VERSION "HNNBNNNYNNNNNNNNNNNNNNNNNNNNNNNNNNNNNNNNNN/4/%%%/4/'%**4NNN///"

NS_ :

BS_:

BU_: BAP_Tester ELV Gateway_Max HUD Kombi

BO_ 1426 Kessy_04: 8 Gateway_Max
 SG_ KY_ID_Geber1_im_Fzg : 12|1@1+ (1.0,0.0) [0.0|1] ""  Vector__XXX
 SG_ KY_ID_Geber2_im_Fzg : 13|1@1+ (1.0,0.0) [0.0|1] ""  Vector__XXX
 SG_ KY_ID_Geber3_im_Fzg : 14|1@1+ (1.0,0.0) [0.0|1] ""  Vector__XXX
 SG_ KY_ID_Geber4_im_Fzg : 15|1@1+ (1.0,0.0) [0.0|1] ""  Vector__XXX
 SG_ KY_Startknopf_Bel : 16|1@1+ (1.0,0.0) [0.0|1] ""  Vector__XXX
 SG_ KY_ID_Geber_Suche : 17|1@1+ (1.0,0.0) [0.0|1] ""  Vector__XXX
 SG_ KY_Meldungen : 18|4@1+ (1.0,0.0) [0.0|15] ""  Vector__XXX
 SG_ KY_Gong_600 : 22|1@1+ (1.0,0.0) [0.0|1] ""  Vector__XXX
 SG_ KY_Passiv_Autolock_Menue : 23|1@1+ (1.0,0.0) [0.0|1] ""  Vector__XXX
 SG_ KY_Passiv_Autolock_Akt : 24|1@1+ (1.0,0.0) [0.0|1] ""  Vector__XXX
 SG_ KY_Passiv_Autolock : 25|1@1+ (1.0,0.0) [0.0|1] ""  Vector__XXX
 SG_ KY_Passiv_Autounlock : 26|1@1+ (1.0,0.0) [0.0|1] ""  Vector__XXX
 SG_ KY_Gestik_HD : 27|1@1+ (1.0,0.0) [0.0|1] ""  Vector__XXX
 SG_ KY_StartStopp_Info : 28|2@1+ (1.0,0.0) [0.0|3] ""  Vector__XXX
 SG_ KY_Fzg_Verlassen_erkannt : 30|1@1+ (1.0,0.0) [0.0|1] ""  ELV
 SG_ KY_Fzg_Zugang_erkannt : 31|1@1+ (1.0,0.0) [0.0|1] ""  ELV
 SG_ KY_EasyClose_Abbruch : 32|1@1+ (1.0,0.0) [0.0|1] ""  Vector__XXX
 SG_ KY_EasyClose_Status : 33|3@1+ (1.0,0.0) [0.0|7] ""  Vector__XXX
 SG_ KY_HD_Auffahrt : 36|1@1+ (1.0,0.0) [0.0|1] ""  Vector__XXX
 SG_ KY_HD_Zufahrt : 37|1@1+ (1.0,0.0) [0.0|1] ""  Vector__XXX
 SG_ KY_Aktive_LFScans : 38|4@1+ (1.0,0.0) [0.0|15] ""  Vector__XXX
 SG_ KY_LF_Aktiv : 42|1@1+ (1.0,0.0) [0.0|1] ""  Vector__XXX
 SG_ KY_AnzKoord_Info : 43|2@1+ (1.0,0.0) [0.0|3] ""  Vector__XXX
 SG_ KY_Schluesselposition_9 : 45|2@1+ (1.0,0.0) [0.0|3] ""  Vector__XXX
 SG_ KY_Schluesselposition_1 : 48|2@1+ (1.0,0.0) [0.0|3] ""  Vector__XXX
 SG_ KY_Schluesselposition_2 : 50|2@1+ (1.0,0.0) [0.0|3] ""  Vector__XXX
 SG_ KY_Schluesselposition_3 : 52|2@1+ (1.0,0.0) [0.0|3] ""  Vector__XXX
 SG_ KY_Schluesselposition_4 : 54|2@1+ (1.0,0.0) [0.0|3] ""  Vector__XXX
 SG_ KY_Schluesselposition_5 : 56|2@1+ (1.0,0.0) [0.0|3] ""  Vector__XXX
 SG_ KY_Schluesselposition_6 : 58|2@1+ (1.0,0.0) [0.0|3] ""  Vector__XXX
 SG_ KY_Schluesselposition_7 : 60|2@1+ (1.0,0.0) [0.0|3] ""  Vector__XXX
 SG_ KY_Schluesselposition_8 : 62|2@1+ (1.0,0.0) [0.0|3] ""  Vector__XXX

BO_ 960 Klemmen_Status_01: 4 Gateway_Max
 SG_ Klemmen_Status_01_CRC : 0|8@1+ (1,0) [0|255] ""  ELV,Kombi
 SG_ Klemmen_Status_01_BZ : 8|4@1+ (1,0) [0|15] ""  ELV,Kombi
 SG_ RSt_Fahrerhinweise : 12|4@1+ (1.0,0.0) [0.0|15] ""  Kombi
 SG_ ZAS_Kl_S : 16|1@1+ (1.0,0.0) [0.0|1] ""  ELV,Kombi
 SG_ ZAS_Kl_15 : 17|1@1+ (1.0,0.0) [0.0|1] ""  ELV,HUD,Kombi
 SG_ ZAS_Kl_X : 18|1@1+ (1.0,0.0) [0.0|1] ""  Vector__XXX
 SG_ ZAS_Kl_50_Startanforderung : 19|1@1+ (1.0,0.0) [0.0|1] ""  Vector__XXX
 SG_ BCM_Remotestart_Betrieb : 20|1@1+ (1.0,0.0) [0.0|1] ""  Vector__XXX
 SG_ ZAS_Kl_Infotainment : 21|1@1+ (1.0,0.0) [0.0|1] ""  Vector__XXX
 SG_ BCM_Remotestart_KL15_Anf : 22|1@1+ (1.0,0.0) [0.0|1] ""  ELV,Kombi
 SG_ BCM_Remotestart_MO_Start : 23|1@1+ (1.0,0.0) [0.0|1] ""  Vector__XXX
 SG_ KST_Warn_P1_ZST_def : 24|1@1+ (1.0,0.0) [0.0|1] ""  Vector__XXX
 SG_ KST_Warn_P2_ZST_def : 25|1@1+ (1.0,0.0) [0.0|1] ""  Kombi
 SG_ KST_Fahrerhinweis_1 : 26|1@1+ (1.0,0.0) [0.0|1] ""  Vector__XXX
 SG_ KST_Fahrerhinweis_2 : 27|1@1+ (1.0,0.0) [0.0|1] ""  Kombi
 SG_ BCM_Ausparken_Betrieb : 28|1@1+ (1.0,0.0) [0.0|1] ""  Vector__XXX
 SG_ KST_Fahrerhinweis_4 : 29|1@1+ (1.0,0.0) [0.0|1] ""  Vector__XXX
 SG_ KST_Fahrerhinweis_5 : 30|1@1+ (1.0,0.0) [0.0|1] ""  Vector__XXX
 SG_ KST_Fahrerhinweis_6 : 31|1@1+ (1.0,0.0) [0.0|1] ""  Kombi

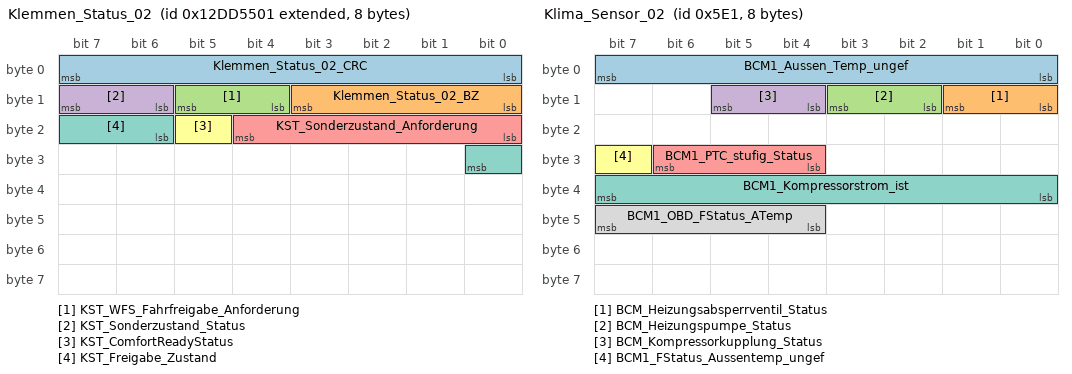
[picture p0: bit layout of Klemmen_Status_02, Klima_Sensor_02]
BO_ 2463978753 Klemmen_Status_02: 8 Gateway_Max
 SG_ Klemmen_Status_02_CRC : 0|8@1+ (1,0) [0|255] ""  Vector__XXX
 SG_ Klemmen_Status_02_BZ : 8|4@1+ (1,0) [0|15] ""  Vector__XXX
 SG_ KST_WFS_Fahrfreigabe_Anforderung : 12|2@1+ (1.0,0.0) [0.0|3] ""  Vector__XXX
 SG_ KST_Sonderzustand_Status : 14|2@1+ (1.0,0.0) [0.0|3] ""  ELV
 SG_ KST_Sonderzustand_Anforderung : 16|5@1+ (1.0,0.0) [0.0|31] ""  ELV
 SG_ KST_ComfortReadyStatus : 21|1@1+ (1.0,0.0) [0.0|1] ""  Vector__XXX
 SG_ KST_Freigabe_Zustand : 22|3@1+ (1.0,0.0) [0.0|7] ""  Vector__XXX

BO_ 1420 Klemmen_Steuerung_01: 8 Gateway_Max
 SG_ Klemmen_Steuerung_01_CRC : 0|8@1+ (1,0) [0|255] ""  ELV
 SG_ Klemmen_Steuerung_01_BZ : 8|4@1+ (1,0) [0|15] ""  ELV
 SG_ KST_Anf_Klemme_15 : 12|1@1+ (1.0,0.0) [0.0|1] ""  Vector__XXX
 SG_ KST_Anf_Klemme_50 : 13|1@1+ (1.0,0.0) [0.0|1] ""  Vector__XXX
 SG_ KST_Anf_Klemme_S : 14|1@1+ (1.0,0.0) [0.0|1] ""  Vector__XXX
 SG_ KST_Txt_Werkstatt : 15|1@1+ (1.0,0.0) [0.0|1] ""  Kombi
 SG_ KST_Txt_P_Gang : 16|1@1+ (1.0,0.0) [0.0|1] ""  Kombi
 SG_ KST_Txt_Panikabschaltung : 17|1@1+ (1.0,0.0) [0.0|1] ""  Kombi
 SG_ KST_Anf_Klemmenfreigabe_ELV : 18|1@1+ (1.0,0.0) [0.0|1] ""  ELV
 SG_ KST_Txt_Komfortabschaltung : 19|1@1+ (1.0,0.0) [0.0|1] ""  Kombi
 SG_ KST_ZAT_betaetigt : 20|1@1+ (1.0,0.0) [0.0|1] ""  Vector__XXX
 SG_ KST_Unterdr_Zuendungsmeldung : 21|1@1+ (1.0,0.0) [0.0|1] ""  Vector__XXX
 SG_ KST_aut_Abschaltung_Zuendung : 22|1@1+ (1.0,0.0) [0.0|1] ""  Vector__XXX
 SG_ KST_Anf_Klemmenfreigabe_WFS : 23|1@1+ (1.0,0.0) [0.0|1] ""  Vector__XXX
 SG_ KST_Anf_ZV_Verriegelung : 24|1@1+ (1.0,0.0) [0.0|1] ""  Vector__XXX
 SG_ Relais_VoKo_angesteuert : 25|1@1+ (1.0,0.0) [0.0|1] ""  Vector__XXX
 SG_ RSt_Anforderung_HMS : 26|3@1+ (1.0,0.0) [0.0|7] ""  Vector__XXX
 SG_ KST_Zuendungswarnung : 29|2@1+ (1.0,0.0) [0.0|3] ""  Kombi
 SG_ KST_Anzeige_Klemmenzustand : 36|3@1+ (1.0,0.0) [0.0|7] ""  Kombi

BO_ 1646 Klima_03: 8 Gateway_Max
 SG_ KL_STL_aktiv : 0|1@1+ (1.0,0.0) [0.0|1] ""  Vector__XXX
 SG_ KL_STH_aktiv : 1|1@1+ (1.0,0.0) [0.0|1] ""  Vector__XXX
 SG_ KL_Solarluefter_aktiv : 2|1@1+ (1.0,0.0) [0.0|1] ""  Vector__XXX
 SG_ KL_Umluft_Taste : 3|1@1+ (1.0,0.0) [0.0|1] ""  Vector__XXX
 SG_ KL_Geblaese_Fond_Status : 4|4@1+ (1.0,0.0) [0.0|15] ""  Vector__XXX
 SG_ KL_STH_Ansteuerung : 8|2@1+ (1.0,0.0) [0.0|3] ""  Vector__XXX
 SG_ KL_STH_Betriebsdauer : 10|6@1+ (1,0) [0|60] "Unit_Minut"  Vector__XXX
 SG_ KL_Magnetventil : 16|1@1+ (1.0,0.0) [0.0|1] ""  Vector__XXX
 SG_ KL_WaPu : 17|1@1+ (1.0,0.0) [0.0|1] ""  Vector__XXX
 SG_ KL_Geblaese_Status : 18|4@1+ (1.0,0.0) [0.0|15] ""  Kombi
 SG_ KL_Restwaerme_aktiv : 22|1@1+ (1.0,0.0) [0.0|1] ""  Vector__XXX
 SG_ KL_Kompressorkupplung : 23|1@1+ (1.0,0.0) [0.0|1] ""  Vector__XXX
 SG_ KL_BCmE_Livetip_Freigabe : 24|1@1+ (1.0,0.0) [0.0|1] ""  Vector__XXX
 SG_ KL_SH_Soll_hl : 25|3@1+ (1.0,0.0) [0.0|7] ""  Vector__XXX
 SG_ KL_SH_Soll_hr : 28|3@1+ (1.0,0.0) [0.0|7] ""  Vector__XXX
 SG_ KL_ErwVK_Anf : 31|1@1+ (1.0,0.0) [0.0|1] ""  Vector__XXX
 SG_ KL_Innen_Temp : 32|8@1+ (0.5,-50) [-50.0|76.0] "Unit_DegreCelsi"  Vector__XXX
 SG_ KL_I_Geblaese_Fond : 40|8@1+ (0.25,0) [0.00|63.50] "Unit_Amper"  Vector__XXX
 SG_ KL_Anf_AussenspiegelHzg : 48|1@1+ (1.0,0.0) [0.0|1] ""  Vector__XXX
 SG_ KL_Heizkreisventilstellung : 49|2@1+ (1.0,0.0) [0.0|3] ""  Vector__XXX
 SG_ KL_FSH_Automatikbetrieb : 51|1@1+ (1.0,0.0) [0.0|1] ""  Vector__XXX
 SG_ KL_SIH_LEH_Verteilung_VL : 52|3@1+ (1.0,0.0) [0.0|7] ""  Vector__XXX
 SG_ KL_SIH_LEL_Verteilung_VL : 55|3@1+ (1.0,0.0) [0.0|7] ""  Vector__XXX
 SG_ KL_SIH_LEH_Verteilung_VR : 58|3@1+ (1.0,0.0) [0.0|7] ""  Vector__XXX
 SG_ KL_SIH_LEL_Verteilung_VR : 61|3@1+ (1.0,0.0) [0.0|7] ""  Vector__XXX

BO_ 949 Klima_11: 8 Gateway_Max
 SG_ KL_Drehz_Anh : 0|1@1+ (1.0,0.0) [0.0|1] ""  Vector__XXX
 SG_ KL_Vorwarn_Komp_ein : 1|1@1+ (1.0,0.0) [0.0|1] ""  Vector__XXX
 SG_ KL_AC_Schalter : 2|1@1+ (1.0,0.0) [0.0|1] ""  Vector__XXX
 SG_ KL_Komp_Moment_alt : 3|1@1+ (1.0,0.0) [0.0|1] ""  Vector__XXX
 SG_ KL_Vorwarn_Zuheizer_ein : 6|1@1+ (1.0,0.0) [0.0|1] ""  Vector__XXX
 SG_ KL_Zustand : 7|1@1+ (1.0,0.0) [0.0|1] ""  Vector__XXX
 SG_ KL_Kompressorkupplung_linear : 8|8@1+ (20,0) [0|4000] "Unit_MilliAmper"  Vector__XXX
 SG_ KL_Charisma_FahrPr : 16|4@1+ (1.0,0.0) [0.0|15] ""  Vector__XXX
 SG_ KL_Charisma_Status : 20|2@1+ (1.0,0.0) [0.0|3] ""  Vector__XXX
 SG_ KL_nachtr_Stopp_Anf : 22|1@1+ (1.0,0.0) [0.0|1] ""  Vector__XXX
 SG_ KL_T_Charge : 23|1@1+ (1.0,0.0) [0.0|1] ""  Vector__XXX
 SG_ KL_Last_Kompr : 24|8@1+ (0.25,0) [0.00|63.50] "Unit_NewtoMeter"  Vector__XXX
 SG_ KL_Spannungs_Anf : 32|2@1+ (1.0,0.0) [0.0|3] ""  Vector__XXX
 SG_ KL_Thermomanagement : 34|2@1+ (1.0,0.0) [0.0|3] ""  Vector__XXX
 SG_ KL_StartStopp_Info : 36|2@1+ (1.0,0.0) [0.0|3] ""  Vector__XXX
 SG_ KL_Freilauf_Info : 38|2@1+ (1.0,0.0) [0.0|3] ""  Vector__XXX
 SG_ KL_Anf_KL : 40|8@1+ (0.4,0) [0.0|101.6] "Unit_PerCent"  Vector__XXX
 SG_ KL_el_Zuheizer_Stufe : 48|3@1+ (1.0,0.0) [0.0|7] ""  Vector__XXX
 SG_ KL_Ausstattung_Klima : 51|3@1+ (1.0,0.0) [0.0|7] ""  Vector__XXX
 SG_ KL_Variante_Standheizung : 54|2@1+ (1.0,0.0) [0.0|3] ""  Vector__XXX
 SG_ KL_AirCleaner_aktiv : 56|1@1+ (1.0,0.0) [0.0|1] ""  Vector__XXX
 SG_ KL_Anf_KV : 57|7@1+ (1,0) [0|100] "Unit_PerCent"  Vector__XXX

BO_ 1640 Klima_12: 8 Gateway_Max
 SG_ KL_LRH_Taster : 0|1@1+ (1.0,0.0) [0.0|1] ""  Vector__XXX
 SG_ KL_LRH_Stufe : 1|2@1+ (1.0,0.0) [0.0|3] ""  Kombi
 SG_ HSH_Taster : 3|2@1+ (1.0,0.0) [0.0|3] ""  Vector__XXX
 SG_ FSH_Taster : 5|1@1+ (1.0,0.0) [0.0|1] ""  Vector__XXX
 SG_ KL_Zuheizer_Freigabe : 6|1@1+ (1.0,0.0) [0.0|1] ""  Vector__XXX
 SG_ KL_Beschlagsgefahr : 7|1@1+ (1.0,0.0) [0.0|1] ""  Vector__XXX
 SG_ KL_SIH_Soll_li : 8|3@1+ (1,0) [0|6] ""  Vector__XXX
 SG_ KL_SIH_Soll_re : 11|3@1+ (1,0) [0|6] ""  Vector__XXX
 SG_ KRH_Soll_li : 14|2@1+ (1.0,0.0) [0.0|3] ""  Vector__XXX
 SG_ KL_SIL_Soll_li : 16|3@1+ (1,0) [0|6] ""  Vector__XXX
 SG_ KL_SIL_Soll_re : 19|3@1+ (1,0) [0|6] ""  Vector__XXX
 SG_ KRH_Soll_re : 22|2@1+ (1.0,0.0) [0.0|3] ""  Vector__XXX
 SG_ KL_Geblspng_Soll : 24|8@1+ (0.05,1.45) [1.50|14.00] "Unit_Volt"  Vector__XXX
 SG_ KL_Geblspng_Fond_Soll : 32|8@1+ (0.05,1.45) [1.50|14.00] "Unit_Volt"  Vector__XXX
 SG_ KL_I_Geblaese : 40|8@1+ (0.25,0) [0.00|63.50] "Unit_Amper"  Vector__XXX
 SG_ KL_Kompressorstrom_soll : 48|10@1+ (1,0) [0|1021] ""  Vector__XXX
 SG_ KL_Umluftklappe_Status : 58|4@1+ (1.0,0.0) [0.0|15] ""  Vector__XXX
 SG_ KL_PTC_Verbauinfo : 62|2@1+ (1.0,0.0) [0.0|3] ""  Vector__XXX

BO_ 2527679635 Klima_16: 8 Gateway_Max
 SG_ KL_Voko_Status : 0|4@1+ (1.0,0.0) [0.0|15] ""  Vector__XXX
 SG_ KL_LRH_PWM : 4|7@1+ (1,0) [0|100] "Unit_PerCent"  Vector__XXX
 SG_ KL_LRH_Soll : 11|1@1+ (1.0,0.0) [0.0|1] ""  Vector__XXX
 SG_ KL_AL_VR_Anf : 12|2@1+ (1.0,0.0) [0.0|3] ""  Vector__XXX
 SG_ KL_AL_VL_Anf : 14|2@1+ (1.0,0.0) [0.0|3] ""  Vector__XXX
 SG_ KL_AL_HR_Anf : 16|2@1+ (1.0,0.0) [0.0|3] ""  Vector__XXX
 SG_ KL_AL_HL_Anf : 18|2@1+ (1.0,0.0) [0.0|3] ""  Vector__XXX
 SG_ KL_HSH_Soll : 20|1@1+ (1.0,0.0) [0.0|1] ""  Vector__XXX
 SG_ KL_FSH_Soll : 21|1@1+ (1.0,0.0) [0.0|1] ""  Vector__XXX
 SG_ KL_ZR_Anforderung : 22|2@1+ (1.0,0.0) [0.0|3] ""  Vector__XXX
 SG_ KL_VoKo_LED : 24|1@1+ (1.0,0.0) [0.0|1] ""  Vector__XXX
 SG_ KL_Defrost_LED : 25|1@1+ (1.0,0.0) [0.0|1] ""  Vector__XXX
 SG_ KL_HSH_LED : 26|1@1+ (1.0,0.0) [0.0|1] ""  Vector__XXX
 SG_ HSH_Relais_Anf : 27|1@1+ (1.0,0.0) [0.0|1] ""  Vector__XXX
 SG_ FSH_Status : 28|2@1+ (1.0,0.0) [0.0|3] ""  Vector__XXX
 SG_ SIH_Stufe_LED_li : 30|3@1+ (1.0,0.0) [0.0|7] ""  Vector__XXX
 SG_ SIH_Stufe_LED_re : 33|3@1+ (1.0,0.0) [0.0|7] ""  Vector__XXX
 SG_ KL_FSH_LED : 36|1@1+ (1.0,0.0) [0.0|1] ""  Vector__XXX
 SG_ KL_HUP_aktiv : 37|1@1+ (1.0,0.0) [0.0|1] ""  Vector__XXX
 SG_ KL_LSH_DBetr_Ein : 38|1@1+ (1.0,0.0) [0.0|1] ""  Vector__XXX
 SG_ KL_LSH_DBetr_Bestaet : 39|1@1+ (1.0,0.0) [0.0|1] ""  Vector__XXX
 SG_ KL_Klappe_Status : 40|3@1+ (1.0,0.0) [0.0|7] ""  Vector__XXX
 SG_ KL_LSH_Ansteuerung : 43|2@1+ (1.0,0.0) [0.0|3] ""  Vector__XXX
 SG_ KL_Heizstufe_LSH : 45|4@1+ (1.0,0.0) [0.0|15] ""  Vector__XXX
 SG_ KL_LSH_Betriebsdauer : 49|7@1+ (1,0) [0|120] "Unit_Minut"  Vector__XXX
 SG_ KL_Temp_ZH_Soll : 56|8@1+ (0.5,0) [0.5|127.0] "Unit_DegreCelsi"  Vector__XXX

BO_ 1505 Klima_Sensor_02: 8 Gateway_Max
 SG_ BCM1_Aussen_Temp_ungef : 0|8@1+ (0.5,-50) [-50.0|76.0] "Unit_DegreCelsi"  Kombi
 SG_ BCM_Heizungsabsperrventil_Status : 8|2@1+ (1.0,0.0) [0.0|3] ""  Vector__XXX
 SG_ BCM_Heizungspumpe_Status : 10|2@1+ (1.0,0.0) [0.0|3] ""  Vector__XXX
 SG_ BCM_Kompressorkupplung_Status : 12|2@1+ (1.0,0.0) [0.0|3] ""  Vector__XXX
 SG_ BCM1_PTC_stufig_Status : 28|3@1+ (1.0,0.0) [0.0|7] ""  Vector__XXX
 SG_ BCM1_FStatus_Aussentemp_ungef : 31|1@1+ (1.0,0.0) [0.0|1] ""  Kombi
 SG_ BCM1_Kompressorstrom_ist : 32|8@1+ (4,0) [0|1000] "Unit_MilliAmper"  Vector__XXX
 SG_ BCM1_OBD_FStatus_ATemp : 44|4@1+ (1.0,0.0) [0.0|15] ""  Vector__XXX

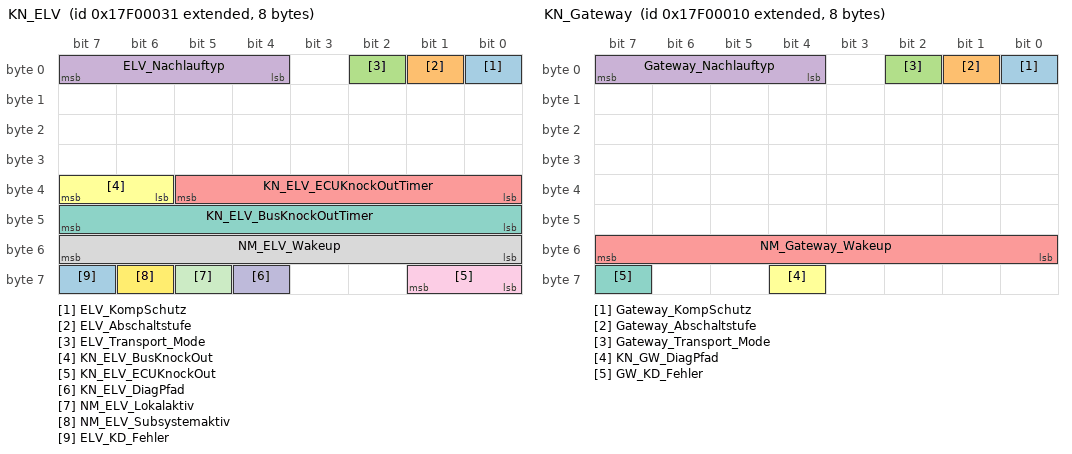
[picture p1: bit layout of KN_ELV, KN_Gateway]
BO_ 2549088305 KN_ELV: 8 ELV
 SG_ ELV_KompSchutz : 0|1@1+ (1.0,0.0) [0.0|1] ""  Vector__XXX
 SG_ ELV_Abschaltstufe : 1|1@1+ (1.0,0.0) [0.0|1] ""  Vector__XXX
 SG_ ELV_Transport_Mode : 2|1@1+ (1.0,0.0) [0.0|1] ""  Vector__XXX
 SG_ ELV_Nachlauftyp : 4|4@1+ (1.0,0.0) [0.0|15] ""  Gateway_Max
 SG_ KN_ELV_ECUKnockOutTimer : 32|6@1+ (1,0) [0|62] ""  Vector__XXX
 SG_ KN_ELV_BusKnockOut : 38|2@1+ (1.0,0.0) [0.0|3] ""  Vector__XXX
 SG_ KN_ELV_BusKnockOutTimer : 40|8@1+ (1,0) [0|254] ""  Vector__XXX
 SG_ NM_ELV_Wakeup : 48|8@1+ (1.0,0.0) [0.0|255] ""  Vector__XXX
 SG_ KN_ELV_ECUKnockOut : 56|2@1+ (1.0,0.0) [0.0|3] ""  Vector__XXX
 SG_ KN_ELV_DiagPfad : 60|1@1+ (1.0,0.0) [0.0|1] ""  Gateway_Max
 SG_ NM_ELV_Lokalaktiv : 61|1@1+ (1.0,0.0) [0.0|1] ""  Vector__XXX
 SG_ NM_ELV_Subsystemaktiv : 62|1@1+ (1.0,0.0) [0.0|1] ""  Vector__XXX
 SG_ ELV_KD_Fehler : 63|1@1+ (1.0,0.0) [0.0|1] ""  Gateway_Max

BO_ 2549088272 KN_Gateway: 8 Gateway_Max
 SG_ Gateway_KompSchutz : 0|1@1+ (1.0,0.0) [0.0|1] ""  Vector__XXX
 SG_ Gateway_Abschaltstufe : 1|1@1+ (1.0,0.0) [0.0|1] ""  Vector__XXX
 SG_ Gateway_Transport_Mode : 2|1@1+ (1.0,0.0) [0.0|1] ""  Vector__XXX
 SG_ Gateway_Nachlauftyp : 4|4@1+ (1.0,0.0) [0.0|15] ""  Vector__XXX
 SG_ NM_Gateway_Wakeup : 48|8@1+ (1.0,0.0) [0.0|255] ""  Vector__XXX
 SG_ KN_GW_DiagPfad : 60|1@1+ (1.0,0.0) [0.0|1] ""  Vector__XXX
 SG_ GW_KD_Fehler : 63|1@1+ (1.0,0.0) [0.0|1] ""  Vector__XXX

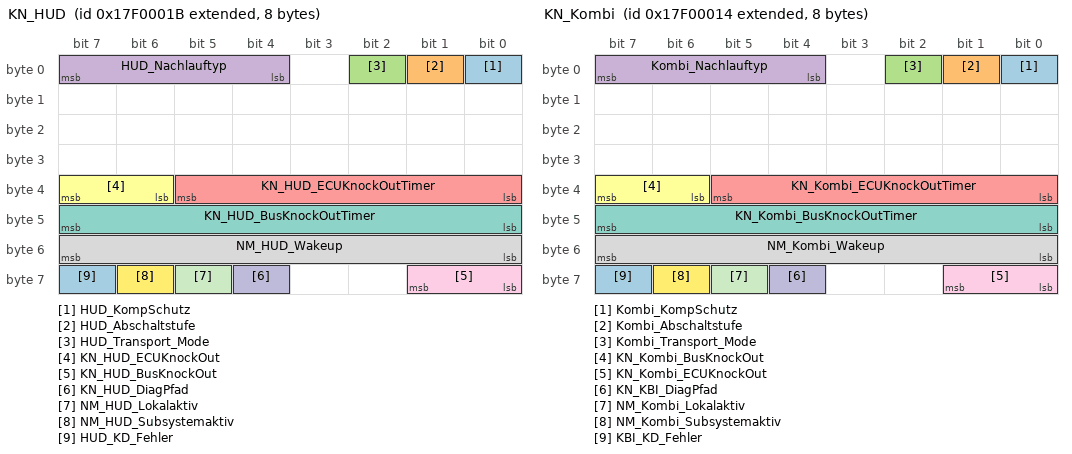
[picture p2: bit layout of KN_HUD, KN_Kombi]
BO_ 2549088283 KN_HUD: 8 HUD
 SG_ HUD_KompSchutz : 0|1@1+ (1.0,0.0) [0.0|1] ""  Vector__XXX
 SG_ HUD_Abschaltstufe : 1|1@1+ (1.0,0.0) [0.0|1] ""  Vector__XXX
 SG_ HUD_Transport_Mode : 2|1@1+ (1.0,0.0) [0.0|1] ""  Vector__XXX
 SG_ HUD_Nachlauftyp : 4|4@1+ (1.0,0.0) [0.0|15] ""  Gateway_Max
 SG_ KN_HUD_ECUKnockOutTimer : 32|6@1+ (1,0) [0|62] "Unit_Minut"  Vector__XXX
 SG_ KN_HUD_ECUKnockOut : 38|2@1+ (1.0,0.0) [0.0|3] ""  Vector__XXX
 SG_ KN_HUD_BusKnockOutTimer : 40|8@1+ (1,0) [0|254] "Unit_Minut"  Vector__XXX
 SG_ NM_HUD_Wakeup : 48|8@1+ (1.0,0.0) [0.0|255] ""  Vector__XXX
 SG_ KN_HUD_BusKnockOut : 56|2@1+ (1.0,0.0) [0.0|3] ""  Vector__XXX
 SG_ KN_HUD_DiagPfad : 60|1@1+ (1.0,0.0) [0.0|1] ""  Gateway_Max
 SG_ NM_HUD_Lokalaktiv : 61|1@1+ (1.0,0.0) [0.0|1] ""  Vector__XXX
 SG_ NM_HUD_Subsystemaktiv : 62|1@1+ (1.0,0.0) [0.0|1] ""  Vector__XXX
 SG_ HUD_KD_Fehler : 63|1@1+ (1.0,0.0) [0.0|1] ""  Gateway_Max

BO_ 2549088276 KN_Kombi: 8 Kombi
 SG_ Kombi_KompSchutz : 0|1@1+ (1.0,0.0) [0.0|1] ""  Vector__XXX
 SG_ Kombi_Abschaltstufe : 1|1@1+ (1.0,0.0) [0.0|1] ""  Vector__XXX
 SG_ Kombi_Transport_Mode : 2|1@1+ (1.0,0.0) [0.0|1] ""  Vector__XXX
 SG_ Kombi_Nachlauftyp : 4|4@1+ (1.0,0.0) [0.0|15] ""  Gateway_Max
 SG_ KN_Kombi_ECUKnockOutTimer : 32|6@1+ (1,0) [0|62] "Unit_Minut"  Vector__XXX
 SG_ KN_Kombi_BusKnockOut : 38|2@1+ (1.0,0.0) [0.0|3] ""  Vector__XXX
 SG_ KN_Kombi_BusKnockOutTimer : 40|8@1+ (1,0) [0|254] ""  Vector__XXX
 SG_ NM_Kombi_Wakeup : 48|8@1+ (1.0,0.0) [0.0|255] ""  Vector__XXX
 SG_ KN_Kombi_ECUKnockOut : 56|2@1+ (1.0,0.0) [0.0|3] ""  Vector__XXX
 SG_ KN_KBI_DiagPfad : 60|1@1+ (1.0,0.0) [0.0|1] ""  Gateway_Max
 SG_ NM_Kombi_Lokalaktiv : 61|1@1+ (1.0,0.0) [0.0|1] ""  Vector__XXX
 SG_ NM_Kombi_Subsystemaktiv : 62|1@1+ (1.0,0.0) [0.0|1] ""  Vector__XXX
 SG_ KBI_KD_Fehler : 63|1@1+ (1.0,0.0) [0.0|1] ""  Gateway_Max

BO_ 779 Kombi_01: 8 Kombi
 SG_ KBI_ABS_Lampe : 0|1@1+ (1.0,0.0) [0.0|1] ""  Gateway_Max
 SG_ KBI_ESP_Lampe : 1|1@1+ (1.0,0.0) [0.0|1] ""  Gateway_Max
 SG_ KBI_BKL_Lampe : 2|1@1+ (1.0,0.0) [0.0|1] ""  Gateway_Max
 SG_ KBI_Airbag_Lampe : 3|1@1+ (1.0,0.0) [0.0|1] ""  Gateway_Max
 SG_ KBI_SILA_gueltig : 4|1@1+ (1.0,0.0) [0.0|1] ""  Gateway_Max
 SG_ KBI_Lenkung_Lampe : 5|1@1+ (1,0) [0|1] ""  Gateway_Max
 SG_ KBI_Vorglueh_System_Lampe : 6|1@1+ (1.0,0.0) [0.0|1] ""  Gateway_Max
 SG_ KBI_NV_in_Anzeige : 7|1@1+ (1.0,0.0) [0.0|1] ""  Gateway_Max
 SG_ Kombi_01_BZ : 8|4@1+ (1,0) [0|15] ""  Gateway_Max
 SG_ KBI_Anzeigestatus_ACC : 12|1@1+ (1.0,0.0) [0.0|1] ""  Gateway_Max
 SG_ KBI_Anzeigestatus_GRA : 13|2@1+ (1.0,0.0) [0.0|3] ""  Gateway_Max
 SG_ KBI_Oeldruck_Schalter : 15|1@1+ (1.0,0.0) [0.0|1] ""  Gateway_Max
 SG_ KBI_Tankwarnung : 16|1@1+ (1.0,0.0) [0.0|1] ""  Gateway_Max
 SG_ KBI_MFA_v_Einheit_01 : 17|1@1+ (1.0,0.0) [0.0|1] ""  Gateway_Max,HUD
 SG_ KBI_im_Stellgliedtest : 18|1@1+ (1.0,0.0) [0.0|1] ""  Gateway_Max
 SG_ KBI_Anzeigefehler_LDW : 19|2@1+ (1.0,0.0) [0.0|3] ""  Gateway_Max
 SG_ KBI_Tankwarnung_ungueltig : 21|1@1+ (1.0,0.0) [0.0|1] ""  Gateway_Max
 SG_ KBI_Oeldruckwarnung : 22|1@1+ (1.0,0.0) [0.0|1] ""  Gateway_Max
 SG_ KBI_Handbremse : 23|1@1+ (1.0,0.0) [0.0|1] ""  Gateway_Max
 SG_ KBI_V_Digital : 24|9@1+ (1,0) [0|511] ""  Gateway_Max,HUD
 SG_ KBI_PLA_in_Anzeige : 33|1@1+ (1.0,0.0) [0.0|1] ""  Gateway_Max
 SG_ KBI_Anzeigefehler_NV : 34|1@1+ (1.0,0.0) [0.0|1] ""  Gateway_Max
 SG_ KBI_Anzeigestatus_LIM : 35|2@1+ (1.0,0.0) [0.0|3] ""  Gateway_Max
 SG_ KBI_ARA_in_Anzeige : 37|1@1+ (1.0,0.0) [0.0|1] ""  Gateway_Max
 SG_ KBI_Taster_Lift : 38|1@1+ (1.0,0.0) [0.0|1] ""  Gateway_Max
 SG_ KBI_Taster_Fahrwerk : 39|1@1+ (1.0,0.0) [0.0|1] ""  Gateway_Max
 SG_ KBI_Audioabsenkung_MIB : 40|2@1+ (1.0,0.0) [0.0|3] ""  Gateway_Max
 SG_ KBI_Bestaetigung_ESP_Off : 42|2@1+ (1.0,0.0) [0.0|3] ""  Gateway_Max
 SG_ KBI_Anzeigestatus_RHP : 44|2@1+ (1.0,0.0) [0.0|3] ""  Gateway_Max
 SG_ KBI_angez_Geschw : 48|10@1+ (0.32,0) [0.00|325.12] "Unit_KiloMeterPerHour"  Gateway_Max
 SG_ KBI_Konsistenz_ACC : 59|1@1+ (1.0,0.0) [0.0|1] ""  Gateway_Max
 SG_ KBI_Fehler_Anzeige_ACC : 60|1@1+ (1.0,0.0) [0.0|1] ""  Gateway_Max
 SG_ KBI_Anzeigefehler_SWA : 61|2@1+ (1.0,0.0) [0.0|3] ""  Gateway_Max
 SG_ KBI_Systemstatus : 63|1@1+ (1.0,0.0) [0.0|1] ""  Gateway_Max

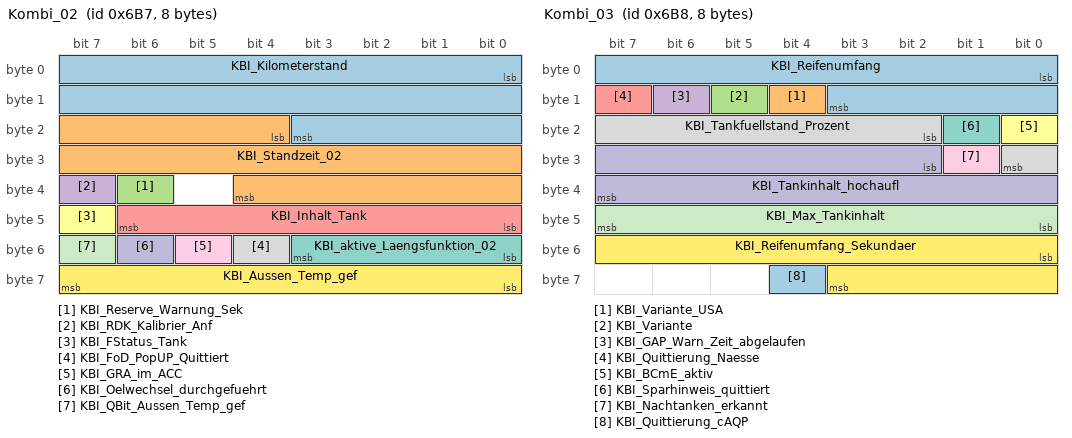
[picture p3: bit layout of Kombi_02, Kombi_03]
BO_ 1719 Kombi_02: 8 Kombi
 SG_ KBI_Kilometerstand : 0|20@1+ (1,0) [0|1048573] "Unit_KiloMeter"  Gateway_Max
 SG_ KBI_Standzeit_02 : 20|17@1+ (1,0) [0|131068] "Unit_Secon"  Gateway_Max
 SG_ KBI_Reserve_Warnung_Sek : 38|1@1+ (1.0,0.0) [0.0|1] ""  Gateway_Max
 SG_ KBI_RDK_Kalibrier_Anf : 39|1@1+ (1.0,0.0) [0.0|1] ""  Gateway_Max
 SG_ KBI_Inhalt_Tank : 40|7@1+ (1,0) [0|125] "Unit_Liter"  Gateway_Max
 SG_ KBI_FStatus_Tank : 47|1@1+ (1.0,0.0) [0.0|1] ""  Gateway_Max
 SG_ KBI_aktive_Laengsfunktion_02 : 48|4@1+ (1.0,0.0) [0.0|15] ""  Gateway_Max
 SG_ KBI_FoD_PopUP_Quittiert : 52|1@1+ (1.0,0.0) [0.0|1] ""  Gateway_Max
 SG_ KBI_GRA_im_ACC : 53|1@1+ (1.0,0.0) [0.0|1] ""  Gateway_Max
 SG_ KBI_Oelwechsel_durchgefuehrt : 54|1@1+ (1.0,0.0) [0.0|1] ""  Gateway_Max
 SG_ KBI_QBit_Aussen_Temp_gef : 55|1@1+ (1.0,0.0) [0.0|1] ""  Gateway_Max
 SG_ KBI_Aussen_Temp_gef : 56|8@1+ (0.5,-50) [-50.0|75.0] "Unit_DegreCelsi"  Gateway_Max

BO_ 1720 Kombi_03: 8 Kombi
 SG_ KBI_Reifenumfang : 0|12@1+ (1,0) [0|4095] "Unit_MilliMeter"  Gateway_Max
 SG_ KBI_Variante_USA : 12|1@1+ (1.0,0.0) [0.0|1] ""  Gateway_Max
 SG_ KBI_Variante : 13|1@1+ (1.0,0.0) [0.0|1] ""  Gateway_Max
 SG_ KBI_GAP_Warn_Zeit_abgelaufen : 14|1@1+ (1.0,0.0) [0.0|1] ""  Gateway_Max
 SG_ KBI_Quittierung_Naesse : 15|1@1+ (1.0,0.0) [0.0|1] ""  Gateway_Max
 SG_ KBI_BCmE_aktiv : 16|1@1+ (1.0,0.0) [0.0|1] ""  Gateway_Max
 SG_ KBI_Sparhinweis_quittiert : 17|1@1+ (1.0,0.0) [0.0|1] ""  Gateway_Max
 SG_ KBI_Tankfuellstand_Prozent : 18|7@1+ (1,0) [0|100] "Unit_PerCent"  Gateway_Max
 SG_ KBI_Nachtanken_erkannt : 25|1@1+ (1.0,0.0) [0.0|1] ""  Gateway_Max
 SG_ KBI_Tankinhalt_hochaufl : 26|14@1+ (0.01,0) [0.00|163.81] "Unit_Liter"  Gateway_Max
 SG_ KBI_Max_Tankinhalt : 40|8@1+ (0.5,0) [0.0|126.5] ""  Gateway_Max
 SG_ KBI_Reifenumfang_Sekundaer : 48|12@1+ (1,0) [0|4095] "Unit_MilliMeter"  Gateway_Max
 SG_ KBI_Quittierung_cAQP : 60|1@1+ (1.0,0.0) [0.0|1] ""  Gateway_Max

BO_ 1722 Kombi_03_SOK_Signatur: 8 Kombi
 SG_ SOK_Kombi_03_Signatur : 0|64@1+ (1,0) [0|18446744073709551615] "Unit_None"  Gateway_Max

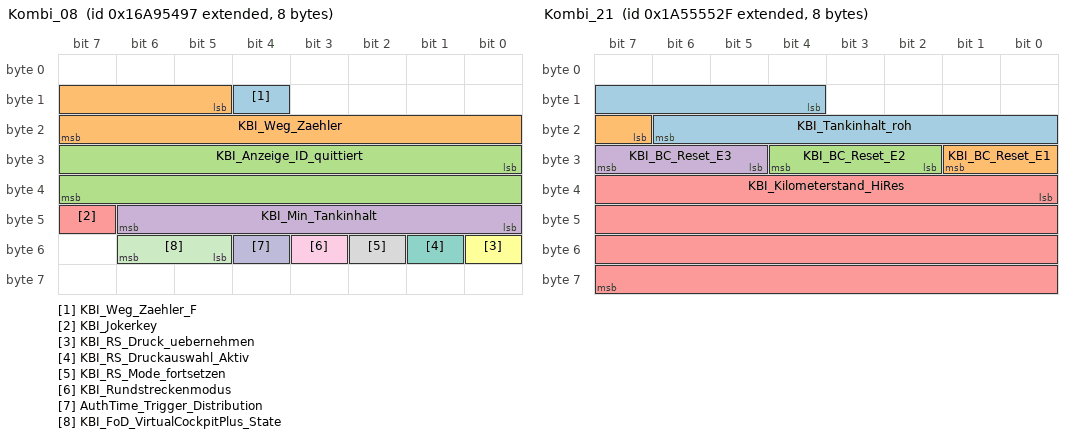
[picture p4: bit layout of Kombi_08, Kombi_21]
BO_ 2527679639 Kombi_08: 8 Kombi
 SG_ KBI_Weg_Zaehler_F : 12|1@1+ (1.0,0.0) [0.0|1] ""  Gateway_Max
 SG_ KBI_Weg_Zaehler : 13|11@1+ (1,0) [0|2047] "Unit_Meter"  Gateway_Max
 SG_ KBI_Anzeige_ID_quittiert : 24|16@1+ (1,0) [1|65336] "Unit_None"  Gateway_Max
 SG_ KBI_Min_Tankinhalt : 40|7@1+ (0.1,0) [0.0|12.5] "Unit_Liter"  Gateway_Max
 SG_ KBI_Jokerkey : 47|1@1+ (1.0,0.0) [0.0|1] ""  Gateway_Max
 SG_ KBI_RS_Druck_uebernehmen : 48|1@1+ (1.0,0.0) [0.0|1] ""  Gateway_Max
 SG_ KBI_RS_Druckauswahl_Aktiv : 49|1@1+ (1.0,0.0) [0.0|1] ""  Gateway_Max
 SG_ KBI_RS_Mode_fortsetzen : 50|1@1+ (1.0,0.0) [0.0|1] ""  Gateway_Max
 SG_ KBI_Rundstreckenmodus : 51|1@1+ (1.0,0.0) [0.0|1] ""  Gateway_Max
 SG_ AuthTime_Trigger_Distribution : 52|1@1+ (1.0,0.0) [0.0|1] ""  Gateway_Max
 SG_ KBI_FoD_VirtualCockpitPlus_State : 53|2@1+ (1.0,0.0) [0.0|3] ""  Gateway_Max

BO_ 2589283631 Kombi_21: 8 Kombi
 SG_ KBI_Tankinhalt_roh : 12|11@1+ (0.1,0) [0.0|204.5] "Unit_Liter"  Gateway_Max
 SG_ KBI_BC_Reset_E1 : 23|3@1+ (1.0,0.0) [0.0|7] ""  Gateway_Max
 SG_ KBI_BC_Reset_E2 : 26|3@1+ (1.0,0.0) [0.0|7] ""  Gateway_Max
 SG_ KBI_BC_Reset_E3 : 29|3@1+ (1.0,0.0) [0.0|7] ""  Gateway_Max
 SG_ KBI_Kilometerstand_HiRes : 32|32@1+ (0.1,0) [0.0|429496729.5] "Unit_KiloMeter"  Gateway_Max

BO_ 2527679656 Kombi_23: 8 Kombi
 SG_ KBI_StartupAnimation : 61|3@1+ (1.0,0.0) [0.0|7] ""  Gateway_Max

BO_ 2589283935 Kombi_ATM_01: 8 Kombi
 SG_ KBI_View1 : 12|1@1+ (1.0,0.0) [0.0|1] ""  Gateway_Max
 SG_ KBI_View2 : 13|1@1+ (1.0,0.0) [0.0|1] ""  Gateway_Max
 SG_ KBI_View3 : 14|1@1+ (1.0,0.0) [0.0|1] ""  Gateway_Max
 SG_ KBI_View4 : 15|1@1+ (1.0,0.0) [0.0|1] ""  Gateway_Max
 SG_ KBI_View5 : 16|1@1+ (1.0,0.0) [0.0|1] ""  Gateway_Max
 SG_ KBI_View6 : 17|1@1+ (1.0,0.0) [0.0|1] ""  Gateway_Max
 SG_ KBI_View7 : 18|1@1+ (1.0,0.0) [0.0|1] ""  Gateway_Max
 SG_ KBI_View8 : 19|1@1+ (1.0,0.0) [0.0|1] ""  Gateway_Max
 SG_ KBI_View9 : 20|1@1+ (1.0,0.0) [0.0|1] ""  Gateway_Max
 SG_ KBI_View10 : 21|1@1+ (1.0,0.0) [0.0|1] ""  Gateway_Max
 SG_ KBI_View11 : 22|1@1+ (1.0,0.0) [0.0|1] ""  Gateway_Max
 SG_ KBI_View12 : 23|1@1+ (1.0,0.0) [0.0|1] ""  Gateway_Max
 SG_ KBI_View13 : 24|1@1+ (1.0,0.0) [0.0|1] ""  Gateway_Max
 SG_ KBI_View14 : 25|1@1+ (1.0,0.0) [0.0|1] ""  Gateway_Max
 SG_ KBI_View15 : 26|1@1+ (1.0,0.0) [0.0|1] ""  Gateway_Max
 SG_ KBI_View16 : 27|1@1+ (1.0,0.0) [0.0|1] ""  Gateway_Max
 SG_ KBI_View17 : 28|1@1+ (1.0,0.0) [0.0|1] ""  Gateway_Max
 SG_ KBI_View18 : 29|1@1+ (1.0,0.0) [0.0|1] ""  Gateway_Max
 SG_ KBI_View19 : 30|1@1+ (1.0,0.0) [0.0|1] ""  Gateway_Max
 SG_ KBI_View20 : 31|1@1+ (1.0,0.0) [0.0|1] ""  Gateway_Max
 SG_ KBI_View21 : 32|1@1+ (1.0,0.0) [0.0|1] ""  Gateway_Max
 SG_ KBI_View22 : 33|1@1+ (1.0,0.0) [0.0|1] ""  Gateway_Max
 SG_ KBI_View23 : 34|1@1+ (1.0,0.0) [0.0|1] ""  Gateway_Max
 SG_ KBI_View24 : 35|1@1+ (1.0,0.0) [0.0|1] ""  Gateway_Max
 SG_ KBI_Curr_View : 36|5@1+ (1.0,0.0) [0.0|31] ""  Gateway_Max
 SG_ KBI_Sec_View_Status : 41|2@1+ (1.0,0.0) [0.0|3] ""  Gateway_Max

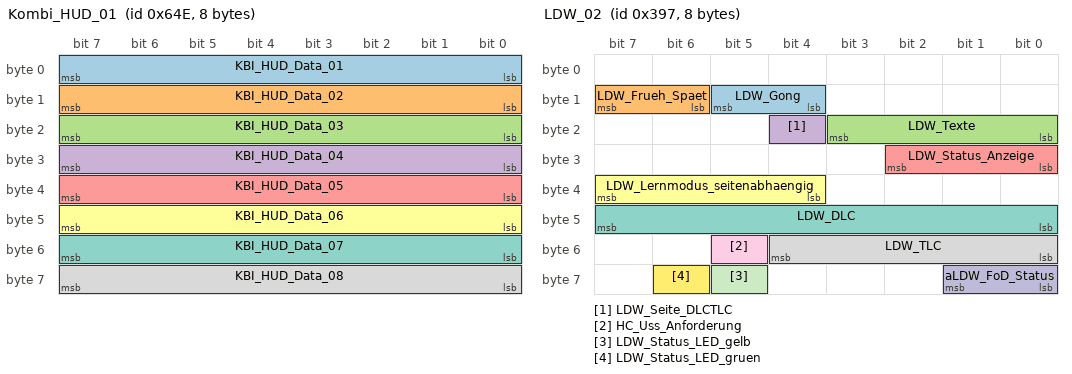
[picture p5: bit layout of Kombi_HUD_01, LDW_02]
BO_ 1614 Kombi_HUD_01: 8 Kombi
 SG_ KBI_HUD_Data_01 : 0|8@1+ (1.0,0.0) [0.0|255] ""  Gateway_Max,HUD
 SG_ KBI_HUD_Data_02 : 8|8@1+ (1.0,0.0) [0.0|255] ""  Gateway_Max,HUD
 SG_ KBI_HUD_Data_03 : 16|8@1+ (1.0,0.0) [0.0|255] ""  Gateway_Max,HUD
 SG_ KBI_HUD_Data_04 : 24|8@1+ (1.0,0.0) [0.0|255] ""  Gateway_Max,HUD
 SG_ KBI_HUD_Data_05 : 32|8@1+ (1.0,0.0) [0.0|255] ""  Gateway_Max,HUD
 SG_ KBI_HUD_Data_06 : 40|8@1+ (1.0,0.0) [0.0|255] ""  Gateway_Max,HUD
 SG_ KBI_HUD_Data_07 : 48|8@1+ (1.0,0.0) [0.0|255] ""  Gateway_Max,HUD
 SG_ KBI_HUD_Data_08 : 56|8@1+ (1.0,0.0) [0.0|255] ""  Gateway_Max,HUD

BO_ 2621440276 KS_Kombi_Req_FD: 16 Gateway_Max
 SG_ KS_Kombi_Req_FD_Data : 0|128@1+ (1.0,0.0) [0.0|340282366920938463463374607431768211455] ""  Kombi

BO_ 2621571348 KS_Kombi_Resp_FD: 16 Kombi
 SG_ KS_Kombi_Resp_FD_Data : 0|128@1+ (1.0,0.0) [0.0|340282366920938463463374607431768211455] ""  Gateway_Max

BO_ 919 LDW_02: 8 Gateway_Max
 SG_ LDW_Gong : 12|2@1+ (1.0,0.0) [0.0|3] ""  Kombi
 SG_ LDW_Frueh_Spaet : 14|2@1+ (1.0,0.0) [0.0|3] ""  Vector__XXX
 SG_ LDW_Texte : 16|4@1+ (1.0,0.0) [0.0|15] ""  HUD,Kombi
 SG_ LDW_Seite_DLCTLC : 20|1@1+ (1.0,0.0) [0.0|1] ""  Vector__XXX
 SG_ LDW_Status_Anzeige : 24|3@1+ (1.0,0.0) [0.0|7] ""  HUD,Kombi
 SG_ LDW_Lernmodus_seitenabhaengig : 36|4@1+ (1.0,0.0) [0.0|15] ""  HUD,Kombi
 SG_ LDW_DLC : 40|8@1+ (0.01,-1.25) [-1.25|1.25] "Unit_Meter"  Vector__XXX
 SG_ LDW_TLC : 48|5@1+ (0.1,0) [0.0|3.0] "Unit_Secon"  Vector__XXX
 SG_ HC_Uss_Anforderung : 53|1@1+ (1.0,0.0) [0.0|1] ""  Vector__XXX
 SG_ aLDW_FoD_Status : 56|2@1+ (1.0,0.0) [0.0|3] ""  HUD,Kombi
 SG_ LDW_Status_LED_gelb : 61|1@1+ (1.0,0.0) [0.0|1] ""  Kombi
 SG_ LDW_Status_LED_gruen : 62|1@1+ (1.0,0.0) [0.0|1] ""  Kombi

BO_ 810 LH_EPS_01: 8 Gateway_Max
 SG_ EPS_01_CRC : 0|8@1+ (1,0) [0|255] ""  Kombi
 SG_ EPS_01_BZ : 8|4@1+ (1,0) [0|15] ""  Kombi
 SG_ EPS_SpannungsAnf : 12|2@1+ (1.0,0.0) [0.0|3] ""  Vector__XXX
 SG_ EPS_Endanschlag : 14|2@1+ (1.0,0.0) [0.0|3] ""  Vector__XXX
 SG_ EPS_Akustiksignal : 16|1@1+ (1.0,0.0) [0.0|1] ""  Vector__XXX
 SG_ EPS_Fehlerlampe : 17|1@1+ (1.0,0.0) [0.0|1] ""  Vector__XXX
 SG_ EPS_Warnungen : 19|3@1+ (1.0,0.0) [0.0|7] ""  Kombi
 SG_ EPS_PLA_Abbruch : 22|4@1+ (1,0) [0|15] ""  Vector__XXX
 SG_ EPS_PLA_Fehler : 26|4@1+ (1,0) [0|15] ""  Vector__XXX
 SG_ EPS_PLA_Status : 30|4@1+ (1.0,0.0) [0.0|15] ""  Vector__XXX
 SG_ EPS_Charisma_FahrPr : 34|4@1+ (1.0,0.0) [0.0|15] ""  Vector__XXX
 SG_ EPS_Charisma_Status : 38|2@1+ (1.0,0.0) [0.0|3] ""  Vector__XXX
 SG_ EPS_VZ_Zst_Offset_Geradeaus : 40|1@1+ (1.0,0.0) [0.0|1] ""  Vector__XXX
 SG_ EPS_Lenkerposition : 41|2@1+ (1.0,0.0) [0.0|3] ""  Vector__XXX
 SG_ EPS_Anf_KL : 43|1@1+ (1.0,0.0) [0.0|1] ""  Vector__XXX
 SG_ EPS_ARA_Status : 44|4@1+ (1.0,0.0) [0.0|15] ""  Vector__XXX
 SG_ EPS_Zst_Offset_Geradeaus : 48|9@1+ (0.00306,0) [0.00000|1.55754] "Unit_MilliMeter"  Vector__XXX

BO_ 981 Licht_Anf_01: 8 Gateway_Max
 SG_ Licht_Anf_01_CRC : 0|8@1+ (1,0) [0|255] ""  Vector__XXX
 SG_ Licht_Anf_01_BZ : 8|4@1+ (1,0) [0|15] ""  Vector__XXX
 SG_ BCM1_Kurvenlicht_links_Anf : 12|1@1+ (1.0,0.0) [0.0|1] ""  Vector__XXX
 SG_ BCM1_Kurvenlicht_rechts_Anf : 13|1@1+ (1.0,0.0) [0.0|1] ""  Vector__XXX
 SG_ BCM1_Standlicht_Anf : 14|1@1+ (1.0,0.0) [0.0|1] ""  Kombi
 SG_ BCM1_Abblendlicht_Anf : 15|1@1+ (1.0,0.0) [0.0|1] ""  Kombi
 SG_ BCM1_Fernlicht_Anf : 16|1@1+ (1.0,0.0) [0.0|1] ""  Vector__XXX
 SG_ BCM1_Nebellicht_Anf : 17|1@1+ (1.0,0.0) [0.0|1] ""  Vector__XXX
 SG_ BCM1_Parklicht_li_Anf : 18|1@1+ (1.0,0.0) [0.0|1] ""  Vector__XXX
 SG_ BCM1_Parklicht_re_Anf : 19|1@1+ (1.0,0.0) [0.0|1] ""  Vector__XXX
 SG_ BCM1_Nebelschluss_Ahg_Anf : 20|1@1+ (1.0,0.0) [0.0|1] ""  Vector__XXX
 SG_ BCM1_Nebelschluss_Fzg_Anf : 21|1@1+ (1.0,0.0) [0.0|1] ""  Kombi
 SG_ BCM1_Schlusslicht_Anf : 22|1@1+ (1.0,0.0) [0.0|1] ""  Kombi
 SG_ BCM_Rueckfahrlicht_Anf : 23|1@1+ (1.0,0.0) [0.0|1] ""  Kombi
 SG_ BCM1_Signaturlicht_Anf : 24|1@1+ (1.0,0.0) [0.0|1] ""  Vector__XXX
 SG_ BCM1_Umfeldleuchten_Anf : 25|1@1+ (1.0,0.0) [0.0|1] ""  Vector__XXX
 SG_ BCM1_Tagfahrlicht_Anf : 26|1@1+ (1.0,0.0) [0.0|1] ""  Kombi
 SG_ BCM1_Regenlicht_Anf : 27|1@1+ (1.0,0.0) [0.0|1] ""  Vector__XXX
 SG_ BCM1_Autobahnlicht_Anf : 28|1@1+ (1.0,0.0) [0.0|1] ""  Vector__XXX
 SG_ BCM1_Touristen_Licht_Anf : 29|1@1+ (1.0,0.0) [0.0|1] ""  Vector__XXX
 SG_ BCM1_CH_aktiv : 30|1@1+ (1.0,0.0) [0.0|1] ""  Vector__XXX
 SG_ BCM1_LH_aktiv : 31|1@1+ (1.0,0.0) [0.0|1] ""  Vector__XXX
 SG_ BCM1_Gleitende_Leuchtw_Anf : 32|1@1+ (1.0,0.0) [0.0|1] ""  Vector__XXX
 SG_ BCM1_GLW_Fernlicht_Anf : 33|1@1+ (1.0,0.0) [0.0|1] ""  Vector__XXX
 SG_ BCM1_Adaptive_Lichtvert_Anf : 34|1@1+ (1.0,0.0) [0.0|1] ""  Vector__XXX
 SG_ BCM1_Animationssperrung : 39|1@1+ (1.0,0.0) [0.0|1] ""  Vector__XXX
 SG_ BCM1_CH_LH_aktiv : 40|1@1+ (1.0,0.0) [0.0|1] ""  Vector__XXX
 SG_ BCM1_Allwetterlicht_Anf : 41|1@1+ (1.0,0.0) [0.0|1] ""  Kombi
 SG_ TFL_Matrix_Variante01_Anf : 42|1@1+ (1.0,0.0) [0.0|1] ""  Vector__XXX
 SG_ TFL_Matrix_Variante02_Anf : 43|1@1+ (1.0,0.0) [0.0|1] ""  Vector__XXX
 SG_ TFL_Matrix_Variante03_Anf : 44|1@1+ (1.0,0.0) [0.0|1] ""  Vector__XXX
 SG_ TFL_Matrix_Variante04_Anf : 45|1@1+ (1.0,0.0) [0.0|1] ""  Vector__XXX

BO_ 982 Licht_hinten_01: 8 Gateway_Max
 SG_ Licht_hinten_01_BZ : 0|4@1+ (1,0) [0|15] ""  Vector__XXX
 SG_ BCM2_Bremsl_durch_ECD_invers : 4|1@1+ (1.0,0.0) [0.0|1] ""  Vector__XXX
 SG_ BCM2_Bremsl_durch_ECD : 5|1@1+ (1.0,0.0) [0.0|1] ""  Vector__XXX
 SG_ LH_Aussenlicht_def : 7|1@1+ (1.0,0.0) [0.0|1] ""  Kombi
 SG_ LH_Standlicht_H_aktiv : 8|1@1+ (1.0,0.0) [0.0|1] ""  Vector__XXX
 SG_ LH_Parklicht_HL_aktiv : 9|1@1+ (1.0,0.0) [0.0|1] ""  Vector__XXX
 SG_ LH_Parklicht_HR_aktiv : 10|1@1+ (1.0,0.0) [0.0|1] ""  Vector__XXX
 SG_ LH_Bremslicht_H_aktiv : 11|1@1+ (1.0,0.0) [0.0|1] ""  Kombi
 SG_ LH_Nebelschluss_aktiv : 12|1@1+ (1.0,0.0) [0.0|1] ""  Vector__XXX
 SG_ LH_Rueckfahrlicht_aktiv : 13|1@1+ (1.0,0.0) [0.0|1] ""  Vector__XXX
 SG_ LH_Blinker_HL_akt : 14|1@1+ (1.0,0.0) [0.0|1] ""  Vector__XXX
 SG_ LH_Blinker_HR_akt : 15|1@1+ (1.0,0.0) [0.0|1] ""  Vector__XXX
 SG_ LH_Blinker_li_def : 16|1@1+ (1.0,0.0) [0.0|1] ""  Kombi
 SG_ LH_Bremsl_li_def : 17|1@1+ (1.0,0.0) [0.0|1] ""  Kombi
 SG_ LH_Schlusslicht_li_def : 18|1@1+ (1.0,0.0) [0.0|1] ""  Kombi
 SG_ LH_Rueckf_li_def : 19|1@1+ (1.0,0.0) [0.0|1] ""  Kombi
 SG_ LH_Nebel_li_def : 20|1@1+ (1.0,0.0) [0.0|1] ""  Kombi
 SG_ LH_Schluss_Brems_Nebel_li_def : 21|1@1+ (1.0,0.0) [0.0|1] ""  Kombi
 SG_ LH_Schluss_Brems_Nebel_re_def : 22|1@1+ (1.0,0.0) [0.0|1] ""  Kombi
 SG_ LH_Zusatzschlussl_def : 23|1@1+ (1.0,0.0) [0.0|1] ""  Kombi
 SG_ LH_Schluss_Brems_li_def : 24|1@1+ (1.0,0.0) [0.0|1] ""  Kombi
 SG_ LH_Schluss_Nebel_li_def : 25|1@1+ (1.0,0.0) [0.0|1] ""  Kombi
 SG_ LH_SL_BRL_BLK_li_def : 26|1@1+ (1.0,0.0) [0.0|1] ""  Kombi
 SG_ LH_Brems_Blk_li_def : 27|1@1+ (1.0,0.0) [0.0|1] ""  Kombi
 SG_ LH_Diag_Status_re_def : 28|1@1+ (1.0,0.0) [0.0|1] ""  Kombi
 SG_ LH_Diag_Status_li_def : 29|1@1+ (1.0,0.0) [0.0|1] ""  Kombi
 SG_ LH_Diag_LED_li_def : 30|1@1+ (1.0,0.0) [0.0|1] ""  Kombi
 SG_ LH_Diag_LED_re_def : 31|1@1+ (1.0,0.0) [0.0|1] ""  Kombi
 SG_ LH_Blinker_re_def : 32|1@1+ (1.0,0.0) [0.0|1] ""  Kombi
 SG_ LH_Bremsl_re_def : 33|1@1+ (1.0,0.0) [0.0|1] ""  Kombi
 SG_ LH_Schlusslicht_re_def : 34|1@1+ (1.0,0.0) [0.0|1] ""  Kombi
 SG_ LH_Rueckf_re_def : 35|1@1+ (1.0,0.0) [0.0|1] ""  Kombi
 SG_ LH_Nebel_re_def : 36|1@1+ (1.0,0.0) [0.0|1] ""  Kombi
 SG_ LH_Schluss_Brems_re_def : 40|1@1+ (1.0,0.0) [0.0|1] ""  Kombi
 SG_ LH_Schluss_Nebel_re_def : 41|1@1+ (1.0,0.0) [0.0|1] ""  Kombi
 SG_ LH_SL_BRL_BLK_re_def : 42|1@1+ (1.0,0.0) [0.0|1] ""  Kombi
 SG_ LH_Brems_Blk_re_def : 43|1@1+ (1.0,0.0) [0.0|1] ""  Kombi
 SG_ LH_Kennzl_def : 48|1@1+ (1.0,0.0) [0.0|1] ""  Kombi
 SG_ LH_3_Bremsl_def : 49|1@1+ (1.0,0.0) [0.0|1] ""  Kombi
 SG_ LH_Nebel_mi_def : 50|1@1+ (1.0,0.0) [0.0|1] ""  Kombi
 SG_ LH_Rueckf_mi_def : 51|1@1+ (1.0,0.0) [0.0|1] ""  Kombi
 SG_ LH_Bremsl_li_ges_def : 54|1@1+ (1.0,0.0) [0.0|1] ""  Kombi
 SG_ LH_Bremsl_re_ges_def : 55|1@1+ (1.0,0.0) [0.0|1] ""  Kombi

CM_ BO_ 960 "MQB";
CM_ BO_ 1646 "ab MQB 7.3";
CM_ BO_ 949 "ab MQB 7.4";
CM_ BO_ 1640 "ab MQB IS-4";
CM_ BO_ 1505 "ab MQB 7.3";
CM_ BO_ 779 "MQB";
CM_ BO_ 919 "ab MQB ohne CHK/BZ, LDW_SW_Warnung_links/rechts, KD-Fehler und mit Zyklus 100ms";
CM_ BO_ 810 "MQB: 50ms (für CAN-SG), geändertes Charisma, Entfall KD-Fehler";
CM_ BO_ 982 "MQB";

CM_ SG_ 1426 KY_Aktive_LFScans "Signalisierung eines aktiven Kessy-Scans (LF auf 125kHz) mit Angabe der Scanart";
CM_ SG_ 1426 KY_AnzKoord_Info "Signalisierung, ob beim Kessy-Scan ein Schlüssel gefunden wurde (1) oder nicht (2)";
CM_ SG_ 1426 KY_EasyClose_Abbruch "ID-Geber während HD-Zufahrt im Nahbereich EasyClose erkannt";
CM_ SG_ 1426 KY_EasyClose_Status "Signal zur LED Ansteuerung im HD-Verriegelungstaster für die Funktion EasyClose.";
CM_ SG_ 1426 KY_Fzg_Verlassen_erkannt "Fahrer/Schlüssel hat das Fahrzeug verlassen und FT wurde geschlossen";
CM_ SG_ 1426 KY_Fzg_Zugang_erkannt "Fahrer/Schlüssel hat Fahrzeug betreten und die FT geschlossen";
CM_ SG_ 1426 KY_Gestik_HD "Aktive Funktion (Gestikgesteuerte Heckklappe) im Kessy-SG";
CM_ SG_ 1426 KY_Gong_600 "Gong zum Meldungstext (1=aktiv)";
CM_ SG_ 1426 KY_HD_Auffahrt "Auffahrt HD nach Wiedereintritt ID-Geber in EasyClose Nahbereich";
CM_ SG_ 1426 KY_HD_Zufahrt "Zufahrt HD nach erfolgreicher Funktion EasyClose";
CM_ SG_ 1426 KY_ID_Geber1_im_Fzg "1 = ID-Geber 1 im Innenraum erkannt";
CM_ SG_ 1426 KY_ID_Geber2_im_Fzg "1 = ID-Geber 2 im Innenraum erkannt";
CM_ SG_ 1426 KY_ID_Geber3_im_Fzg "1 = ID-Geber 3 im Innenraum erkannt";
CM_ SG_ 1426 KY_ID_Geber4_im_Fzg "1 = ID-Geber 4 im Innenraum erkannt";
CM_ SG_ 1426 KY_ID_Geber_Suche "1 = Transponder Scan aktiv";
CM_ SG_ 1426 KY_LF_Aktiv "LF Schluesselkommunikation
";
CM_ SG_ 1426 KY_Meldungen "Kessy-Meldungen:
0 = keine Meldung
1 = Meldung: 'Schlüssel nicht gefunden!' bei Kl.15 ein
2= Meldung: 'Schlüssel im Kofferraum!'
3 = Meldung: 'Schlüssel im Fahrzeug'
4 = Meldung: 'KESSY defekt'
5-15: tbd";
CM_ SG_ 1426 KY_Passiv_Autolock "Aktive Funktion (Passiv Autolock) im Kessy-SG";
CM_ SG_ 1426 KY_Passiv_Autolock_Akt "1 = Funktionszustand im Kessy-SG: 'Passiv Autolock / Autounlock'";
CM_ SG_ 1426 KY_Passiv_Autolock_Menue "1 = Menue-Eintrag 'Passiv Autolock / Autounlock' aktivieren";
CM_ SG_ 1426 KY_Passiv_Autounlock "Aktive Funktion (Passiv Autounlock) im Kessy-SG";
CM_ SG_ 1426 KY_Schluesselposition_1 "Status des ID-Gebers 1 aus der letzten durchgeführten Schlüsselsuche für Remote Parkfunktionen

0 = nicht_gefunden
1 = im_Innenraum_gefunden
2 = im_Außenraum_gefunden_nah, Distanz <= parametrierter Schwelle
3 = im_Außenraum_gefunden_fern, Distanz > p";
CM_ SG_ 1426 KY_Schluesselposition_2 "Status des ID-Gebers 2 aus der letzten durchgeführten Schlüsselsuche für Remote Parkfunktionen

0 = nicht_gefunden
1 = im_Innenraum_gefunden
2 = im_Außenraum_gefunden_nah, Distanz <= parametrierter Schwelle
3 = im_Außenraum_gefunden_fern, Distanz > p";
CM_ SG_ 1426 KY_Schluesselposition_3 "Status des ID-Gebers 3 aus der letzten durchgeführten Schlüsselsuche für Remote Parkfunktionen

0 = nicht_gefunden
1 = im_Innenraum_gefunden
2 = im_Außenraum_gefunden_nah, Distanz <= parametrierter Schwelle
3 = im_Außenraum_gefunden_fern, Distanz > p";
CM_ SG_ 1426 KY_Schluesselposition_4 "Status des ID-Gebers 4 aus der letzten durchgeführten Schlüsselsuche für Remote Parkfunktionen

0 = nicht_gefunden
1 = im_Innenraum_gefunden
2 = im_Außenraum_gefunden_nah, Distanz <= parametrierter Schwelle
3 = im_Außenraum_gefunden_fern, Distanz > p";
CM_ SG_ 1426 KY_Schluesselposition_5 "Status des ID-Gebers 5 aus der letzten durchgeführten Schlüsselsuche für Remote Parkfunktionen

0 = nicht_gefunden
1 = im_Innenraum_gefunden
2 = im_Außenraum_gefunden_nah, Distanz <= parametrierter Schwelle
3 = im_Außenraum_gefunden_fern, Distanz > p";
CM_ SG_ 1426 KY_Schluesselposition_6 "Status des ID-Gebers 6 aus der letzten durchgeführten Schlüsselsuche für Remote Parkfunktionen

0 = nicht_gefunden
1 = im_Innenraum_gefunden
2 = im_Außenraum_gefunden_nah, Distanz <= parametrierter Schwelle
3 = im_Außenraum_gefunden_fern, Distanz > p";
CM_ SG_ 1426 KY_Schluesselposition_7 "Status des ID-Gebers 7 aus der letzten durchgeführten Schlüsselsuche für Remote Parkfunktionen

0 = nicht_gefunden
1 = im_Innenraum_gefunden
2 = im_Außenraum_gefunden_nah, Distanz <= parametrierter Schwelle
3 = im_Außenraum_gefunden_fern, Distanz > p";
CM_ SG_ 1426 KY_Schluesselposition_8 "Status des ID-Gebers 8 aus der letzten durchgeführten Schlüsselsuche für Remote Parkfunktionen

0 = nicht_gefunden
1 = im_Innenraum_gefunden
2 = im_Außenraum_gefunden_nah, Distanz <= parametrierter Schwelle
3 = im_Außenraum_gefunden_fern, Distanz > p";
CM_ SG_ 1426 KY_Schluesselposition_9 "Status des ID-Gebers 9 (MDK) aus der letzten durchgeführten Schlüsselsuche für Remote Parkfunktionen

0 = nicht_gefunden
1 = im_Innenraum_gefunden
2 = im_Außenraum_gefunden_nah, Distanz <= parametrierter Schwelle
3 = im_Außenraum_gefunden_fern, Dista";
CM_ SG_ 1426 KY_Startknopf_Bel "Startknopf beleuchten";
CM_ SG_ 1426 KY_StartStopp_Info "Stopp-Freigabe und Start-Anforderung an den Start-Stopp-Koordinator";

CM_ SG_ 960 BCM_Ausparken_Betrieb "Anforderung zur erneuten Lampenaufprüfung und Anzeige von Warnhinweisen nach einem pilotierten Ausparkvorgang (Trigger: fallende Flanke)";
CM_ SG_ 960 BCM_Remotestart_Betrieb "Zeigt den Status des RemoteStarts an, d.h. KL15_RSt ist aktiviert und der Motorlauf ist im RSt-Betrieb aktiv.";
CM_ SG_ 960 BCM_Remotestart_KL15_Anf "Zeigt den Status der Aktivierung der KL15_RST durch das BCM an.";
CM_ SG_ 960 BCM_Remotestart_MO_Start "Nachdem das BCM die Remotestart MSG Freigabe sicher erkannt hat, fordert das BCM wiederum über dieses Signal vom MSG einen Motorstart durchzuführen.";
CM_ SG_ 960 Klemmen_Status_01_BZ "4bit Botschaftszaehler; wird in jeder Sendebotschaft inkrementiert";
CM_ SG_ 960 Klemmen_Status_01_CRC "Für MLB:
'Berechnung siehe Lastenheft 'Kommunikationsabsicherung für FlexRay und CAN''

Ab MQB und MLBevo:
'Berechnung siehe Lastenheft 'End-to-End Kommunikationsabsicherung''

Endwerte siehe Begleitdokument 'S-PDU Kennungsfolgen'";
CM_ SG_ 960 KST_Fahrerhinweis_1 "Signalisierung Fahrerhinweis 1 der Klemmensteuerung an das Kombi";
CM_ SG_ 960 KST_Fahrerhinweis_2 "Signalisierung Fahrerhinweis 2 der Klemmensteuerung an das Kombi";
CM_ SG_ 960 KST_Fahrerhinweis_4 "Signalisierung Fahrerhinweis 4 der Klemmensteuerung an das Kombi";
CM_ SG_ 960 KST_Fahrerhinweis_5 "Anzeigesignal für RemoteStart";
CM_ SG_ 960 KST_Fahrerhinweis_6 "Signal aktiviert die Kombi-Anzeigeinstrumente (Drehzahl, Tankinhalt, Kühlmitteltemperatur) während aktiviertem RemoteStart-Betrieb";
CM_ SG_ 960 KST_Warn_P1_ZST_def "Kombi Prio Warnung Klemmensteuerung 
Zündschloß defekt, Service aufsuchen!";
CM_ SG_ 960 KST_Warn_P2_ZST_def "Kombi Prio Warnung Klemmensteuerung
Zündschloß defekt!
";
CM_ SG_ 960 RSt_Fahrerhinweise "Über das Signal fordert das BCM Fahrerhinweise im Kombi für die Funktion RemoteStart an.";
CM_ SG_ 960 ZAS_Kl_15 "Klemme 15: Zuendung (SW-Kl.15)
";
CM_ SG_ 960 ZAS_Kl_50_Startanforderung "Klemme 50: Startwunsch Fahrer
";
CM_ SG_ 960 ZAS_Kl_Infotainment "Separate Klemmeninformation für das Infotainment. Signal entspricht im wesentlichen einer Klemme S Information, kann aber über einen Vor - bzw. Nachlauf zu Klemme S verfügen. 
Ein konkreter Anwendungsfall für einen Nachlauf ist die Abschaltung der Klemme";
CM_ SG_ 960 ZAS_Kl_S "Klemme S: S-Kontakt (Schluessel steckt)
";
CM_ SG_ 960 ZAS_Kl_X "Klemme 75
";

CM_ SG_ 2463978753 Klemmen_Status_02_BZ "4bit Botschaftszähler, wird mit jeder Sendebotschaft inkrementiert";
CM_ SG_ 2463978753 Klemmen_Status_02_CRC "Für MLB:
Berechnung siehe Lastenheft 'Kommunikationsabsicherung für FlexRay und CAN'
Ab MQB und MLBevo:
Berechnung siehe Lastenheft 'End-to-End Kommunikationsabsicherung'

Endwerte siehe Begleitdokument 'S-PDU Kennungsfolgen'";
CM_ SG_ 2463978753 KST_ComfortReadyStatus "Zustand des ComfortReadyStatus über den Komfortfunktionen aktiviert werden können.";
CM_ SG_ 2463978753 KST_Freigabe_Zustand "Gibt den Sperr- bzw. Freigabezustand der Klemmensteuerung während SW-Update (z. B. Infotainment) an";
CM_ SG_ 2463978753 KST_Sonderzustand_Anforderung "Hiermit wird die aktive bzw. aktuell angeforderte (s. KST_Sonderzustand_Status) Sonderfunktion identifiziert";
CM_ SG_ 2463978753 KST_Sonderzustand_Status "Hiermit wird signalisiert, dass eine Sonderfunktion aktiv ist und die Klemme 15 durch diese angefordert wurde bzw. ein Übergang von Sonderfunktionen stattfindet";
CM_ SG_ 2463978753 KST_WFS_Fahrfreigabe_Anforderung "Hiermit wird den Wegfahrsperren-Teilnehmern signalisiert welche Art der Fahrfreigabe von der anfordernden Sonderfunktion benötigt wird";

CM_ SG_ 1420 Klemmen_Steuerung_01_BZ "4bit Botschaftszaehler; wird in jeder Sendebotschaft inkrementiert";
CM_ SG_ 1420 Klemmen_Steuerung_01_CRC "Ab MQB und MLBevo:
'Berechnung siehe Lastenheft 'End-to-End Kommunikationsabsicherung''

Endwerte siehe Begleitdokument 'S-PDU Kennungsfolgen'";
CM_ SG_ 1420 KST_Anf_Klemme_15 "Anforderung der Klemme 15 an das BCM. Signal wird zur Plausibilisierung parallel zum Klemmensignal auf dem CAN übertragen.";
CM_ SG_ 1420 KST_Anf_Klemme_50 "Anforderung der Klemme 50 an das MSG. Signal wird zur Plausibilisierung parallel zum Klemmensignal auf dem CAN übertragen.";
CM_ SG_ 1420 KST_Anf_Klemme_S "Anforderung der Klemme S an das BCM. Signal wird zur Plausibilisierung parallel zum Klemmensignal auf dem CAN übertragen.";
CM_ SG_ 1420 KST_Anf_Klemmenfreigabe_ELV "Klemmensteuerung fordert Klemmen-Freigabe durch die ELV an.";
CM_ SG_ 1420 KST_Anf_Klemmenfreigabe_WFS "Anforderung der Freigabe von der WFS zum Einschalten von Klemme 15 und Klemme S";
CM_ SG_ 1420 KST_Anf_ZV_Verriegelung "Neuer Verriegelungstrigger für die ZV nach der automatischen Klemmenabschaltung.

Wird bei Kessyfahrzeugen mit StartStop ein aktiver Stop-Mode und Fahrerverlassen erkannt, startet ein 30 Sekunden-Timer. Innerhalb dieser 30 Sekunden hat der Fahrer die Mö";
CM_ SG_ 1420 KST_Anzeige_Klemmenzustand "Klemmensteuerung zeigt (Fehler-)zustände nach/während Update Infotainment bzgl. Klemme 50 an";
CM_ SG_ 1420 KST_aut_Abschaltung_Zuendung "Falls bei eingeschalteter Zündung das Abblendlicht aktiv war, muss nach der automatischen Abschaltung der Kl_15 & Kl_S, dass Standlicht aktiv bleiben. Das Signal sendet die Information, dass eine automatische Abschaltung der Kl_15 und Kl_S erfogt.";
CM_ SG_ 1420 KST_Txt_Komfortabschaltung "Dieses Signal fordert im Kombi die Meldung an, die den Fahrer über die ausgeführte automatische Zündungsabschaltung informiert. Signal wird für10s gesendet.";
CM_ SG_ 1420 KST_Txt_P_Gang "Text: 'Wählhebel in Position P bringen!'";
CM_ SG_ 1420 KST_Txt_Panikabschaltung "Text: 'Notabschaltung''";
CM_ SG_ 1420 KST_Txt_Werkstatt "Text: 'Klemmensteuerung! Werkstatt!'";
CM_ SG_ 1420 KST_Unterdr_Zuendungsmeldung "Bei aktivem Signal soll die Zündungsmeldung durch das Kombi unterdrückt werden.";
CM_ SG_ 1420 KST_ZAT_betaetigt "Zündanlass-Taster (ZAT) betätigt";
CM_ SG_ 1420 KST_Zuendungswarnung "Bei aktivem Signal soll je nach gesetztem Status eine Warnung durch das Kombi ausgegeben werden";
CM_ SG_ 1420 Relais_VoKo_angesteuert "Signal zur Rückmeldung, ob das Relais für die Verbraucher von erweiterte Voko / RemoteStart angesteuert wird.";
CM_ SG_ 1420 RSt_Anforderung_HMS "Anforderung vom RSt (Remote Start) an das HMS (Haltemanagement System)";

CM_ SG_ 1646 KL_Anf_AussenspiegelHzg "Anforderung Außenspiegelheizung seitens Klimafunktion (z.B. bei Erweiterter VoKo)";
CM_ SG_ 1646 KL_BCmE_Livetip_Freigabe "Status der Klimaanlage. 
Zeigt an, ob der Livetip 'Fenster schließen wegen Ineffizienz Klimaanlage' sinvollerweise angezeigt werden soll";
CM_ SG_ 1646 KL_ErwVK_Anf "Erweiterte Voko angefordertert / aktiv";
CM_ SG_ 1646 KL_FSH_Automatikbetrieb "Ermöglicht eine Unterscheidung von Anforderung FSH durch Kundenwunsch und Anforderung FSH durch Regelung des Klimasteuergeräts.
Das Signal liegt als Pegel an.";
CM_ SG_ 1646 KL_Geblaese_Fond_Status "Status Geblaese









";
CM_ SG_ 1646 KL_Geblaese_Status "Status Geblaese









";
CM_ SG_ 1646 KL_Heizkreisventilstellung "Bei MQB PHEV: Stellung Heizkreisventil Motor";
CM_ SG_ 1646 KL_I_Geblaese_Fond "Stromaufnahme Gebläse Heck";
CM_ SG_ 1646 KL_Innen_Temp "Innentemperatur

";
CM_ SG_ 1646 KL_Kompressorkupplung "Signal zur Aktivierung/Deaktivierung der Kompressorkupplung";
CM_ SG_ 1646 KL_Magnetventil "Anforderung des Bypassventils.";
CM_ SG_ 1646 KL_Restwaerme_aktiv "Signal zur Aktivierung/Deaktivierung der Wasserpumpe bei Restwärme; 
reduzierte IRÜ Empfindlichkeit";
CM_ SG_ 1646 KL_SH_Soll_hl "Einstellung Sitzheizung hinten links (0...6)";
CM_ SG_ 1646 KL_SH_Soll_hr "Einstellung Sitzheizung hinten rechts (0...6)";
CM_ SG_ 1646 KL_SIH_LEH_Verteilung_VL "Vom Kunden eingestellte Aufteilung der Heizleistung auf Sitzfläche und Lehnefläche für Sitz vorne links";
CM_ SG_ 1646 KL_SIH_LEH_Verteilung_VR "Vom Kunden eingestellte Aufteilung der Heizleistung auf Sitzfläche und Lehnefläche für Sitz vorne rechts";
CM_ SG_ 1646 KL_SIH_LEL_Verteilung_VL "Vom Kunden eingestellte Aufteilung der Lüftungsleistung auf Sitzfläche und Lehnenfläche für Sitz vorne links";
CM_ SG_ 1646 KL_SIH_LEL_Verteilung_VR "Vom Kunden eingestellte Aufteilung der Lüftungsleistung auf Sitzfläche und Lehnenfläche für Sitz vorne rechts";
CM_ SG_ 1646 KL_Solarluefter_aktiv "Betriebsstatus Solarluefter
";
CM_ SG_ 1646 KL_STH_aktiv "Betriebsstatus Standheizung
";
CM_ SG_ 1646 KL_STH_Ansteuerung "Ansteuerung STH

";
CM_ SG_ 1646 KL_STH_Betriebsdauer "Betriebsdauer STH";
CM_ SG_ 1646 KL_STL_aktiv "Betriebsstatus Standlueftung
";
CM_ SG_ 1646 KL_Umluft_Taste "Betaetigung Umlufttaste
";
CM_ SG_ 1646 KL_WaPu "Ansteuerung der Standheizungswasserpumpe";

CM_ SG_ 949 KL_AC_Schalter "AC Schalter
";
CM_ SG_ 949 KL_AirCleaner_aktiv "Status des Zustands der AirCare Funktion (Umluft) im Fahrzeug";
CM_ SG_ 949 KL_Anf_KL "Anforderung Kühlerlüfter der Klimaanlage in Prozent

";
CM_ SG_ 949 KL_Anf_KV "Anforderung des Kühlerrollos in %";
CM_ SG_ 949 KL_Ausstattung_Klima "Austtattungsart der Klimabedienung";
CM_ SG_ 949 KL_Charisma_FahrPr "MLBevo: Aktuelles Fahrprogramm des Charisma-Teilnehmers (siehe Systemlastenheft Drive Select)
MQB: Istwert der Kennlinie (siehe Systemlastenheft MQB FPA)";
CM_ SG_ 949 KL_Charisma_Status "Charisma Systemstatus des Charisma-Teilnehmers

Wert 0x3 ist nur für Fahrzeuge ab MQB relevant";
CM_ SG_ 949 KL_Drehz_Anh "Drehzahlanhebung vom Motor angefordert

";
CM_ SG_ 949 KL_el_Zuheizer_Stufe "Vorgabe für Motorsteuergeraet PTC-Stufe; im MLB-B8 und MQB nur Stufe 0...3

";
CM_ SG_ 949 KL_Freilauf_Info "Freilauf Informationssignal von Klima zum Freilaufkoordinator. Klima kann über dieses Signal den Freilauf freigeben, verhindern bzw. explizit anfordern.";
CM_ SG_ 949 KL_Kompressorkupplung_linear "Sollwert zur Ansteuerung der Kompressorkupplung";
CM_ SG_ 949 KL_Last_Kompr "Aktuelles Verlustmoment der Klimaanlage bezogen auf die Kurbelwelle. Wird der Klimakompressor nicht angesteuert, ist das Schleppmoment bezogen auf die Kurbelwelle zu senden.";
CM_ SG_ 949 KL_nachtr_Stopp_Anf "Dieses Signal dient dem Motor als Trigger, dass ein nachträglicher Motorstopp eingeleitet werden kann, wenn es die Bedingungen des StSt Koordinators dies zulassen. ";
CM_ SG_ 949 KL_Spannungs_Anf "Forderung des Klima-SG's zur Spannungsanhebung.";
CM_ SG_ 949 KL_StartStopp_Info "Stopp-Freigabe und Start-Anforderung an den Start-Stopp-Koordinator";
CM_ SG_ 949 KL_T_Charge "Signal für Tastenbetätigung Charge-Taste (SOC Increasing)";
CM_ SG_ 949 KL_Thermomanagement "Stufen des Thermomanagements;
Bei Klemme 15 AUS und erkannten Timeout zum Klimabedienteil (z.B. Klimabedienteil während des Motorsteuergeräte-Kommunikations-Nachlaufs bereits im NM-Zustand ¿Bus Sleep¿)
erfolgt keine Ansteuerung der Wasserpumpe durch die";
CM_ SG_ 949 KL_Variante_Standheizung "Identifikation der Variante der Standheizungen zur Berechnung der energetischen Zielzeit";
CM_ SG_ 949 KL_Vorwarn_Komp_ein "Vorwarnung Kompressor ein; 140ms vorher; Information für Motor zum Aufbau Momentenreserve";
CM_ SG_ 949 KL_Vorwarn_Zuheizer_ein "Vorwarnung Zuheizerbetrieb
";
CM_ SG_ 949 KL_Zustand "Beschreibt den Zustand des Klima-/Heizungsbedienteils. (OFF-Mode Bedienteil)

PAG (MLB): Beschreibt den Zustand des Kompressors";

CM_ SG_ 1640 FSH_Taster "Tasterbetätigung Frontscheibenheizung
";
CM_ SG_ 1640 HSH_Taster "An-/Abforderung Heckscheibenheizung über spezielles Tastersignal
";
CM_ SG_ 1640 KL_Beschlagsgefahr "Beschlagsgefahr auf der Frontscheibe im Bereich des Spiegelfusses. Dient zur präventiven Ansteuerung der  Kamera-Scheibenheizung, um Kamera-Blindheit zu vermeiden
PHEV: volle Leistungsfreigabe 
HV Heizer und HV EKK bei Scheibenbeschlag ";
CM_ SG_ 1640 KL_Geblspng_Fond_Soll "Ausgabe des Sollwertes für die Spannung des Klimagebläsemotores hinten.






";
CM_ SG_ 1640 KL_Geblspng_Soll "Ausgabe des Sollwertes für die Spannung des Klimagebläsemotores vorne.







";
CM_ SG_ 1640 KL_I_Geblaese "Stromaufnahme Gebläse";
CM_ SG_ 1640 KL_Kompressorstrom_soll "Sollvorgabe Klima-Kompressorstrom";
CM_ SG_ 1640 KL_LRH_Stufe "Eingestellte Temperaturstufe der Lenkradheizung";
CM_ SG_ 1640 KL_LRH_Taster "Tasterbetätigung Lenkradheizung";
CM_ SG_ 1640 KL_PTC_Verbauinfo "Im Klima- bzw. Heizungsbedienteil wird der Verbau eines PTCs und dessen elektr. Leistungsklasse codiert";
CM_ SG_ 1640 KL_SIH_Soll_li "Einstellung Sitzheizung Fahrer (0...6)";
CM_ SG_ 1640 KL_SIH_Soll_re "Einstellung Sitzheizung Beifahrer (0...6)";
CM_ SG_ 1640 KL_SIL_Soll_li "Einstellung Sitzlüftung Fahrer (0...6)";
CM_ SG_ 1640 KL_SIL_Soll_re "Einstellung Sitzlüftung Beifahrer (0...6)";
CM_ SG_ 1640 KL_Umluftklappe_Status "Status Umluftklappe";
CM_ SG_ 1640 KL_Zuheizer_Freigabe "Freigabe Zuheizer
";
CM_ SG_ 1640 KRH_Soll_li "Ausgabe des Sollwertes für die Kopfraumheizung links.";
CM_ SG_ 1640 KRH_Soll_re "Ausgabe des Sollwertes für die Kopfraumheizung rechts.";

CM_ SG_ 2527679635 FSH_Status "Fehlerstatus der Frontscheibenheizung
";
CM_ SG_ 2527679635 HSH_Relais_Anf "Relaisanforderung Heckscheibenheizung";
CM_ SG_ 2527679635 KL_AL_HL_Anf "Anforderung an das funktionale Ambientelicht eine Solltemperaturveränderung hinten links darzustellen.";
CM_ SG_ 2527679635 KL_AL_HR_Anf "Anforderung an das funktionale Ambientelicht eine Solltemperaturveränderung hinten rechts darzustellen.";
CM_ SG_ 2527679635 KL_AL_VL_Anf "Anforderung an das funktionale Ambientelicht eine Solltemperaturveränderung vorn links darzustellen.";
CM_ SG_ 2527679635 KL_AL_VR_Anf "Anforderung an das funktionale Ambientelicht eine Solltemperaturveränderung vorn rechts darzustellen.";
CM_ SG_ 2527679635 KL_Defrost_LED "Beleuchtung LED Defrost";
CM_ SG_ 2527679635 KL_FSH_LED "Beleuchtung LED Frontscheibenheizung";
CM_ SG_ 2527679635 KL_FSH_Soll "Sollstatus der Frontscheibenheizung";
CM_ SG_ 2527679635 KL_Heizstufe_LSH "Vom Klimabedienteil gesendete Heizstufe der Luftstandheizung";
CM_ SG_ 2527679635 KL_HSH_LED "Beleuchtung LED Heckscheibenheizung";
CM_ SG_ 2527679635 KL_HSH_Soll "Sollstatus Heckscheibenheizung";
CM_ SG_ 2527679635 KL_HUP_aktiv "Signal des Klimabedienteils ob HUP aktiv ist.

0 = HUP aus
1 = HUP ein";
CM_ SG_ 2527679635 KL_Klappe_Status "Status Luftklappe";
CM_ SG_ 2527679635 KL_LRH_PWM "LRH PWM Signal zur Ansteuerung der Treiberstufe im SMLS (0% - 100%)";
CM_ SG_ 2527679635 KL_LRH_Soll "Sollstatus der Lenkradheizung";
CM_ SG_ 2527679635 KL_LSH_Ansteuerung "Ansteuerung LSH";
CM_ SG_ 2527679635 KL_LSH_Betriebsdauer "Betriebsdauer LSH";
CM_ SG_ 2527679635 KL_LSH_DBetr_Bestaet "Bestätigung des Klimabedienteils an die LSH das Dauerbetrieb tatsächlich angefordert ist.";
CM_ SG_ 2527679635 KL_LSH_DBetr_Ein "Dauerbetrieb der Luftstandheizung Ein";
CM_ SG_ 2527679635 KL_Temp_ZH_Soll "Übertragung der Temperaturvorgabe der Klimaanlage an die Wasserzusatzheizung";
CM_ SG_ 2527679635 KL_VoKo_LED "Signalisierung Vorkonditionierung";
CM_ SG_ 2527679635 KL_Voko_Status "Status der Vorkonditionierung.

0 = aus
1 = ein

14 = Init
15 = Fehler";
CM_ SG_ 2527679635 KL_ZR_Anforderung "Anforderung an MIB die Displays zu aktivieren";
CM_ SG_ 2527679635 SIH_Stufe_LED_li "Statusmeldung Sitzheizung links";
CM_ SG_ 2527679635 SIH_Stufe_LED_re "Statusmeldung Sitzheizung rechts";

CM_ SG_ 1505 BCM1_Aussen_Temp_ungef "ungefilterter Wert des Aussentemperatursensors
";
CM_ SG_ 1505 BCM1_FStatus_Aussentemp_ungef "Fehlerstatus für Aussentemperatur (Kombianzeige)";
CM_ SG_ 1505 BCM1_Kompressorstrom_ist "IST-Strom vom Klima-Kompressor";
CM_ SG_ 1505 BCM1_OBD_FStatus_ATemp "Fehlerstatus Umgebungstemperatursensor (OBD relevanter Sensor)
";
CM_ SG_ 1505 BCM1_PTC_stufig_Status "Status des BCM1-Heizverbrauchers PTC (stufig)";
CM_ SG_ 1505 BCM_Heizungsabsperrventil_Status "Das Signal beschreibt den Zustand des Heizungsabsperrventils, welches als Portexpander vom BCM1 elektrisch angesteuert wird.";
CM_ SG_ 1505 BCM_Heizungspumpe_Status "Das Signal beschreibt den Zustand der Heizungspumpe, welche als Portexpander vom BCM1 elektrisch angesteuert wird.";
CM_ SG_ 1505 BCM_Kompressorkupplung_Status "Das Signal beschreibt den Zustand der Klimakompressorkupplung, welche als Portexpander vom BCM1 elektrisch angesteuert wird.";

CM_ SG_ 2549088305 ELV_Abschaltstufe "Funktionseinschränkung aufgrund aktiver Abschaltstufe";
CM_ SG_ 2549088305 ELV_KD_Fehler "Bei gesetztem Bit ist mindestens ein Kundendienstfehler eingetragen";
CM_ SG_ 2549088305 ELV_KompSchutz "Funktionseinschränkung aufgrund Komponentenschutz aktiv";
CM_ SG_ 2549088305 ELV_Nachlauftyp "Abgebildet wird die von der Hardware vorgegebene Möglichkeit, die Kommunikation nach Klemme 15 = AUS aufrecht zu erhalten. Es wird ein Init-Wert gesendet.";
CM_ SG_ 2549088305 ELV_Transport_Mode "Funktionseinschränkung aufgrund aktivem Transport Mode und/oder Transport Schutz";
CM_ SG_ 2549088305 KN_ELV_BusKnockOut "Ausgabe des BusKnockout-Status";
CM_ SG_ 2549088305 KN_ELV_BusKnockOutTimer "Ausgabe des BusKnockOut-Timer";
CM_ SG_ 2549088305 KN_ELV_DiagPfad "Kennzeichnung der Diagnosefähigkeit des BusInterfaces eines Steuergerätes (Knoten)
Umfang LAH 80127

Bei Nutzung des Signal explizit pro angebundenem BusInterface zu setzen:

MLBevo auf FlexRay A-Kanal = 0 (aktiv)
MQB auf K-CAN = 0 (aktiv)
MQBw_Bas";
CM_ SG_ 2549088305 KN_ELV_ECUKnockOut "Ausgabe des ECUKnockout-Status";
CM_ SG_ 2549088305 KN_ELV_ECUKnockOutTimer "Ausgabe des ECUKnockOut-Timer";
CM_ SG_ 2549088305 NM_ELV_Lokalaktiv "Zeigt an ob das SG nach Klemme15 AUS und nach entsprechender MAX Aktivzeit noch aktiv war.";
CM_ SG_ 2549088305 NM_ELV_Subsystemaktiv "Zeigt an ob ein Subsystem des SGs nach Klemme15 AUS und nach entsprechender MAX Aktivzeit noch aktiv war";
CM_ SG_ 2549088305 NM_ELV_Wakeup "enthält die Weckursache; stehen mehrere Weckursachen parallel an, dann muss der kleinste Wert übertragen werden";

CM_ SG_ 2549088272 Gateway_Abschaltstufe "Funktionseinschränkung aufgrund aktiver Abschaltstufe";
CM_ SG_ 2549088272 Gateway_KompSchutz "Funktionseinschränkung aufgrund Komponentenschutz aktiv";
CM_ SG_ 2549088272 Gateway_Nachlauftyp "Abgebildet wird die von der Hardware vorgegebene Möglichkeit, die Kommunikation nach Klemme 15 = AUS aufrecht zu erhalten. Es wird ein Init-Wert gesendet.";
CM_ SG_ 2549088272 Gateway_Transport_Mode "Funktionseinschränkung aufgrund aktivem Transport Mode und/oder Transport Schutz";
CM_ SG_ 2549088272 GW_KD_Fehler "Kundendienstfehlerbit Gateway zur Anzeige eines im Gateway abgelegten Fehlerspeichereintrages.";
CM_ SG_ 2549088272 KN_GW_DiagPfad "Kennzeichnung der Diagnosefähigkeit des BusInterfaces eines Steuergerätes (Knoten)
Umfang LAH 80127

Bei Nutzung des Signal explizit pro angebundenem BusInterface zu setzen:
MQB auf Diag-CAN = 0 (aktiv)
MLBevo auf Diag-CAN = 0 (aktiv)
alle weiteren ";
CM_ SG_ 2549088272 NM_Gateway_Wakeup "enthält die Weckursache; stehen mehrere Weckursachen parallel an, dann muss der kleinste Wert übertragen werden";

CM_ SG_ 2549088283 HUD_Abschaltstufe "Funktionseinschränkung aufgrund aktiver Abschaltstufe";
CM_ SG_ 2549088283 HUD_KD_Fehler "Bei gesetztem Bit ist mindestens ein Kundendienstfehler eingetragen";
CM_ SG_ 2549088283 HUD_KompSchutz "Funktionseinschränkung aufgrund Komponentenschutz aktiv";
CM_ SG_ 2549088283 HUD_Nachlauftyp "Abgebildet wird die von der Hardware vorgegebene Möglichkeit, die Kommunikation nach Klemme 15 = AUS aufrecht zu erhalten. Es wird ein Init-Wert gesendet.";
CM_ SG_ 2549088283 HUD_Transport_Mode "Funktionseinschränkung aufgrund aktivem Transport Mode und/oder Transport Schutz
";
CM_ SG_ 2549088283 KN_HUD_BusKnockOut "Ausgabe des BusKnockout-Status";
CM_ SG_ 2549088283 KN_HUD_BusKnockOutTimer "Ausgabe des BusKnockOut-Timer";
CM_ SG_ 2549088283 KN_HUD_DiagPfad "Kennzeichnung der Diagnosefähigkeit des BusInterfaces eines Steuergerätes (Knoten)
Umfang LAH 80127

Bei Nutzung des Signal explizit pro angebundenem BusInterface zu setzen:
MQB auf K-CAN = 0 (aktiv)
MQB2020 auf K-CAN = 0 (aktiv)
MQB2020 auf VLAN-Ko";
CM_ SG_ 2549088283 KN_HUD_ECUKnockOut "Ausgabe des ECUKnockout-Status";
CM_ SG_ 2549088283 KN_HUD_ECUKnockOutTimer "Ausgabe des ECUKnockOut-Timer";
CM_ SG_ 2549088283 NM_HUD_Lokalaktiv "Zeigt an ob das SG nach Klemme15 AUS und nach entsprechender MAX Aktivzeit noch aktiv war.";
CM_ SG_ 2549088283 NM_HUD_Subsystemaktiv "Zeigt an ob ein Subsystem des SGs nach Klemme15 AUS und nach entsprechender MAX Aktivzeit noch aktiv war";
CM_ SG_ 2549088283 NM_HUD_Wakeup "enthält die Weckursache; stehen mehrere Weckursachen parallel an, dann muss der kleinste Wert übertragen werden";

CM_ SG_ 2549088276 KN_KBI_DiagPfad "Kennzeichnung der Diagnosefähigkeit des BusInterfaces eines Steuergerätes (Knoten)
Umfang LAH 80127

Bei Nutzung des Signal explizit pro angebundenem BusInterface zu setzen:
MLBevoGen1 auf I-CAN = 0 (aktiv)
MLBevoGen2 auf D-CAN = 0 (aktiv)
MQB auf K";
CM_ SG_ 2549088276 KN_Kombi_BusKnockOut "Ausgabe des BusKnockout-Status in der Knotenbotschaft";
CM_ SG_ 2549088276 KN_Kombi_BusKnockOutTimer "Ausgabe des BusKnockOut-Timer in der Knotenbotschaft";
CM_ SG_ 2549088276 KN_Kombi_ECUKnockOut "Ausgabe des ECUKnockout-Status in der Knotenbotschaft";
CM_ SG_ 2549088276 KN_Kombi_ECUKnockOutTimer "Ausgabe des ECUKnockOut-Timer in der Knotenbotschaft";
CM_ SG_ 2549088276 Kombi_Abschaltstufe "Funktionseinschränkung aufgrund aktiver Abschaltstufe";
CM_ SG_ 2549088276 Kombi_KompSchutz "Funktionseinschränkung aufgrund Komponentenschutz aktiv";
CM_ SG_ 2549088276 Kombi_Nachlauftyp "Abgebildet wird die von der Hardware vorgegebene Möglichkeit, die Kommunikation nach Klemme 15 = AUS aufrecht zu erhalten. Es wird ein Init-Wert gesendet.";
CM_ SG_ 2549088276 Kombi_Transport_Mode "Funktionseinschränkung aufgrund aktivem Transport Mode und/oder Transport Schutz";
CM_ SG_ 2549088276 NM_Kombi_Lokalaktiv "Zeigt an ob das SG nach Klemme15 AUS und nach entsprechender MAX Aktivzeit noch aktiv war";
CM_ SG_ 2549088276 NM_Kombi_Subsystemaktiv "Zeigt an ob ein Subsystem des SGs nach Klemme15 AUS und nach entsprechender MAX Aktivzeit noch aktiv war";
CM_ SG_ 2549088276 NM_Kombi_Wakeup "enthält die Weckursache; stehen mehrere Weckursachen parallel an, dann muss der kleinste Wert übertragen werden";

CM_ SG_ 779 KBI_ABS_Lampe "ABS-Sicherheits-Lampe wurde eingeschaltet.";
CM_ SG_ 779 KBI_Airbag_Lampe "Airbag Sicherheits-Lampe wurde eingeschaltet ";
CM_ SG_ 779 KBI_angez_Geschw "Im Tacho angezeigte Geschwindigkeit inklusive der Voreilung

";
CM_ SG_ 779 KBI_Anzeigefehler_NV "Über dieses Signal teilt das Kombiinstrument dem Nightvision-Steuergerät mit, dass ein Fehler vom Kombiinstrument diagnostiziert wurde, der zur Abschaltung der Nightvision-Funktion führen muss.";
CM_ SG_ 779 KBI_Anzeigefehler_SWA "Signal bezieht sich nur auf die SWA-Lampe, Vorhalt für Kombis mit SWA-Lampe. ";
CM_ SG_ 779 KBI_Anzeigestatus_ACC "Status der ACC-Anzeige im nicht permanenten Displaybereich";
CM_ SG_ 779 KBI_Anzeigestatus_GRA "Anzeigestatus der GRA High Wunschgeschwindigkeitsanzeige im Kombiinstrument.
Bei VW bedeutet 'nicht vorhanden' GRA-low fähig (LED immer verbaut).
0 = nicht vorhanden
1 = Wunschgeschwindigkeits-Anzeigemöglichkeit vorhanden
2 = reserviert
3 = Fehler (B";
CM_ SG_ 779 KBI_Anzeigestatus_LIM "Anzeigestatus der Speedlimiter Wunschgeschwindigkeitsanzeige im Kombiinstrument (permanenter Anzeigebereich)
0 = nicht vorhanden
1 = Wunschgeschwindigkeits-Anzeigemöglichkeit vorhanden
2 = reserviert
3 = Fehler (Botschaftsüberwachung, Timeout, Akustik";
CM_ SG_ 779 KBI_Anzeigestatus_RHP "Anzeigestatus des roten RHP-Symbols.";
CM_ SG_ 779 KBI_ARA_in_Anzeige "Anzeige von ARA im Kombi aktiv";
CM_ SG_ 779 KBI_Audioabsenkung_MIB "Anforderung der Audioabsenkung im MIB";
CM_ SG_ 779 KBI_Bestaetigung_ESP_Off "ESP Off Bestätigung vom Kombi ans ESC";
CM_ SG_ 779 KBI_BKL_Lampe "Sicherheits-Lampe Bremskontrolle wurde eingeschaltet;
";
CM_ SG_ 779 KBI_ESP_Lampe "ESP-Sicherheits-Lampe wurde eingeschaltet ";
CM_ SG_ 779 KBI_Fehler_Anzeige_ACC "Rückmeldung an ACC, dass mindestens eine der ACC-relevanten Anzeigen -rote Fahrerübernahme, Mitteldisplay, Gong - fehlerhaft sind.";
CM_ SG_ 779 KBI_Handbremse "Handbremsen-Information vom Kombi.
Das Signal bezieht sich ausschließlich auf den Zustand der konventionellen Handbremse.";
CM_ SG_ 779 KBI_im_Stellgliedtest "Kombi im Stellgliedtest, Signal muss eingelesen werden, um Fehlfunktion aufgrund der Bewegung der Stellglieder (Drehzahlmesser, Tacho) des Kombis zu verhindern";
CM_ SG_ 779 KBI_Konsistenz_ACC "Rückmeldung an ACC, dass die Botschaften zur Ansteuerung von Anzeigen nicht bzw. nicht konsistent empfangen wurden (Timeout-, BZ-, CHK- und DLC-Fehler)                                                                                                        ";
CM_ SG_ 779 KBI_Lenkung_Lampe "Sicherheits-Lampe der Lenkung (Lenkhilfe EPS, Audi-Dynamic-Steering ...) wurde eingeschaltet.

0x0 = Lenkungs-Lampe aus
0x1 = Lenkungs-Lampe ein";
CM_ SG_ 779 KBI_MFA_v_Einheit_01 "Einheit der Geschwindigkeit, die vom Fahrer im Car-Menü gewählt wurde. Veränderliche Grösse, im Gegensatz zur Einheit des Tachokranzes.";
CM_ SG_ 779 KBI_NV_in_Anzeige "Das Bit gibt dem NV die Information, ob NV-Bild im Kombi in der Anzeige ist. (Information ist notwendig um Kontrasverstellungen nur dann zuzulassen, wenn der Fahrer das Feedback über das  Kombidisplay bekommt.)";
CM_ SG_ 779 KBI_Oeldruck_Schalter "Das Signal bildet den Status des Öldrucks über den am Kombi angeschlossenen Öldruckschalter ab.";
CM_ SG_ 779 KBI_Oeldruckwarnung "Öldruckwarnung im Kombi aktiv";
CM_ SG_ 779 KBI_PLA_in_Anzeige "Das Signal wird als aktive Rückmeldung genutzt, ob die Info des PLA im Kombi angezeigt wird. Wenn nach Anforderung des Displays das Signal zweimal auf 0 ist, wird der Parkvorgang abgebrochen.
Ein Kombi, dass PLA Anzeige nicht unterstützt, schickt dauerha";
CM_ SG_ 779 KBI_SILA_gueltig "Rückmeldeinformation (Bit 1-6) ist gültig";
CM_ SG_ 779 KBI_Systemstatus "Signalisiert erkannte FuSi-relevante Fehler im Kombi
(keinen Ausfall der Akustik oder des Displays)";
CM_ SG_ 779 KBI_Tankwarnung "Fahrer wird gewarnt, dass er den Reservebereich erreicht hat. Fzg.spezifische Warnschwelle";
CM_ SG_ 779 KBI_Tankwarnung_ungueltig "Validiert den Inhalt des Signales KBI_Tankwarnung";
CM_ SG_ 779 KBI_Taster_Fahrwerk "Betätigung Taster 'Fahrwerk' im Kombi";
CM_ SG_ 779 KBI_Taster_Lift "Betätigung Taster 'Lift' im Kombi J1 zur Verarbeitung im Porsche EFP Steuergerät";
CM_ SG_ 779 KBI_V_Digital "Ausgabe der im Kombi angezeigten digitalen Geschwindigkeit.

Einheit ist im KBI_MFA_v_Einheit_01 definiert";
CM_ SG_ 779 KBI_Vorglueh_System_Lampe "Rückmeldung der Vorglühlampe bzw. Motor Systemlampe (MO_Systemlampe) an den Motor (bei Diesel und Otto!). Hardwaremässig gleiche LED im Kombi (EPC- oder Glühwendel), Unterscheidung nur über Ziffernblatt.";

CM_ SG_ 1719 KBI_aktive_Laengsfunktion_02 "Auswahl, der vom Fahrer gewünschten Laengsregelfunktion";
CM_ SG_ 1719 KBI_FoD_PopUP_Quittiert "Angezeigte FoD-Warnung im Kombi wurde vom Fahrer quittiert; 
Signal wird für die Dauer von 2 Sekunden gesendet";
CM_ SG_ 1719 KBI_FStatus_Tank "Signal wird gesetzt:

a) Während der Fehlerentprellzeit (20 s Entprellung)

b) Bei erkanntem Fehler wird der Tankinhalt während der laufenden KL15-Phase über den 
    Verbrauch zurückgerechnet. In dieser Zeit ist das Bit ebenfalls gesetzt. Nach einem";
CM_ SG_ 1719 KBI_GRA_im_ACC "Gibt den vom Fahrer ausgewählten Modus (ACC oder GRA_im_ACC) an.";
CM_ SG_ 1719 KBI_Inhalt_Tank "Restmenge 2 bzw. 2,5l nicht auflösbar

";
CM_ SG_ 1719 KBI_Kilometerstand "Fehler wird ausgegeben, falls Kilometerstand nicht restaurierbar
";
CM_ SG_ 1719 KBI_Oelwechsel_durchgefuehrt "Nach einen Ölwechsel (Service) ist die Ethanol Warmfahrwarnung zu unterdrücken.";
CM_ SG_ 1719 KBI_QBit_Aussen_Temp_gef "0x0 = gültiger Wert
0x1 = Ersatz-, Init- oder Fehlerwert";
CM_ SG_ 1719 KBI_RDK_Kalibrier_Anf "Bei gesetztem Bit soll die RDK die aktuellen Istdrücke zu Solldrücken übernehmen (nur bei Nichtverbau einer Headunit erforderlich).";
CM_ SG_ 1719 KBI_Reserve_Warnung_Sek "Signalisiert die Reservewarnung für die Energiespeicher CNG, LPG, HV-Batterie.
Fahrer wird gewarnt, dass er den Reservebereich erreicht hat. Fzg.spezifische Warnschwelle.";
CM_ SG_ 1719 KBI_Standzeit_02 "Zähler welcher die Standzeit des Motors wiedergibt.
Das Signal beschreibt den Anteil der Motor-Standzeit zwischen Zündung aus und nächstem Motorstart.";

CM_ SG_ 1720 KBI_BCmE_aktiv "Anzeige BCmE aktiv (BCmE-Screen oder Einsparhinweis in der Anzeige)";
CM_ SG_ 1720 KBI_GAP_Warn_Zeit_abgelaufen "Die Zeit, z.B. 1460 Tage, bis zur finalen Warnstufe der Gasanlagenprüfung wurde berechnet. Berechnung erfolgt auf Basis der aktuellen Uhrzeit mit einem Tageszähler. Keine Berechnung des Zählers bei Kl.30 AUS.";
CM_ SG_ 1720 KBI_Max_Tankinhalt "Mitteilung des maximalen Tankinhalts an das Reichweitenmodul";
CM_ SG_ 1720 KBI_Nachtanken_erkannt "Statusinformation Nachtankmodus";
CM_ SG_ 1720 KBI_Quittierung_cAQP "Quittierungsbestätigung vom Fahrer für Funktion cAQP";
CM_ SG_ 1720 KBI_Quittierung_Naesse "Quittierungsbestätigung vom Fahrer";
CM_ SG_ 1720 KBI_Reifenumfang "Mittlerer Radumfang aus der K-Zahl gerechnet in Millimeter.  Byte 2 Bit 5,4 reserviert, Byte 2 Bit 3..0 und Byte 1 Bit 7..0; Wertebereich 0..4096 mm
";
CM_ SG_ 1720 KBI_Reifenumfang_Sekundaer "Fahrzeuge mit unterschiedlichen Reifenumfängen Vorderachse / Hinterachse:

Primärachse: KBI_Reifenumfang
Sekundärachse: KBI_Reifenumfang_Sekundaer
";
CM_ SG_ 1720 KBI_Sparhinweis_quittiert "angezeigter Sparhinweis ist quittiert. Signal wird nach zwei Sendebotschaften wieder auf '0' gesetzt.";
CM_ SG_ 1720 KBI_Tankfuellstand_Prozent "Tankfüllstand in %";
CM_ SG_ 1720 KBI_Tankinhalt_hochaufl "angezeigter Tankinhalt hochauflösend zur Restreichweitenberechnung";
CM_ SG_ 1720 KBI_Variante "Zeigt an ob es sich um ein konventionelles Zeiger-Kombiinstrument handelt oder um eine Volldisplay-Kombiinstrument";
CM_ SG_ 1720 KBI_Variante_USA "In diesem Signal wird die HW-Variante des Kombis ausgegeben, ACC plausibilisiert auf dieses Signal hin seine US-Codierung";

CM_ SG_ 1722 SOK_Kombi_03_Signatur "Signatur im Rahmen der durch SOK geschützen Broadcast-Kommunikation

Geschützte Funktion: Wegstreckenschutz (Distance)
Geschützte Signale: KBI_Reifenumfang";

CM_ SG_ 2527679639 AuthTime_Trigger_Distribution "Funktion Authentische Zeit-Verteilung.Broadcast- Triggersignal für Bekanntgabe an alle Clients, dass ein neuer Zeitstempel im Zeitmaster vorliegt.";
CM_ SG_ 2527679639 KBI_Anzeige_ID_quittiert "Inforrmation über die vom Fahrer quittierte Anzeige";
CM_ SG_ 2527679639 KBI_FoD_VirtualCockpitPlus_State "Informs if the function on demand feature 'Virtual Cockpit Plus' is locked or not.";
CM_ SG_ 2527679639 KBI_Jokerkey "Betaetigung KBI Jokertaste";
CM_ SG_ 2527679639 KBI_Min_Tankinhalt "Tankanzeigeleerwert für Reichweitenberechnung, kein reales Kraftstoffvolumen";
CM_ SG_ 2527679639 KBI_RS_Druck_uebernehmen "Druck für Rundstreckenmodus übernehmen";
CM_ SG_ 2527679639 KBI_RS_Druckauswahl_Aktiv "Menue Druckauswahl aktiv";
CM_ SG_ 2527679639 KBI_RS_Mode_fortsetzen "Kombi fordert Fortsetzung des Rundstreckenmodus";
CM_ SG_ 2527679639 KBI_Rundstreckenmodus "Rundstreckenmodus Anforderung";
CM_ SG_ 2527679639 KBI_Weg_Zaehler "Inkrementaler Zähler des Kombis

PAG-Plattform:
Sendeart: Cyclic
Zykluszeit: 100ms

MLBevo_Konzern:
Sendeart: OnChange
Zykluszeit: 1000ms
Inhibitzeit: 100ms
";
CM_ SG_ 2527679639 KBI_Weg_Zaehler_F "Fehlerbit für den Inkrementalzähler Weg

PAG-Plattform:
Sendeart: Cyclic
Zykluszeit: 100ms

MLBevo_Konzern:
Sendeart: OnChange
Zykluszeit: 1000ms
Inhibitzeit: 100ms";

CM_ SG_ 2589283631 KBI_BC_Reset_E1 "Signalisierung BC Reset. Bei jedem BC Reset wird um 1 hochgezaehlt, bei 0x6 erfolgt Ueberlauf auf 0x1. Bei SG-Reset und Datenverlust vom BC wird der Wert SG_Reset angenommen. Während der Init-Phase wird Init gesendet, nach der Init-Phase der letzte gültig";
CM_ SG_ 2589283631 KBI_BC_Reset_E2 "Signalisierung BC Reset. Bei jedem BC Reset wird um 1 hochgezaehlt, 
bei 0x6 erfolgt Ueberlauf auf 0x1. Bei SG-Reset und Datenverlust vom 
BC wird der Wert SG_Reset angenommen. Während der Init-Phase wird Init gesendet, nach der Init-Phase der letzte gü";
CM_ SG_ 2589283631 KBI_BC_Reset_E3 "Signalisierung BC Reset. Bei jedem BC Reset wird um 1 hochgezaehlt, 
bei 0x6 erfolgt Ueberlauf auf 0x1. Bei SG-Reset und Datenverlust vom 
BC wird der Wert SG_Reset angenommen. Während der Init-Phase wird Init gesendet, nach der Init-Phase der letzte gü";
CM_ SG_ 2589283631 KBI_Kilometerstand_HiRes "Aufgrund gesetzlicher Anforderung muß Motor-SG den Kilometerstand an GST Mode$01 ausgeben.
Vgl. SAEJ1979 Festlegung zum PID$A6: Auflösung 0,1km / Bit
4 Byte länge (Doubleword)";
CM_ SG_ 2589283631 KBI_Tankinhalt_roh "Überträgt den ungefilterten und kalibrierten Tankinhalt (incl. Überhub im Vollbereich). Die Bereitstellung des Signale erfolgt nicht nach OBD Richtlinien. Die OBD konforme Verarbeitung erfolgt im Empfänger";

CM_ SG_ 2527679656 KBI_StartupAnimation "Synchronisierung der StartupAnimation zwischen Kombi und MMI.";

CM_ SG_ 2589283935 KBI_Curr_View "Aktueller auf dem Kombiinstrument dargestellter View";
CM_ SG_ 2589283935 KBI_Sec_View_Status "Anzeigezustand der Nebenanzeigen im Kombiinstrument";
CM_ SG_ 2589283935 KBI_View1 "Dieser View wird vom Kombiinstrument unterstützt";
CM_ SG_ 2589283935 KBI_View10 "Dieser View wird vom Kombiinstrument unterstützt";
CM_ SG_ 2589283935 KBI_View11 "Dieser View wird vom Kombiinstrument unterstützt";
CM_ SG_ 2589283935 KBI_View12 "Dieser View wird vom Kombiinstrument unterstützt";
CM_ SG_ 2589283935 KBI_View13 "Dieser View wird vom Kombiinstrument unterstützt";
CM_ SG_ 2589283935 KBI_View14 "Dieser View wird vom Kombiinstrument unterstützt";
CM_ SG_ 2589283935 KBI_View15 "Dieser View wird vom Kombiinstrument unterstützt";
CM_ SG_ 2589283935 KBI_View16 "Dieser View wird vom Kombiinstrument unterstützt";
CM_ SG_ 2589283935 KBI_View17 "Dieser View wird vom Kombiinstrument unterstützt";
CM_ SG_ 2589283935 KBI_View18 "Dieser View wird vom Kombiinstrument unterstützt";
CM_ SG_ 2589283935 KBI_View19 "Dieser View wird vom Kombiinstrument unterstützt";
CM_ SG_ 2589283935 KBI_View2 "Dieser View wird vom Kombiinstrument unterstützt";
CM_ SG_ 2589283935 KBI_View20 "Dieser View wird vom Kombiinstrument unterstützt";
CM_ SG_ 2589283935 KBI_View21 "Dieser View wird vom Kombiinstrument unterstützt";
CM_ SG_ 2589283935 KBI_View22 "Dieser View wird vom Kombiinstrument unterstützt";
CM_ SG_ 2589283935 KBI_View23 "Dieser View wird vom Kombiinstrument unterstützt";
CM_ SG_ 2589283935 KBI_View24 "Dieser View wird vom Kombiinstrument unterstützt";
CM_ SG_ 2589283935 KBI_View3 "Dieser View wird vom Kombiinstrument unterstützt";
CM_ SG_ 2589283935 KBI_View4 "Dieser View wird vom Kombiinstrument unterstützt";
CM_ SG_ 2589283935 KBI_View5 "Dieser View wird vom Kombiinstrument unterstützt";
CM_ SG_ 2589283935 KBI_View6 "Dieser View wird vom Kombiinstrument unterstützt";
CM_ SG_ 2589283935 KBI_View7 "Dieser View wird vom Kombiinstrument unterstützt";
CM_ SG_ 2589283935 KBI_View8 "Dieser View wird vom Kombiinstrument unterstützt";
CM_ SG_ 2589283935 KBI_View9 "Dieser View wird vom Kombiinstrument unterstützt";

CM_ SG_ 1614 KBI_HUD_Data_01 "Kommunikation Kombi zu HUD. Prio.texte zur gleichzeitigen Anzeige im Kombi und HUD.";
CM_ SG_ 1614 KBI_HUD_Data_02 "Kommunikation Kombi zu HUD. Prio.texte zur gleichzeitigen Anzeige im Kombi und HUD.";
CM_ SG_ 1614 KBI_HUD_Data_03 "Kommunikation Kombi zu HUD. Prio.texte zur gleichzeitigen Anzeige im Kombi und HUD.";
CM_ SG_ 1614 KBI_HUD_Data_04 "Kommunikation Kombi zu HUD. Prio.texte zur gleichzeitigen Anzeige im Kombi und HUD.";
CM_ SG_ 1614 KBI_HUD_Data_05 "Kommunikation Kombi zu HUD. Prio.texte zur gleichzeitigen Anzeige im Kombi und HUD.";
CM_ SG_ 1614 KBI_HUD_Data_06 "Kommunikation Kombi zu HUD. Prio.texte zur gleichzeitigen Anzeige im Kombi und HUD.";
CM_ SG_ 1614 KBI_HUD_Data_07 "Kommunikation Kombi zu HUD. Prio.texte zur gleichzeitigen Anzeige im Kombi und HUD.";
CM_ SG_ 1614 KBI_HUD_Data_08 "Kommunikation Kombi zu HUD. Prio.texte zur gleichzeitigen Anzeige im Kombi und HUD.";

CM_ SG_ 2621440276 KS_Kombi_Req_FD_Data "ISO-TP FD Datenkanal - FID2NA
Request Funktion 0x01 Komponentenschutz an Knoten";

CM_ SG_ 2621571348 KS_Kombi_Resp_FD_Data "ISO-TP FD Datenkanal - FID2NA
Response Knoten an Funktion 0x01 Komponentenschutz";

CM_ SG_ 919 aLDW_FoD_Status "Im CBEV wird aLDW durch FoD geschützt sein und so reicht für Kombi und HUd die PR/Zieldatencontainer basierte Codierung nicht mehr aus.

Aus diesem Grund brauch wir ein separates Signal, dass uns den Freischaltezustand mitteilt.";
CM_ SG_ 919 HC_Uss_Anforderung "Ansteuerung der vorderen PLA (VLS, VRS) und APS Sensoren (VL, VR)
0 = Ultraschallsensoren Aus
1 = Ultraschallsensoren An";
CM_ SG_ 919 LDW_DLC "distance to line, Abstand vom Fahrzeug zur Fahrbahnmarkierung
Der Wert gibt die Breite der Restspur zur Linie wieder (Abstand vom Fahrzeugäußerem zur Linie) (Wert POSITIV wenn Fahrzeug in der Spur - Wert NEGATIV wenn Fahrzeug über der Linie)";
CM_ SG_ 919 LDW_Frueh_Spaet "Im MMI eingestellter, aktiver Lenkeingriffszeitpunkt:
0: frueh, frueh aktiv
1: frueh, spaet aktiv
2: spaet, spaet aktiv
3: Fehler";
CM_ SG_ 919 LDW_Gong "Löst ein definiertes akustisches Signal aus.";
CM_ SG_ 919 LDW_Lernmodus_seitenabhaengig "Signal dient zur Ansteuerung von Funktionsanzeigen im Mitteldisplay des Kombiinstruments für die Seitenabhänige Liniendetektion (neue Funktion ab D4)";
CM_ SG_ 919 LDW_Seite_DLCTLC "Zuordnung auf welche Seite sich LDW_DLC bzw. LDW_TLC beziehen";
CM_ SG_ 919 LDW_Status_Anzeige "Signal dient zur Ansteuerung von Funktionsanzeigen im Mitteldisplay des Kombiinstruments.";
CM_ SG_ 919 LDW_Status_LED_gruen " ";
CM_ SG_ 919 LDW_Texte "Bei Anzeige eines Fehlertextes im Kombi ertönt ein akustisches Signal";
CM_ SG_ 919 LDW_TLC "time to line, Zeit bis das Fahrzeug die Fahrbahnmarkierung überquert";

CM_ SG_ 810 EPS_01_CRC "Für MLB:
'Berechnung siehe Lastenheft 'Kommunikationsabsicherung für FlexRay und CAN''

Ab MQB und MLBevo:
'Berechnung siehe Lastenheft 'End-to-End Kommunikationsabsicherung''

Endwerte siehe Begleitdokument 'S-PDU Kennungsfolgen'
";
CM_ SG_ 810 EPS_Akustiksignal "Ansteuerung eines Akustiksignals im Kombi";
CM_ SG_ 810 EPS_Anf_KL "Nach Überschreiten einer oberen Grenztemperatur innerhalb des Steuergerätes der Lenkhilfe fordert die EPS die Zuschaltung einer externen Kühlung durch den Kühlerlüfter an.
Es besteht kein technischer Zusammenhang mit einer Batterie_ab - Erkennung in der ";
CM_ SG_ 810 EPS_ARA_Status "Anforderung vom Anhängerrangierassistent. 
16 Statuswerte";
CM_ SG_ 810 EPS_Charisma_FahrPr "MLBevo: Aktuelles Fahrprogramm des Charisma-Teilnehmers (siehe Systemlastenheft Drive Select)
MQB: Istwert der Kennlinie (siehe Systemlastenheft MQB FPA)";
CM_ SG_ 810 EPS_Charisma_Status "Rückmeldung an den Charisma-Master

Wert 0x3 ist nur für Fahrzeuge ab MQB relevant";
CM_ SG_ 810 EPS_Endanschlag "Die EPS muss applikativ ein Lenkhubmapping umsetzen. Das Lenkhubmapping muss für jeden NR-Reglerstatus den Defaultendanschlag oder die Lenkhubaufweitung zuordnen.";
CM_ SG_ 810 EPS_Fehlerlampe "Steuert direkt die Fehlerlampe Lenkhilfe (gelb); kein Aufprüfen bei Neustart, keine Rückleseinformation in Kombi-Botschaft (nur für VW526 Hybrid)";
CM_ SG_ 810 EPS_Lenkerposition "Position des Lenkers im Fahrzeug";
CM_ SG_ 810 EPS_PLA_Abbruch "Art des Fehlers ohne Eintrag, 16 Werte möglich (siehe LH EPS/PLA)";
CM_ SG_ 810 EPS_PLA_Fehler "Art des Fehlers ohne Eintrag, 16 Werte möglich (siehe LH EPS/PLA)";
CM_ SG_ 810 EPS_PLA_Status "Zustand der Statusmaschine der EPS für die korrespondierenden Statusmaschine im PLA.";
CM_ SG_ 810 EPS_SpannungsAnf "Forderung des EPS-SG's zur Spannungsanhebung.";
CM_ SG_ 810 EPS_VZ_Zst_Offset_Geradeaus "Vorzeichen des Offset Geradeauslauf gem. Schnittstellenbeschreibung Lenkhilfe";
CM_ SG_ 810 EPS_Warnungen "Diese Bits werden verwendet, um im Kombi Texte, Lampen oder Bilder für die Lenkhilfe darzustellen
Audi MLB/RSe:
Text_1: Lenkung defekt (Prio 1)
Text_2: Lenkung Systemstörung (Prio 2)
VW526:
Text_1 (ID_TXT_1026.1): Ausfall Lenkunterstützung
Text_2 (I";
CM_ SG_ 810 EPS_Zst_Offset_Geradeaus "Lenkungsinterner Offset Geradeauslauf Nutzung gemaess Schnittstellendokumentation Lenkhilfe";

CM_ SG_ 981 BCM1_Abblendlicht_Anf "Anforderung Abblendlicht
";
CM_ SG_ 981 BCM1_Adaptive_Lichtvert_Anf "Funktion 'Adaptive Lichtverteilung' im AFS-SG  Ein- und Ausschalten";
CM_ SG_ 981 BCM1_Allwetterlicht_Anf "Anforderung eines Allwetterlichts (über AFS-SG realisiert): Licht für schlechte Sichtverhältnisse";
CM_ SG_ 981 BCM1_Animationssperrung "Sperrung der Scheinwerfer- und Heckleuchten-Animationen. Grund für Sperrung sind allgemeine Rahmenbedingungen, wie beispielseweise eine LDS-Stellung ungleich 'Auto'";
CM_ SG_ 981 BCM1_Autobahnlicht_Anf "Anforderung Autobahnlicht
";
CM_ SG_ 981 BCM1_CH_aktiv "Coming Home (zusätzlich zum Signal 'BCM1_CH_LH_aktiv' in der Botschaft BCM1_01)";
CM_ SG_ 981 BCM1_CH_LH_aktiv "Status Comming / Leaving Home
";
CM_ SG_ 981 BCM1_Fernlicht_Anf "Anforderung Fernlicht
";
CM_ SG_ 981 BCM1_Gleitende_Leuchtw_Anf "Funktion 'Gleitende Leuchtweite' im AFS-SG  freischalten";
CM_ SG_ 981 BCM1_GLW_Fernlicht_Anf "Harte Fernlichtanforderung von BCM1 an die Funktion 'gleitende Leuchtweite' im AFS-SG";
CM_ SG_ 981 BCM1_Kurvenlicht_links_Anf "Ansteuerung linkes Kurvenlicht/Abbiegelicht duch BCM1";
CM_ SG_ 981 BCM1_Kurvenlicht_rechts_Anf "Ansteuerung rechtes Kurvenlicht/Abbiegelicht duch BCM1";
CM_ SG_ 981 BCM1_LH_aktiv "Leaving Home (zusätzlich zum Signal 'BCM1_CH_LH_aktiv' in der Botschaft BCM1_01)";
CM_ SG_ 981 BCM1_Nebellicht_Anf "Anforderung Nebellicht
";
CM_ SG_ 981 BCM1_Nebelschluss_Ahg_Anf "Anforderung: Nebelschlusslicht Anhänger (Sollzustand)
";
CM_ SG_ 981 BCM1_Nebelschluss_Fzg_Anf "Anforderung: Nebelschlusslicht Fahrzeug (Sollzustand)";
CM_ SG_ 981 BCM1_Parklicht_li_Anf "Anforderung: Parklicht links (Sollzustand)
";
CM_ SG_ 981 BCM1_Parklicht_re_Anf "Anforderung: Parklicht rechts (Sollzustand)
";
CM_ SG_ 981 BCM1_Regenlicht_Anf "Anforderung: Regenlicht (Sollzustand)
";
CM_ SG_ 981 BCM1_Schlusslicht_Anf "Anforderung: Schlusslicht Fahrzeug (Sollzustand)
";
CM_ SG_ 981 BCM1_Signaturlicht_Anf "Signal zur Anforderung des Signaturlichts";
CM_ SG_ 981 BCM1_Standlicht_Anf "Anforderung: Schlusslicht (Sollzustand)";
CM_ SG_ 981 BCM1_Tagfahrlicht_Anf "Anforderung: Tagfahrlicht (Sollzustand)";
CM_ SG_ 981 BCM1_Touristen_Licht_Anf "Anforderung: Touristenlicht (Sollzustand)";
CM_ SG_ 981 BCM1_Umfeldleuchten_Anf "Anforderung für Umfeldleuchten";
CM_ SG_ 981 BCM_Rueckfahrlicht_Anf "Anforderung Rückfahrlicht (Sollzustand). 
Das Signal wird entprellt (typisch 400ms) und bei KL15EIN gesendet. Das Signal ist unabhängig von der Position des Heckdeckels (kein Überhitzungsschutz).";
CM_ SG_ 981 Licht_Anf_01_BZ "4bit Botschaftszaehler, wird mit jeder Sendebotschaft inkrementiert";
CM_ SG_ 981 Licht_Anf_01_CRC "Für MLB:
'Berechnung siehe Lastenheft 'Kommunikationsabsicherung für FlexRay und CAN''

Ab MQB und MLBevo:
'Berechnung siehe Lastenheft 'End-to-End Kommunikationsabsicherung''

Endwerte siehe Begleitdokument 'S-PDU Kennungsfolgen'";
CM_ SG_ 981 TFL_Matrix_Variante01_Anf "Gibt die einzustellende Variante der Tagfahrlicht-Matrix an.";
CM_ SG_ 981 TFL_Matrix_Variante02_Anf "Gibt die einzustellende Variante der Tagfahrlicht-Matrix an.";
CM_ SG_ 981 TFL_Matrix_Variante03_Anf "Gibt die einzustellende Variante der Tagfahrlicht-Matrix an.";
CM_ SG_ 981 TFL_Matrix_Variante04_Anf "Gibt die einzustellende Variante der Tagfahrlicht-Matrix an.";

CM_ SG_ 982 BCM2_Bremsl_durch_ECD "Bremslicht (ECD-Bremsung)
";
CM_ SG_ 982 BCM2_Bremsl_durch_ECD_invers "Inversbit Bremslicht (ECD-Bremsung) (Kommunikationsabsicherung)";
CM_ SG_ 982 LH_3_Bremsl_def "Fehlerstatus 3. Bremsleuchte
";
CM_ SG_ 982 LH_Aussenlicht_def "Aussenlicht kann nicht mehr korrekt angesteuert werden (EEPROM Codierung kann nicht mehr ausgelesen werden)
";
CM_ SG_ 982 LH_Blinker_HL_akt "Blinker hinten links
";
CM_ SG_ 982 LH_Blinker_HR_akt "Blinker hinten rechts
";
CM_ SG_ 982 LH_Blinker_li_def "Fehlerstatus Blinker hinten links
";
CM_ SG_ 982 LH_Blinker_re_def "Fehlerstatus Blinker hinten rechts
";
CM_ SG_ 982 LH_Brems_Blk_li_def "Konfiguration BRL + BLK links 
";
CM_ SG_ 982 LH_Brems_Blk_re_def "Konfiguration BRL + BLK rechts
";
CM_ SG_ 982 LH_Bremsl_li_def "Fehlerstatus Bremslicht hinten links (Detektion Einzelausfall)
";
CM_ SG_ 982 LH_Bremsl_li_ges_def "Fehlerstatus Bremslicht hinten links (Detektion Totalausfall)
";
CM_ SG_ 982 LH_Bremsl_re_def "Fehlerstatus Bremslicht hinten rechts  (Detektion Einzelausfall)
";
CM_ SG_ 982 LH_Bremsl_re_ges_def "Fehlerstatus Bremslicht hinten rechts (Detektion Totalausfall)";
CM_ SG_ 982 LH_Bremslicht_H_aktiv "Bremslicht hinten
";
CM_ SG_ 982 LH_Diag_LED_li_def "Heckleuchte links defekt";
CM_ SG_ 982 LH_Diag_LED_re_def "Heckleuchte rechts defekt";
CM_ SG_ 982 LH_Diag_Status_li_def "Außenlicht Diagnose 
Systemstörung links";
CM_ SG_ 982 LH_Diag_Status_re_def "Außenlicht Diagnose Systemstörung rechts ";
CM_ SG_ 982 LH_Kennzl_def "Fehlerstatus Kennzeichenbeleuchtung hinten
";
CM_ SG_ 982 LH_Nebel_li_def "Fehlererkennung Nebelschlusslicht hinten links";
CM_ SG_ 982 LH_Nebel_mi_def "Fehlererkennung Nebelschlusslicht hinten Mitte


";
CM_ SG_ 982 LH_Nebel_re_def "Fehlererkennung Nebelschlusslicht hinten rechts
";
CM_ SG_ 982 LH_Nebelschluss_aktiv "Nebelschlusslicht
";
CM_ SG_ 982 LH_Parklicht_HL_aktiv "Parklicht hinten links 
";
CM_ SG_ 982 LH_Parklicht_HR_aktiv "Parklicht hinten rechts 
";
CM_ SG_ 982 LH_Rueckf_li_def "Fehlererkennung Rückfahrlicht hinten links
";
CM_ SG_ 982 LH_Rueckf_mi_def "Fehlererkennung Rückfahrlicht Mitte
";
CM_ SG_ 982 LH_Rueckf_re_def "Fehlererkennung Rückfahrlicht hinten rechts
";
CM_ SG_ 982 LH_Rueckfahrlicht_aktiv "Rueckfahrlicht";
CM_ SG_ 982 LH_Schluss_Brems_li_def "Konfiguration SL+ BRL + PL links und SL+ BRL  links
";
CM_ SG_ 982 LH_Schluss_Brems_Nebel_li_def "Signal wird gesetzt, wenn eine Unterbrechung oder  ein Kurzschluss am Lampenausgang für Schluss_Brems_Nebelschlusslicht erkannt wird.";
CM_ SG_ 982 LH_Schluss_Brems_Nebel_re_def "Signal wird gesetzt, wenn eine Unterbrechung oder  ein Kurzschluss am Lampenausgang für Schluss_Brems_Nebelschlusslicht erkannt wird.";
CM_ SG_ 982 LH_Schluss_Brems_re_def "Konfiguration SL+ BRL + PL rechts und SL+ BRL  rechts
";
CM_ SG_ 982 LH_Schluss_Nebel_li_def "Konfiguration SL + NSL links oder SL + NSL + PL links
";
CM_ SG_ 982 LH_Schluss_Nebel_re_def "Konfiguration SL + NSL rechts oder SL + NSL + PL rechts
";
CM_ SG_ 982 LH_Schlusslicht_li_def "Fehlererkennung Schlusslicht hinten links
";
CM_ SG_ 982 LH_Schlusslicht_re_def "Fehlererkennung Schlusslicht hinten rechts";
CM_ SG_ 982 LH_SL_BRL_BLK_li_def "Konfiguration SL + BRL + BLK links oder SL + BRL + BLK + PL links
";
CM_ SG_ 982 LH_SL_BRL_BLK_re_def "Konfiguration SL + BRL + BLK rechts oder SL + BRL + BLK + PL rechts
";
CM_ SG_ 982 LH_Standlicht_H_aktiv "Standlicht hinten
";
CM_ SG_ 982 LH_Zusatzschlussl_def "mindestens ein Zusatzschlusslicht in der Heckbeleuchtung defekt.";
CM_ SG_ 982 Licht_hinten_01_BZ "überlaufender 4bit Botschaftszaehler; wird in jeder Sendebotschaft inkrementiert";
BA_DEF_REL_ BU_SG_REL_  "GenSigTimeoutTime" INT 0 65535;
BA_DEF_ BO_  "DiagRequest" ENUM "No", "Yes";
BA_DEF_ BO_  "DiagResponse" ENUM "No", "Yes";
BA_DEF_ BO_  "DiagState" ENUM "No", "Yes";
BA_DEF_ BO_  "GenMsgChkConstant" HEX 0 4095;
BA_DEF_ BO_  "GenMsgCycleTime" INT 0 65535;
BA_DEF_ BO_  "GenMsgCycleTimeFast" INT 0 65535;
BA_DEF_ BO_  "GenMsgDelayTime" INT 0 100000;
BA_DEF_ BO_  "GenMsgILSupport" ENUM "No", "Yes";
BA_DEF_ BO_  "GenMsgNrOfRepetition" INT 0 100;
BA_DEF_ BO_  "GenMsgPDUConstants" STRING;
BA_DEF_ BO_  "GenMsgSendType" ENUM "Cyclic", "not_used", "not_used", "not_used", "not_used", "not_used", "not_used", "IfActive", "NoMsgSendType";
BA_DEF_ BO_  "GenMsgStartDelayTime" INT 0 100000;
BA_DEF_ BO_  "NmMessage" ENUM "No", "Yes";
BA_DEF_ BO_  "NmhMessage" ENUM "No", "Yes";
BA_DEF_ BO_  "MsgType" ENUM "Application", "NM ", "NMH", "TP2.0", "ISO-TP ", "BAP", "EID", "KS", "XCP_PRE_CONFIGURED", "XCP_RUNTIME_CONFIGURED";
BA_DEF_ BO_  "VAGTP20_API" HEX 0 255;
BA_DEF_ BO_  "VAGTP20_DynConnection" ENUM "No", "Yes";
BA_DEF_ BO_  "VAGTP20_DynSetup" ENUM "No", "Yes";
BA_DEF_ BO_  "VAGTP20_StatConnection" ENUM "No", "Yes";
BA_DEF_ BO_  "CANFD_BRS" ENUM "0", "1";
BA_DEF_ BO_  "VFrameFormat" ENUM "StandardCAN", "ExtendedCAN", "reserved", "reserved", "reserved", "reserved", "reserved", "reserved", "reserved", "reserved", "reserved", "reserved", "reserved", "reserved", "StandardCAN_FD", "ExtendedCAN_FD";
BA_DEF_ SG_  "GenSigActiveRepetitions" INT -2147483648 2147483647;
BA_DEF_ SG_  "GenSigInactiveValue" INT -2147483648 2147483647;
BA_DEF_ SG_  "GenSigSendType" ENUM "Cyclic", "OnWrite", "OnWriteWithRepetition", "OnChange", "OnChangeWithRepetition", "IfActive", "IfActiveWithRepetition", "NoSigSendType", "OnChangeAndIfActive", "OnChangeAndIfActiveWithRepetition";
BA_DEF_ SG_  "GenSigStartValue" INT -2147483648 2147483647;
BA_DEF_ SG_  "NWM-WakeupAllowed" ENUM "No", "Yes";
BA_DEF_ SG_  "GenSigFuncType" ENUM "NoFunction", "MsgCounter", "CRC-8", "XOR", "XOR-2", "DatedBit", "SW-Kl15", "CHK", "Constant", "Protocol", "CRC-8-SAE_J1850", "CRC-32", "DataLength", "DataID", "MsgCounter16", "SOK-Signatur", "Cluster";
BA_DEF_ SG_  "GenSigSwitchedByIgnition" ENUM "No", "Yes";
BA_DEF_ SG_  "Fehlerwert" HEX 0 2147483647;
BA_DEF_ SG_  "GenSigMissingSourceValue" HEX 0 2147483647;
BA_DEF_DEF_REL_  "GenSigTimeoutTime" 0;
BA_DEF_DEF_  "DiagRequest" "No";
BA_DEF_DEF_  "DiagResponse" "No";
BA_DEF_DEF_  "DiagState" "No";
BA_DEF_DEF_  "GenMsgChkConstant" 0;
BA_DEF_DEF_  "GenMsgCycleTime" 0;
BA_DEF_DEF_  "GenMsgCycleTimeFast" 0;
BA_DEF_DEF_  "GenMsgDelayTime" 0;
BA_DEF_DEF_  "GenMsgILSupport" "No";
BA_DEF_DEF_  "GenMsgNrOfRepetition" 0;
BA_DEF_DEF_  "GenMsgPDUConstants" "";
BA_DEF_DEF_  "GenMsgSendType" "NoMsgSendType";
BA_DEF_DEF_  "GenMsgStartDelayTime" 0;
BA_DEF_DEF_  "NmMessage" "No";
BA_DEF_DEF_  "NmhMessage" "No";
BA_DEF_DEF_  "MsgType" "Application";
BA_DEF_DEF_  "VAGTP20_API" 0;
BA_DEF_DEF_  "VAGTP20_DynConnection" "No";
BA_DEF_DEF_  "VAGTP20_DynSetup" "No";
BA_DEF_DEF_  "VAGTP20_StatConnection" "No";
BA_DEF_DEF_  "CANFD_BRS" "1";
BA_DEF_DEF_  "VFrameFormat" "StandardCAN";
BA_DEF_DEF_  "GenSigActiveRepetitions" 0;
BA_DEF_DEF_  "GenSigInactiveValue" 0;
BA_DEF_DEF_  "GenSigSendType" "NoSigSendType";
BA_DEF_DEF_  "GenSigStartValue" 0;
BA_DEF_DEF_  "NWM-WakeupAllowed" "No";
BA_DEF_DEF_  "GenSigFuncType" "NoFunction";
BA_DEF_DEF_  "GenSigSwitchedByIgnition" "Yes";
BA_DEF_DEF_  "Fehlerwert" 0;
BA_DEF_DEF_  "GenSigMissingSourceValue" 0;
BA_ "GenMsgCycleTime" BO_ 1426 200;
BA_ "GenMsgDelayTime" BO_ 1426 20;
BA_ "GenMsgILSupport" BO_ 1426 1;
BA_ "GenMsgSendType" BO_ 1426 0;
BA_ "VFrameFormat" BO_ 1426 14;
BA_ "GenMsgChkConstant" BO_ 960 195;
BA_ "GenMsgCycleTime" BO_ 960 100;
BA_ "GenMsgDelayTime" BO_ 960 10;
BA_ "GenMsgILSupport" BO_ 960 1;
BA_ "GenMsgPDUConstants" BO_ 960 "0xc3,0xc3,0xc3,0xc3,0xc3,0xc3,0xc3,0xc3,0xc3,0xc3,0xc3,0xc3,0xc3,0xc3,0xc3,0xc3";
BA_ "GenMsgSendType" BO_ 960 0;
BA_ "VFrameFormat" BO_ 960 14;
BA_ "GenMsgCycleTime" BO_ 2463978753 1000;
BA_ "GenMsgCycleTimeFast" BO_ 2463978753 100;
BA_ "GenMsgDelayTime" BO_ 2463978753 10;
BA_ "GenMsgILSupport" BO_ 2463978753 1;
BA_ "GenMsgNrOfRepetition" BO_ 2463978753 5;
BA_ "GenMsgPDUConstants" BO_ 2463978753 "0x80,0xf1,0xa5,0xaf,0x94,0x59,0xe8,0x8c,0x03,0xd4,0xf5,0x5e,0xec,0x73,0x81,0x50";
BA_ "GenMsgSendType" BO_ 2463978753 0;
BA_ "VFrameFormat" BO_ 2463978753 15;
BA_ "GenMsgCycleTime" BO_ 1420 1000;
BA_ "GenMsgCycleTimeFast" BO_ 1420 20;
BA_ "GenMsgDelayTime" BO_ 1420 10;
BA_ "GenMsgILSupport" BO_ 1420 1;
BA_ "GenMsgNrOfRepetition" BO_ 1420 5;
BA_ "GenMsgPDUConstants" BO_ 1420 "0x9b,0xb5,0x9d,0x06,0x01,0xe7,0x8f,0xc1,0xd0,0x10,0x47,0xe9,0xd3,0xca,0x05,0xf0";
BA_ "GenMsgSendType" BO_ 1420 0;
BA_ "VFrameFormat" BO_ 1420 14;
BA_ "GenMsgCycleTime" BO_ 1646 2000;
BA_ "GenMsgDelayTime" BO_ 1646 200;
BA_ "GenMsgILSupport" BO_ 1646 1;
BA_ "GenMsgSendType" BO_ 1646 0;
BA_ "VFrameFormat" BO_ 1646 14;
BA_ "GenMsgCycleTime" BO_ 949 100;
BA_ "GenMsgILSupport" BO_ 949 1;
BA_ "GenMsgSendType" BO_ 949 0;
BA_ "VFrameFormat" BO_ 949 14;
BA_ "GenMsgCycleTime" BO_ 1640 200;
BA_ "GenMsgCycleTimeFast" BO_ 1640 100;
BA_ "GenMsgDelayTime" BO_ 1640 50;
BA_ "GenMsgILSupport" BO_ 1640 1;
BA_ "GenMsgNrOfRepetition" BO_ 1640 5;
BA_ "GenMsgSendType" BO_ 1640 0;
BA_ "VFrameFormat" BO_ 1640 14;
BA_ "GenMsgCycleTime" BO_ 2527679635 2000;
BA_ "GenMsgDelayTime" BO_ 2527679635 200;
BA_ "GenMsgILSupport" BO_ 2527679635 1;
BA_ "GenMsgSendType" BO_ 2527679635 0;
BA_ "VFrameFormat" BO_ 2527679635 15;
BA_ "GenMsgCycleTime" BO_ 1505 200;
BA_ "GenMsgILSupport" BO_ 1505 1;
BA_ "GenMsgSendType" BO_ 1505 0;
BA_ "VFrameFormat" BO_ 1505 14;
BA_ "GenMsgCycleTime" BO_ 2549088305 500;
BA_ "GenMsgILSupport" BO_ 2549088305 1;
BA_ "GenMsgSendType" BO_ 2549088305 0;
BA_ "VFrameFormat" BO_ 2549088305 15;
BA_ "GenMsgCycleTime" BO_ 2549088272 500;
BA_ "GenMsgILSupport" BO_ 2549088272 1;
BA_ "GenMsgSendType" BO_ 2549088272 0;
BA_ "VFrameFormat" BO_ 2549088272 15;
BA_ "GenMsgCycleTime" BO_ 2549088283 500;
BA_ "GenMsgILSupport" BO_ 2549088283 1;
BA_ "GenMsgSendType" BO_ 2549088283 0;
BA_ "VFrameFormat" BO_ 2549088283 15;
BA_ "GenMsgCycleTime" BO_ 2549088276 500;
BA_ "GenMsgILSupport" BO_ 2549088276 1;
BA_ "GenMsgSendType" BO_ 2549088276 0;
BA_ "VFrameFormat" BO_ 2549088276 15;
BA_ "GenMsgCycleTime" BO_ 779 50;
BA_ "GenMsgILSupport" BO_ 779 1;
BA_ "GenMsgSendType" BO_ 779 0;
BA_ "VFrameFormat" BO_ 779 14;
BA_ "GenMsgCycleTime" BO_ 1719 1000;
BA_ "GenMsgDelayTime" BO_ 1719 100;
BA_ "GenMsgILSupport" BO_ 1719 1;
BA_ "GenMsgSendType" BO_ 1719 0;
BA_ "VFrameFormat" BO_ 1719 14;
BA_ "GenMsgCycleTime" BO_ 1720 1000;
BA_ "GenMsgILSupport" BO_ 1720 1;
BA_ "GenMsgSendType" BO_ 1720 0;
BA_ "VFrameFormat" BO_ 1720 14;
BA_ "GenMsgCycleTime" BO_ 1722 1000;
BA_ "GenMsgSendType" BO_ 1722 0;
BA_ "VFrameFormat" BO_ 1722 14;
BA_ "GenMsgCycleTime" BO_ 2527679639 1000;
BA_ "GenMsgCycleTimeFast" BO_ 2527679639 100;
BA_ "GenMsgDelayTime" BO_ 2527679639 100;
BA_ "GenMsgILSupport" BO_ 2527679639 1;
BA_ "GenMsgNrOfRepetition" BO_ 2527679639 5;
BA_ "GenMsgSendType" BO_ 2527679639 0;
BA_ "VFrameFormat" BO_ 2527679639 15;
BA_ "GenMsgCycleTime" BO_ 2589283631 500;
BA_ "GenMsgILSupport" BO_ 2589283631 1;
BA_ "GenMsgSendType" BO_ 2589283631 0;
BA_ "VFrameFormat" BO_ 2589283631 15;
BA_ "GenMsgCycleTime" BO_ 2527679656 1000;
BA_ "GenMsgDelayTime" BO_ 2527679656 50;
BA_ "GenMsgILSupport" BO_ 2527679656 1;
BA_ "GenMsgSendType" BO_ 2527679656 0;
BA_ "VFrameFormat" BO_ 2527679656 15;
BA_ "GenMsgCycleTime" BO_ 2589283935 1000;
BA_ "GenMsgCycleTimeFast" BO_ 2589283935 100;
BA_ "GenMsgDelayTime" BO_ 2589283935 50;
BA_ "GenMsgILSupport" BO_ 2589283935 1;
BA_ "GenMsgNrOfRepetition" BO_ 2589283935 5;
BA_ "GenMsgSendType" BO_ 2589283935 0;
BA_ "VFrameFormat" BO_ 2589283935 15;
BA_ "GenMsgCycleTime" BO_ 1614 1000;
BA_ "GenMsgDelayTime" BO_ 1614 20;
BA_ "GenMsgILSupport" BO_ 1614 1;
BA_ "GenMsgSendType" BO_ 1614 0;
BA_ "VFrameFormat" BO_ 1614 14;
BA_ "MsgType" BO_ 2621440276 4;
BA_ "VFrameFormat" BO_ 2621440276 15;
BA_ "MsgType" BO_ 2621571348 4;
BA_ "VFrameFormat" BO_ 2621571348 15;
BA_ "GenMsgCycleTime" BO_ 919 100;
BA_ "GenMsgDelayTime" BO_ 919 20;
BA_ "GenMsgILSupport" BO_ 919 1;
BA_ "GenMsgSendType" BO_ 919 0;
BA_ "VFrameFormat" BO_ 919 14;
BA_ "GenMsgChkConstant" BO_ 810 41;
BA_ "GenMsgCycleTime" BO_ 810 50;
BA_ "GenMsgILSupport" BO_ 810 1;
BA_ "GenMsgPDUConstants" BO_ 810 "0x29,0x29,0x29,0x29,0x29,0x29,0x29,0x29,0x29,0x29,0x29,0x29,0x29,0x29,0x29,0x29";
BA_ "GenMsgSendType" BO_ 810 0;
BA_ "VFrameFormat" BO_ 810 14;
BA_ "GenMsgCycleTime" BO_ 981 100;
BA_ "GenMsgDelayTime" BO_ 981 50;
BA_ "GenMsgILSupport" BO_ 981 1;
BA_ "GenMsgPDUConstants" BO_ 981 "0xc5,0x39,0xc7,0xf9,0x92,0xd8,0x24,0xce,0xf1,0xb5,0x7a,0xc4,0xbc,0x60,0xe3,0xd1";
BA_ "GenMsgSendType" BO_ 981 0;
BA_ "VFrameFormat" BO_ 981 14;
BA_ "GenMsgCycleTime" BO_ 982 100;
BA_ "GenMsgDelayTime" BO_ 982 20;
BA_ "GenMsgILSupport" BO_ 982 1;
BA_ "GenMsgSendType" BO_ 982 0;
BA_ "VFrameFormat" BO_ 982 14;
BA_ "GenSigSendType" SG_ 1426 KY_Aktive_LFScans 3;
BA_ "GenSigSwitchedByIgnition" SG_ 1426 KY_Aktive_LFScans 0;
BA_ "GenSigSendType" SG_ 1426 KY_AnzKoord_Info 3;
BA_ "GenSigSwitchedByIgnition" SG_ 1426 KY_AnzKoord_Info 0;
BA_ "GenSigSendType" SG_ 1426 KY_EasyClose_Abbruch 3;
BA_ "GenSigSwitchedByIgnition" SG_ 1426 KY_EasyClose_Abbruch 0;
BA_ "GenSigSendType" SG_ 1426 KY_EasyClose_Status 3;
BA_ "GenSigSwitchedByIgnition" SG_ 1426 KY_EasyClose_Status 0;
BA_ "GenSigSendType" SG_ 1426 KY_Fzg_Verlassen_erkannt 3;
BA_ "GenSigSwitchedByIgnition" SG_ 1426 KY_Fzg_Verlassen_erkannt 0;
BA_ "GenSigSendType" SG_ 1426 KY_Fzg_Zugang_erkannt 3;
BA_ "GenSigSwitchedByIgnition" SG_ 1426 KY_Fzg_Zugang_erkannt 0;
BA_ "GenSigSendType" SG_ 1426 KY_Gestik_HD 3;
BA_ "GenSigSwitchedByIgnition" SG_ 1426 KY_Gestik_HD 0;
BA_ "GenSigSendType" SG_ 1426 KY_Gong_600 3;
BA_ "GenSigSwitchedByIgnition" SG_ 1426 KY_Gong_600 0;
BA_ "GenSigSendType" SG_ 1426 KY_HD_Auffahrt 3;
BA_ "GenSigSwitchedByIgnition" SG_ 1426 KY_HD_Auffahrt 0;
BA_ "GenSigSendType" SG_ 1426 KY_HD_Zufahrt 3;
BA_ "GenSigSwitchedByIgnition" SG_ 1426 KY_HD_Zufahrt 0;
BA_ "GenSigSendType" SG_ 1426 KY_ID_Geber1_im_Fzg 3;
BA_ "GenSigSwitchedByIgnition" SG_ 1426 KY_ID_Geber1_im_Fzg 0;
BA_ "GenSigSendType" SG_ 1426 KY_ID_Geber2_im_Fzg 3;
BA_ "GenSigSwitchedByIgnition" SG_ 1426 KY_ID_Geber2_im_Fzg 0;
BA_ "GenSigSendType" SG_ 1426 KY_ID_Geber3_im_Fzg 3;
BA_ "GenSigSwitchedByIgnition" SG_ 1426 KY_ID_Geber3_im_Fzg 0;
BA_ "GenSigSendType" SG_ 1426 KY_ID_Geber4_im_Fzg 3;
BA_ "GenSigSwitchedByIgnition" SG_ 1426 KY_ID_Geber4_im_Fzg 0;
BA_ "GenSigSendType" SG_ 1426 KY_ID_Geber_Suche 3;
BA_ "GenSigSwitchedByIgnition" SG_ 1426 KY_ID_Geber_Suche 0;
BA_ "GenSigSendType" SG_ 1426 KY_LF_Aktiv 3;
BA_ "GenSigSwitchedByIgnition" SG_ 1426 KY_LF_Aktiv 0;
BA_ "GenSigSendType" SG_ 1426 KY_Meldungen 3;
BA_ "GenSigSwitchedByIgnition" SG_ 1426 KY_Meldungen 0;
BA_ "GenSigSendType" SG_ 1426 KY_Passiv_Autolock 3;
BA_ "GenSigSwitchedByIgnition" SG_ 1426 KY_Passiv_Autolock 0;
BA_ "GenSigSendType" SG_ 1426 KY_Passiv_Autolock_Akt 3;
BA_ "GenSigSwitchedByIgnition" SG_ 1426 KY_Passiv_Autolock_Akt 0;
BA_ "GenSigSendType" SG_ 1426 KY_Passiv_Autolock_Menue 3;
BA_ "GenSigSwitchedByIgnition" SG_ 1426 KY_Passiv_Autolock_Menue 0;
BA_ "GenSigSendType" SG_ 1426 KY_Passiv_Autounlock 3;
BA_ "GenSigSwitchedByIgnition" SG_ 1426 KY_Passiv_Autounlock 0;
BA_ "GenSigSendType" SG_ 1426 KY_Schluesselposition_1 3;
BA_ "GenSigSwitchedByIgnition" SG_ 1426 KY_Schluesselposition_1 0;
BA_ "GenSigSendType" SG_ 1426 KY_Schluesselposition_2 3;
BA_ "GenSigSwitchedByIgnition" SG_ 1426 KY_Schluesselposition_2 0;
BA_ "GenSigSendType" SG_ 1426 KY_Schluesselposition_3 3;
BA_ "GenSigSwitchedByIgnition" SG_ 1426 KY_Schluesselposition_3 0;
BA_ "GenSigSendType" SG_ 1426 KY_Schluesselposition_4 3;
BA_ "GenSigSwitchedByIgnition" SG_ 1426 KY_Schluesselposition_4 0;
BA_ "GenSigSendType" SG_ 1426 KY_Schluesselposition_5 3;
BA_ "GenSigSwitchedByIgnition" SG_ 1426 KY_Schluesselposition_5 0;
BA_ "GenSigSendType" SG_ 1426 KY_Schluesselposition_6 3;
BA_ "GenSigSwitchedByIgnition" SG_ 1426 KY_Schluesselposition_6 0;
BA_ "GenSigSendType" SG_ 1426 KY_Schluesselposition_7 3;
BA_ "GenSigSwitchedByIgnition" SG_ 1426 KY_Schluesselposition_7 0;
BA_ "GenSigSendType" SG_ 1426 KY_Schluesselposition_8 3;
BA_ "GenSigSwitchedByIgnition" SG_ 1426 KY_Schluesselposition_8 0;
BA_ "GenSigSendType" SG_ 1426 KY_Schluesselposition_9 3;
BA_ "GenSigSwitchedByIgnition" SG_ 1426 KY_Schluesselposition_9 0;
BA_ "GenSigSendType" SG_ 1426 KY_Startknopf_Bel 3;
BA_ "GenSigSwitchedByIgnition" SG_ 1426 KY_Startknopf_Bel 0;
BA_ "GenSigSendType" SG_ 1426 KY_StartStopp_Info 3;
BA_ "GenSigSwitchedByIgnition" SG_ 1426 KY_StartStopp_Info 0;
BA_ "GenSigSendType" SG_ 960 BCM_Ausparken_Betrieb 3;
BA_ "GenSigSwitchedByIgnition" SG_ 960 BCM_Ausparken_Betrieb 0;
BA_ "GenSigSendType" SG_ 960 BCM_Remotestart_Betrieb 3;
BA_ "GenSigSwitchedByIgnition" SG_ 960 BCM_Remotestart_Betrieb 0;
BA_ "GenSigSendType" SG_ 960 BCM_Remotestart_KL15_Anf 3;
BA_ "GenSigSwitchedByIgnition" SG_ 960 BCM_Remotestart_KL15_Anf 0;
BA_ "GenSigSendType" SG_ 960 BCM_Remotestart_MO_Start 3;
BA_ "GenSigSwitchedByIgnition" SG_ 960 BCM_Remotestart_MO_Start 0;
BA_ "GenSigSendType" SG_ 960 Klemmen_Status_01_BZ 0;
BA_ "GenSigFuncType" SG_ 960 Klemmen_Status_01_BZ 1;
BA_ "GenSigSwitchedByIgnition" SG_ 960 Klemmen_Status_01_BZ 0;
BA_ "GenSigSendType" SG_ 960 Klemmen_Status_01_CRC 0;
BA_ "GenSigFuncType" SG_ 960 Klemmen_Status_01_CRC 2;
BA_ "GenSigSwitchedByIgnition" SG_ 960 Klemmen_Status_01_CRC 0;
BA_ "GenSigSendType" SG_ 960 KST_Fahrerhinweis_1 3;
BA_ "GenSigSwitchedByIgnition" SG_ 960 KST_Fahrerhinweis_1 0;
BA_ "GenSigSendType" SG_ 960 KST_Fahrerhinweis_2 3;
BA_ "GenSigSwitchedByIgnition" SG_ 960 KST_Fahrerhinweis_2 0;
BA_ "GenSigSendType" SG_ 960 KST_Fahrerhinweis_4 3;
BA_ "GenSigSwitchedByIgnition" SG_ 960 KST_Fahrerhinweis_4 0;
BA_ "GenSigSendType" SG_ 960 KST_Fahrerhinweis_5 3;
BA_ "GenSigSwitchedByIgnition" SG_ 960 KST_Fahrerhinweis_5 0;
BA_ "GenSigSendType" SG_ 960 KST_Fahrerhinweis_6 3;
BA_ "GenSigSwitchedByIgnition" SG_ 960 KST_Fahrerhinweis_6 0;
BA_ "GenSigSendType" SG_ 960 KST_Warn_P1_ZST_def 3;
BA_ "GenSigSwitchedByIgnition" SG_ 960 KST_Warn_P1_ZST_def 0;
BA_ "GenSigSendType" SG_ 960 KST_Warn_P2_ZST_def 3;
BA_ "GenSigSwitchedByIgnition" SG_ 960 KST_Warn_P2_ZST_def 0;
BA_ "GenSigSendType" SG_ 960 RSt_Fahrerhinweise 3;
BA_ "GenSigSwitchedByIgnition" SG_ 960 RSt_Fahrerhinweise 0;
BA_ "GenSigSendType" SG_ 960 ZAS_Kl_15 3;
BA_ "NWM-WakeupAllowed" SG_ 960 ZAS_Kl_15 1;
BA_ "GenSigFuncType" SG_ 960 ZAS_Kl_15 6;
BA_ "GenSigSwitchedByIgnition" SG_ 960 ZAS_Kl_15 0;
BA_ "GenSigSendType" SG_ 960 ZAS_Kl_50_Startanforderung 3;
BA_ "GenSigSwitchedByIgnition" SG_ 960 ZAS_Kl_50_Startanforderung 0;
BA_ "GenSigSendType" SG_ 960 ZAS_Kl_Infotainment 3;
BA_ "GenSigSwitchedByIgnition" SG_ 960 ZAS_Kl_Infotainment 0;
BA_ "GenSigSendType" SG_ 960 ZAS_Kl_S 3;
BA_ "GenSigSwitchedByIgnition" SG_ 960 ZAS_Kl_S 0;
BA_ "GenSigSendType" SG_ 960 ZAS_Kl_X 3;
BA_ "GenSigSwitchedByIgnition" SG_ 960 ZAS_Kl_X 0;
BA_ "GenSigSendType" SG_ 2463978753 Klemmen_Status_02_BZ 0;
BA_ "GenSigFuncType" SG_ 2463978753 Klemmen_Status_02_BZ 1;
BA_ "GenSigSwitchedByIgnition" SG_ 2463978753 Klemmen_Status_02_BZ 0;
BA_ "GenSigSendType" SG_ 2463978753 Klemmen_Status_02_CRC 0;
BA_ "GenSigFuncType" SG_ 2463978753 Klemmen_Status_02_CRC 2;
BA_ "GenSigSwitchedByIgnition" SG_ 2463978753 Klemmen_Status_02_CRC 0;
BA_ "GenSigSendType" SG_ 2463978753 KST_ComfortReadyStatus 4;
BA_ "GenSigSwitchedByIgnition" SG_ 2463978753 KST_ComfortReadyStatus 0;
BA_ "GenSigSendType" SG_ 2463978753 KST_Freigabe_Zustand 4;
BA_ "GenSigSwitchedByIgnition" SG_ 2463978753 KST_Freigabe_Zustand 0;
BA_ "GenSigSendType" SG_ 2463978753 KST_Sonderzustand_Anforderung 4;
BA_ "GenSigSwitchedByIgnition" SG_ 2463978753 KST_Sonderzustand_Anforderung 0;
BA_ "Fehlerwert" SG_ 2463978753 KST_Sonderzustand_Anforderung 31;
BA_ "GenSigSendType" SG_ 2463978753 KST_Sonderzustand_Status 4;
BA_ "GenSigSwitchedByIgnition" SG_ 2463978753 KST_Sonderzustand_Status 0;
BA_ "Fehlerwert" SG_ 2463978753 KST_Sonderzustand_Status 3;
BA_ "GenSigSendType" SG_ 2463978753 KST_WFS_Fahrfreigabe_Anforderung 4;
BA_ "GenSigSwitchedByIgnition" SG_ 2463978753 KST_WFS_Fahrfreigabe_Anforderung 0;
BA_ "GenSigSendType" SG_ 1420 Klemmen_Steuerung_01_BZ 0;
BA_ "GenSigFuncType" SG_ 1420 Klemmen_Steuerung_01_BZ 1;
BA_ "GenSigSwitchedByIgnition" SG_ 1420 Klemmen_Steuerung_01_BZ 0;
BA_ "GenSigSendType" SG_ 1420 Klemmen_Steuerung_01_CRC 0;
BA_ "GenSigFuncType" SG_ 1420 Klemmen_Steuerung_01_CRC 2;
BA_ "GenSigSwitchedByIgnition" SG_ 1420 Klemmen_Steuerung_01_CRC 0;
BA_ "GenSigSendType" SG_ 1420 KST_Anf_Klemme_15 4;
BA_ "GenSigSwitchedByIgnition" SG_ 1420 KST_Anf_Klemme_15 0;
BA_ "GenSigSendType" SG_ 1420 KST_Anf_Klemme_50 4;
BA_ "GenSigSwitchedByIgnition" SG_ 1420 KST_Anf_Klemme_50 0;
BA_ "GenSigSendType" SG_ 1420 KST_Anf_Klemme_S 3;
BA_ "GenSigSwitchedByIgnition" SG_ 1420 KST_Anf_Klemme_S 0;
BA_ "GenSigSendType" SG_ 1420 KST_Anf_Klemmenfreigabe_ELV 3;
BA_ "GenSigSwitchedByIgnition" SG_ 1420 KST_Anf_Klemmenfreigabe_ELV 0;
BA_ "GenSigSendType" SG_ 1420 KST_Anf_Klemmenfreigabe_WFS 3;
BA_ "GenSigSwitchedByIgnition" SG_ 1420 KST_Anf_Klemmenfreigabe_WFS 0;
BA_ "GenSigSendType" SG_ 1420 KST_Anf_ZV_Verriegelung 3;
BA_ "GenSigSwitchedByIgnition" SG_ 1420 KST_Anf_ZV_Verriegelung 0;
BA_ "GenSigSendType" SG_ 1420 KST_Anzeige_Klemmenzustand 3;
BA_ "GenSigSwitchedByIgnition" SG_ 1420 KST_Anzeige_Klemmenzustand 0;
BA_ "GenSigSendType" SG_ 1420 KST_aut_Abschaltung_Zuendung 4;
BA_ "GenSigSwitchedByIgnition" SG_ 1420 KST_aut_Abschaltung_Zuendung 0;
BA_ "GenSigSendType" SG_ 1420 KST_Txt_Komfortabschaltung 3;
BA_ "GenSigSwitchedByIgnition" SG_ 1420 KST_Txt_Komfortabschaltung 0;
BA_ "GenSigSendType" SG_ 1420 KST_Txt_P_Gang 3;
BA_ "GenSigSwitchedByIgnition" SG_ 1420 KST_Txt_P_Gang 0;
BA_ "GenSigSendType" SG_ 1420 KST_Txt_Panikabschaltung 3;
BA_ "GenSigSwitchedByIgnition" SG_ 1420 KST_Txt_Panikabschaltung 0;
BA_ "GenSigSendType" SG_ 1420 KST_Txt_Werkstatt 3;
BA_ "GenSigSwitchedByIgnition" SG_ 1420 KST_Txt_Werkstatt 0;
BA_ "GenSigSendType" SG_ 1420 KST_Unterdr_Zuendungsmeldung 3;
BA_ "GenSigSwitchedByIgnition" SG_ 1420 KST_Unterdr_Zuendungsmeldung 0;
BA_ "GenSigSendType" SG_ 1420 KST_ZAT_betaetigt 3;
BA_ "GenSigSwitchedByIgnition" SG_ 1420 KST_ZAT_betaetigt 0;
BA_ "GenSigSendType" SG_ 1420 KST_Zuendungswarnung 4;
BA_ "GenSigSwitchedByIgnition" SG_ 1420 KST_Zuendungswarnung 0;
BA_ "GenSigSendType" SG_ 1420 Relais_VoKo_angesteuert 3;
BA_ "GenSigSwitchedByIgnition" SG_ 1420 Relais_VoKo_angesteuert 0;
BA_ "GenSigSendType" SG_ 1420 RSt_Anforderung_HMS 3;
BA_ "GenSigSwitchedByIgnition" SG_ 1420 RSt_Anforderung_HMS 0;
BA_ "GenSigSendType" SG_ 1646 KL_Anf_AussenspiegelHzg 3;
BA_ "GenSigSwitchedByIgnition" SG_ 1646 KL_Anf_AussenspiegelHzg 0;
BA_ "GenSigSendType" SG_ 1646 KL_BCmE_Livetip_Freigabe 3;
BA_ "GenSigSwitchedByIgnition" SG_ 1646 KL_BCmE_Livetip_Freigabe 0;
BA_ "GenSigSendType" SG_ 1646 KL_ErwVK_Anf 3;
BA_ "GenSigSwitchedByIgnition" SG_ 1646 KL_ErwVK_Anf 0;
BA_ "GenSigSendType" SG_ 1646 KL_FSH_Automatikbetrieb 3;
BA_ "GenSigSwitchedByIgnition" SG_ 1646 KL_FSH_Automatikbetrieb 0;
BA_ "GenSigSendType" SG_ 1646 KL_Geblaese_Fond_Status 0;
BA_ "GenSigStartValue" SG_ 1646 KL_Geblaese_Fond_Status 14;
BA_ "GenSigSwitchedByIgnition" SG_ 1646 KL_Geblaese_Fond_Status 0;
BA_ "Fehlerwert" SG_ 1646 KL_Geblaese_Fond_Status 15;
BA_ "GenSigSendType" SG_ 1646 KL_Geblaese_Status 0;
BA_ "GenSigStartValue" SG_ 1646 KL_Geblaese_Status 14;
BA_ "GenSigSwitchedByIgnition" SG_ 1646 KL_Geblaese_Status 0;
BA_ "Fehlerwert" SG_ 1646 KL_Geblaese_Status 15;
BA_ "GenSigSendType" SG_ 1646 KL_Heizkreisventilstellung 0;
BA_ "GenSigSwitchedByIgnition" SG_ 1646 KL_Heizkreisventilstellung 0;
BA_ "Fehlerwert" SG_ 1646 KL_Heizkreisventilstellung 3;
BA_ "GenSigSendType" SG_ 1646 KL_I_Geblaese_Fond 3;
BA_ "GenSigSwitchedByIgnition" SG_ 1646 KL_I_Geblaese_Fond 0;
BA_ "Fehlerwert" SG_ 1646 KL_I_Geblaese_Fond 255;
BA_ "GenSigSendType" SG_ 1646 KL_Innen_Temp 0;
BA_ "GenSigStartValue" SG_ 1646 KL_Innen_Temp 254;
BA_ "GenSigSwitchedByIgnition" SG_ 1646 KL_Innen_Temp 0;
BA_ "Fehlerwert" SG_ 1646 KL_Innen_Temp 255;
BA_ "GenSigSendType" SG_ 1646 KL_Kompressorkupplung 3;
BA_ "GenSigSwitchedByIgnition" SG_ 1646 KL_Kompressorkupplung 0;
BA_ "GenSigSendType" SG_ 1646 KL_Magnetventil 3;
BA_ "GenSigSwitchedByIgnition" SG_ 1646 KL_Magnetventil 0;
BA_ "GenSigSendType" SG_ 1646 KL_Restwaerme_aktiv 3;
BA_ "GenSigSwitchedByIgnition" SG_ 1646 KL_Restwaerme_aktiv 0;
BA_ "GenSigSendType" SG_ 1646 KL_SH_Soll_hl 3;
BA_ "GenSigSwitchedByIgnition" SG_ 1646 KL_SH_Soll_hl 0;
BA_ "GenSigSendType" SG_ 1646 KL_SH_Soll_hr 3;
BA_ "GenSigSwitchedByIgnition" SG_ 1646 KL_SH_Soll_hr 0;
BA_ "GenSigSendType" SG_ 1646 KL_SIH_LEH_Verteilung_VL 3;
BA_ "GenSigSwitchedByIgnition" SG_ 1646 KL_SIH_LEH_Verteilung_VL 0;
BA_ "GenSigSendType" SG_ 1646 KL_SIH_LEH_Verteilung_VR 3;
BA_ "GenSigSwitchedByIgnition" SG_ 1646 KL_SIH_LEH_Verteilung_VR 0;
BA_ "GenSigSendType" SG_ 1646 KL_SIH_LEL_Verteilung_VL 3;
BA_ "GenSigSwitchedByIgnition" SG_ 1646 KL_SIH_LEL_Verteilung_VL 0;
BA_ "GenSigSendType" SG_ 1646 KL_SIH_LEL_Verteilung_VR 3;
BA_ "GenSigSwitchedByIgnition" SG_ 1646 KL_SIH_LEL_Verteilung_VR 0;
BA_ "GenSigSendType" SG_ 1646 KL_Solarluefter_aktiv 3;
BA_ "GenSigSwitchedByIgnition" SG_ 1646 KL_Solarluefter_aktiv 0;
BA_ "GenSigSendType" SG_ 1646 KL_STH_aktiv 3;
BA_ "GenSigSwitchedByIgnition" SG_ 1646 KL_STH_aktiv 0;
BA_ "GenSigSendType" SG_ 1646 KL_STH_Ansteuerung 3;
BA_ "GenSigSwitchedByIgnition" SG_ 1646 KL_STH_Ansteuerung 0;
BA_ "GenSigSendType" SG_ 1646 KL_STH_Betriebsdauer 3;
BA_ "GenSigSwitchedByIgnition" SG_ 1646 KL_STH_Betriebsdauer 0;
BA_ "GenSigSendType" SG_ 1646 KL_STL_aktiv 3;
BA_ "GenSigSwitchedByIgnition" SG_ 1646 KL_STL_aktiv 0;
BA_ "GenSigSendType" SG_ 1646 KL_Umluft_Taste 3;
BA_ "GenSigSwitchedByIgnition" SG_ 1646 KL_Umluft_Taste 0;
BA_ "GenSigSendType" SG_ 1646 KL_WaPu 3;
BA_ "GenSigSwitchedByIgnition" SG_ 1646 KL_WaPu 0;
BA_ "GenSigSendType" SG_ 949 KL_AC_Schalter 0;
BA_ "GenSigSwitchedByIgnition" SG_ 949 KL_AC_Schalter 0;
BA_ "GenSigSendType" SG_ 949 KL_AirCleaner_aktiv 0;
BA_ "GenSigSwitchedByIgnition" SG_ 949 KL_AirCleaner_aktiv 0;
BA_ "GenSigSendType" SG_ 949 KL_Anf_KL 0;
BA_ "GenSigSwitchedByIgnition" SG_ 949 KL_Anf_KL 0;
BA_ "Fehlerwert" SG_ 949 KL_Anf_KL 255;
BA_ "GenSigSendType" SG_ 949 KL_Anf_KV 0;
BA_ "GenSigStartValue" SG_ 949 KL_Anf_KV 126;
BA_ "GenSigSwitchedByIgnition" SG_ 949 KL_Anf_KV 0;
BA_ "GenSigSendType" SG_ 949 KL_Ausstattung_Klima 0;
BA_ "GenSigSwitchedByIgnition" SG_ 949 KL_Ausstattung_Klima 0;
BA_ "GenSigSendType" SG_ 949 KL_Charisma_FahrPr 0;
BA_ "GenSigSwitchedByIgnition" SG_ 949 KL_Charisma_FahrPr 0;
BA_ "GenSigSendType" SG_ 949 KL_Charisma_Status 0;
BA_ "GenSigSwitchedByIgnition" SG_ 949 KL_Charisma_Status 0;
BA_ "GenSigSendType" SG_ 949 KL_Drehz_Anh 0;
BA_ "GenSigSwitchedByIgnition" SG_ 949 KL_Drehz_Anh 0;
BA_ "GenSigSendType" SG_ 949 KL_el_Zuheizer_Stufe 0;
BA_ "GenSigSwitchedByIgnition" SG_ 949 KL_el_Zuheizer_Stufe 0;
BA_ "GenSigSendType" SG_ 949 KL_Freilauf_Info 0;
BA_ "GenSigSwitchedByIgnition" SG_ 949 KL_Freilauf_Info 0;
BA_ "GenSigSendType" SG_ 949 KL_Komp_Moment_alt 0;
BA_ "GenSigFuncType" SG_ 949 KL_Komp_Moment_alt 5;
BA_ "GenSigSwitchedByIgnition" SG_ 949 KL_Komp_Moment_alt 0;
BA_ "GenSigSendType" SG_ 949 KL_Kompressorkupplung_linear 0;
BA_ "GenSigStartValue" SG_ 949 KL_Kompressorkupplung_linear 254;
BA_ "GenSigSwitchedByIgnition" SG_ 949 KL_Kompressorkupplung_linear 0;
BA_ "GenSigSendType" SG_ 949 KL_Last_Kompr 0;
BA_ "GenSigSwitchedByIgnition" SG_ 949 KL_Last_Kompr 0;
BA_ "Fehlerwert" SG_ 949 KL_Last_Kompr 255;
BA_ "GenSigSendType" SG_ 949 KL_nachtr_Stopp_Anf 0;
BA_ "GenSigSwitchedByIgnition" SG_ 949 KL_nachtr_Stopp_Anf 0;
BA_ "GenSigSendType" SG_ 949 KL_Spannungs_Anf 0;
BA_ "GenSigSwitchedByIgnition" SG_ 949 KL_Spannungs_Anf 0;
BA_ "GenSigSendType" SG_ 949 KL_StartStopp_Info 0;
BA_ "GenSigSwitchedByIgnition" SG_ 949 KL_StartStopp_Info 0;
BA_ "GenSigSendType" SG_ 949 KL_T_Charge 0;
BA_ "GenSigSwitchedByIgnition" SG_ 949 KL_T_Charge 0;
BA_ "GenSigSendType" SG_ 949 KL_Thermomanagement 0;
BA_ "GenSigSwitchedByIgnition" SG_ 949 KL_Thermomanagement 0;
BA_ "GenSigSendType" SG_ 949 KL_Variante_Standheizung 0;
BA_ "GenSigSwitchedByIgnition" SG_ 949 KL_Variante_Standheizung 0;
BA_ "GenSigSendType" SG_ 949 KL_Vorwarn_Komp_ein 0;
BA_ "GenSigSwitchedByIgnition" SG_ 949 KL_Vorwarn_Komp_ein 0;
BA_ "GenSigSendType" SG_ 949 KL_Vorwarn_Zuheizer_ein 0;
BA_ "GenSigSwitchedByIgnition" SG_ 949 KL_Vorwarn_Zuheizer_ein 0;
BA_ "GenSigSendType" SG_ 949 KL_Zustand 0;
BA_ "GenSigSwitchedByIgnition" SG_ 949 KL_Zustand 0;
BA_ "GenSigActiveRepetitions" SG_ 1640 FSH_Taster 5;
BA_ "GenSigSendType" SG_ 1640 FSH_Taster 4;
BA_ "GenSigSwitchedByIgnition" SG_ 1640 FSH_Taster 0;
BA_ "GenSigActiveRepetitions" SG_ 1640 HSH_Taster 5;
BA_ "GenSigSendType" SG_ 1640 HSH_Taster 4;
BA_ "GenSigSwitchedByIgnition" SG_ 1640 HSH_Taster 0;
BA_ "GenSigSendType" SG_ 1640 KL_Beschlagsgefahr 3;
BA_ "GenSigSwitchedByIgnition" SG_ 1640 KL_Beschlagsgefahr 0;
BA_ "GenSigSendType" SG_ 1640 KL_Geblspng_Fond_Soll 0;
BA_ "GenSigSwitchedByIgnition" SG_ 1640 KL_Geblspng_Fond_Soll 0;
BA_ "Fehlerwert" SG_ 1640 KL_Geblspng_Fond_Soll 255;
BA_ "GenSigSendType" SG_ 1640 KL_Geblspng_Soll 0;
BA_ "GenSigSwitchedByIgnition" SG_ 1640 KL_Geblspng_Soll 0;
BA_ "Fehlerwert" SG_ 1640 KL_Geblspng_Soll 255;
BA_ "GenSigSendType" SG_ 1640 KL_I_Geblaese 0;
BA_ "GenSigSwitchedByIgnition" SG_ 1640 KL_I_Geblaese 0;
BA_ "Fehlerwert" SG_ 1640 KL_I_Geblaese 255;
BA_ "GenSigSendType" SG_ 1640 KL_Kompressorstrom_soll 0;
BA_ "GenSigStartValue" SG_ 1640 KL_Kompressorstrom_soll 1022;
BA_ "GenSigSwitchedByIgnition" SG_ 1640 KL_Kompressorstrom_soll 0;
BA_ "Fehlerwert" SG_ 1640 KL_Kompressorstrom_soll 1023;
BA_ "GenSigSendType" SG_ 1640 KL_LRH_Stufe 3;
BA_ "GenSigStartValue" SG_ 1640 KL_LRH_Stufe 1;
BA_ "GenSigSwitchedByIgnition" SG_ 1640 KL_LRH_Stufe 0;
BA_ "GenSigActiveRepetitions" SG_ 1640 KL_LRH_Taster 5;
BA_ "GenSigSendType" SG_ 1640 KL_LRH_Taster 4;
BA_ "GenSigSwitchedByIgnition" SG_ 1640 KL_LRH_Taster 0;
BA_ "GenSigSendType" SG_ 1640 KL_PTC_Verbauinfo 0;
BA_ "GenSigSwitchedByIgnition" SG_ 1640 KL_PTC_Verbauinfo 0;
BA_ "GenSigSendType" SG_ 1640 KL_SIH_Soll_li 3;
BA_ "GenSigSwitchedByIgnition" SG_ 1640 KL_SIH_Soll_li 0;
BA_ "GenSigSendType" SG_ 1640 KL_SIH_Soll_re 3;
BA_ "GenSigSwitchedByIgnition" SG_ 1640 KL_SIH_Soll_re 0;
BA_ "GenSigSendType" SG_ 1640 KL_SIL_Soll_li 3;
BA_ "GenSigSwitchedByIgnition" SG_ 1640 KL_SIL_Soll_li 0;
BA_ "GenSigSendType" SG_ 1640 KL_SIL_Soll_re 3;
BA_ "GenSigSwitchedByIgnition" SG_ 1640 KL_SIL_Soll_re 0;
BA_ "GenSigSendType" SG_ 1640 KL_Umluftklappe_Status 0;
BA_ "GenSigStartValue" SG_ 1640 KL_Umluftklappe_Status 14;
BA_ "GenSigSwitchedByIgnition" SG_ 1640 KL_Umluftklappe_Status 0;
BA_ "Fehlerwert" SG_ 1640 KL_Umluftklappe_Status 15;
BA_ "GenSigSendType" SG_ 1640 KL_Zuheizer_Freigabe 3;
BA_ "GenSigSwitchedByIgnition" SG_ 1640 KL_Zuheizer_Freigabe 0;
BA_ "GenSigSendType" SG_ 1640 KRH_Soll_li 3;
BA_ "GenSigSwitchedByIgnition" SG_ 1640 KRH_Soll_li 0;
BA_ "GenSigSendType" SG_ 1640 KRH_Soll_re 3;
BA_ "GenSigSwitchedByIgnition" SG_ 1640 KRH_Soll_re 0;
BA_ "GenSigSendType" SG_ 2527679635 FSH_Status 0;
BA_ "GenSigSwitchedByIgnition" SG_ 2527679635 FSH_Status 0;
BA_ "Fehlerwert" SG_ 2527679635 FSH_Status 3;
BA_ "GenSigSendType" SG_ 2527679635 HSH_Relais_Anf 3;
BA_ "GenSigSwitchedByIgnition" SG_ 2527679635 HSH_Relais_Anf 0;
BA_ "GenSigSendType" SG_ 2527679635 KL_AL_HL_Anf 3;
BA_ "GenSigSwitchedByIgnition" SG_ 2527679635 KL_AL_HL_Anf 0;
BA_ "GenSigSendType" SG_ 2527679635 KL_AL_HR_Anf 3;
BA_ "GenSigSwitchedByIgnition" SG_ 2527679635 KL_AL_HR_Anf 0;
BA_ "GenSigSendType" SG_ 2527679635 KL_AL_VL_Anf 3;
BA_ "GenSigSwitchedByIgnition" SG_ 2527679635 KL_AL_VL_Anf 0;
BA_ "GenSigSendType" SG_ 2527679635 KL_AL_VR_Anf 3;
BA_ "GenSigSwitchedByIgnition" SG_ 2527679635 KL_AL_VR_Anf 0;
BA_ "GenSigSendType" SG_ 2527679635 KL_Defrost_LED 3;
BA_ "GenSigSwitchedByIgnition" SG_ 2527679635 KL_Defrost_LED 0;
BA_ "GenSigSendType" SG_ 2527679635 KL_FSH_LED 3;
BA_ "GenSigSwitchedByIgnition" SG_ 2527679635 KL_FSH_LED 0;
BA_ "GenSigSendType" SG_ 2527679635 KL_FSH_Soll 3;
BA_ "GenSigSwitchedByIgnition" SG_ 2527679635 KL_FSH_Soll 0;
BA_ "GenSigSendType" SG_ 2527679635 KL_Heizstufe_LSH 3;
BA_ "GenSigSwitchedByIgnition" SG_ 2527679635 KL_Heizstufe_LSH 0;
BA_ "Fehlerwert" SG_ 2527679635 KL_Heizstufe_LSH 15;
BA_ "GenSigSendType" SG_ 2527679635 KL_HSH_LED 3;
BA_ "GenSigSwitchedByIgnition" SG_ 2527679635 KL_HSH_LED 0;
BA_ "GenSigSendType" SG_ 2527679635 KL_HSH_Soll 3;
BA_ "GenSigSwitchedByIgnition" SG_ 2527679635 KL_HSH_Soll 0;
BA_ "GenSigSendType" SG_ 2527679635 KL_HUP_aktiv 3;
BA_ "GenSigSwitchedByIgnition" SG_ 2527679635 KL_HUP_aktiv 0;
BA_ "GenSigSendType" SG_ 2527679635 KL_Klappe_Status 3;
BA_ "GenSigSwitchedByIgnition" SG_ 2527679635 KL_Klappe_Status 0;
BA_ "GenSigSendType" SG_ 2527679635 KL_LRH_PWM 3;
BA_ "GenSigSwitchedByIgnition" SG_ 2527679635 KL_LRH_PWM 0;
BA_ "GenSigSendType" SG_ 2527679635 KL_LRH_Soll 3;
BA_ "GenSigSwitchedByIgnition" SG_ 2527679635 KL_LRH_Soll 0;
BA_ "GenSigSendType" SG_ 2527679635 KL_LSH_Ansteuerung 3;
BA_ "GenSigSwitchedByIgnition" SG_ 2527679635 KL_LSH_Ansteuerung 0;
BA_ "GenSigSendType" SG_ 2527679635 KL_LSH_Betriebsdauer 3;
BA_ "GenSigSwitchedByIgnition" SG_ 2527679635 KL_LSH_Betriebsdauer 0;
BA_ "GenSigSendType" SG_ 2527679635 KL_LSH_DBetr_Bestaet 3;
BA_ "GenSigSwitchedByIgnition" SG_ 2527679635 KL_LSH_DBetr_Bestaet 0;
BA_ "GenSigSendType" SG_ 2527679635 KL_LSH_DBetr_Ein 3;
BA_ "GenSigSwitchedByIgnition" SG_ 2527679635 KL_LSH_DBetr_Ein 0;
BA_ "GenSigSendType" SG_ 2527679635 KL_Temp_ZH_Soll 3;
BA_ "GenSigSwitchedByIgnition" SG_ 2527679635 KL_Temp_ZH_Soll 0;
BA_ "Fehlerwert" SG_ 2527679635 KL_Temp_ZH_Soll 255;
BA_ "GenSigSendType" SG_ 2527679635 KL_VoKo_LED 3;
BA_ "GenSigSwitchedByIgnition" SG_ 2527679635 KL_VoKo_LED 0;
BA_ "GenSigSendType" SG_ 2527679635 KL_Voko_Status 3;
BA_ "GenSigStartValue" SG_ 2527679635 KL_Voko_Status 14;
BA_ "GenSigSwitchedByIgnition" SG_ 2527679635 KL_Voko_Status 0;
BA_ "Fehlerwert" SG_ 2527679635 KL_Voko_Status 15;
BA_ "GenSigSendType" SG_ 2527679635 KL_ZR_Anforderung 3;
BA_ "GenSigSwitchedByIgnition" SG_ 2527679635 KL_ZR_Anforderung 0;
BA_ "GenSigSendType" SG_ 2527679635 SIH_Stufe_LED_li 3;
BA_ "GenSigSwitchedByIgnition" SG_ 2527679635 SIH_Stufe_LED_li 0;
BA_ "GenSigSendType" SG_ 2527679635 SIH_Stufe_LED_re 3;
BA_ "GenSigSwitchedByIgnition" SG_ 2527679635 SIH_Stufe_LED_re 0;
BA_ "GenSigSendType" SG_ 1505 BCM1_Aussen_Temp_ungef 0;
BA_ "GenSigStartValue" SG_ 1505 BCM1_Aussen_Temp_ungef 254;
BA_ "GenSigSwitchedByIgnition" SG_ 1505 BCM1_Aussen_Temp_ungef 0;
BA_ "Fehlerwert" SG_ 1505 BCM1_Aussen_Temp_ungef 255;
BA_ "GenSigSendType" SG_ 1505 BCM1_FStatus_Aussentemp_ungef 0;
BA_ "GenSigStartValue" SG_ 1505 BCM1_FStatus_Aussentemp_ungef 1;
BA_ "GenSigSwitchedByIgnition" SG_ 1505 BCM1_FStatus_Aussentemp_ungef 0;
BA_ "GenSigSendType" SG_ 1505 BCM1_Kompressorstrom_ist 0;
BA_ "GenSigStartValue" SG_ 1505 BCM1_Kompressorstrom_ist 254;
BA_ "GenSigSwitchedByIgnition" SG_ 1505 BCM1_Kompressorstrom_ist 0;
BA_ "Fehlerwert" SG_ 1505 BCM1_Kompressorstrom_ist 255;
BA_ "GenSigSendType" SG_ 1505 BCM1_OBD_FStatus_ATemp 0;
BA_ "GenSigSwitchedByIgnition" SG_ 1505 BCM1_OBD_FStatus_ATemp 0;
BA_ "GenSigSendType" SG_ 1505 BCM1_PTC_stufig_Status 0;
BA_ "GenSigStartValue" SG_ 1505 BCM1_PTC_stufig_Status 6;
BA_ "GenSigSwitchedByIgnition" SG_ 1505 BCM1_PTC_stufig_Status 0;
BA_ "Fehlerwert" SG_ 1505 BCM1_PTC_stufig_Status 7;
BA_ "GenSigSendType" SG_ 1505 BCM_Heizungsabsperrventil_Status 0;
BA_ "GenSigStartValue" SG_ 1505 BCM_Heizungsabsperrventil_Status 2;
BA_ "GenSigSwitchedByIgnition" SG_ 1505 BCM_Heizungsabsperrventil_Status 0;
BA_ "Fehlerwert" SG_ 1505 BCM_Heizungsabsperrventil_Status 3;
BA_ "GenSigSendType" SG_ 1505 BCM_Heizungspumpe_Status 0;
BA_ "GenSigStartValue" SG_ 1505 BCM_Heizungspumpe_Status 2;
BA_ "GenSigSwitchedByIgnition" SG_ 1505 BCM_Heizungspumpe_Status 0;
BA_ "Fehlerwert" SG_ 1505 BCM_Heizungspumpe_Status 3;
BA_ "GenSigSendType" SG_ 1505 BCM_Kompressorkupplung_Status 0;
BA_ "GenSigStartValue" SG_ 1505 BCM_Kompressorkupplung_Status 2;
BA_ "GenSigSwitchedByIgnition" SG_ 1505 BCM_Kompressorkupplung_Status 0;
BA_ "Fehlerwert" SG_ 1505 BCM_Kompressorkupplung_Status 3;
BA_ "GenSigSendType" SG_ 2549088305 ELV_Abschaltstufe 0;
BA_ "GenSigSwitchedByIgnition" SG_ 2549088305 ELV_Abschaltstufe 0;
BA_ "GenSigSendType" SG_ 2549088305 ELV_KD_Fehler 0;
BA_ "GenSigSwitchedByIgnition" SG_ 2549088305 ELV_KD_Fehler 0;
BA_ "GenSigSendType" SG_ 2549088305 ELV_KompSchutz 0;
BA_ "GenSigSwitchedByIgnition" SG_ 2549088305 ELV_KompSchutz 0;
BA_ "GenSigSendType" SG_ 2549088305 ELV_Nachlauftyp 0;
BA_ "GenSigStartValue" SG_ 2549088305 ELV_Nachlauftyp 2;
BA_ "GenSigSwitchedByIgnition" SG_ 2549088305 ELV_Nachlauftyp 0;
BA_ "GenSigSendType" SG_ 2549088305 ELV_Transport_Mode 0;
BA_ "GenSigSwitchedByIgnition" SG_ 2549088305 ELV_Transport_Mode 0;
BA_ "GenSigSendType" SG_ 2549088305 KN_ELV_BusKnockOut 0;
BA_ "GenSigSendType" SG_ 2549088305 KN_ELV_BusKnockOutTimer 0;
BA_ "GenSigSendType" SG_ 2549088305 KN_ELV_DiagPfad 0;
BA_ "GenSigSwitchedByIgnition" SG_ 2549088305 KN_ELV_DiagPfad 0;
BA_ "GenSigSendType" SG_ 2549088305 KN_ELV_ECUKnockOut 0;
BA_ "GenSigSendType" SG_ 2549088305 KN_ELV_ECUKnockOutTimer 0;
BA_ "GenSigSendType" SG_ 2549088305 NM_ELV_Lokalaktiv 0;
BA_ "GenSigSwitchedByIgnition" SG_ 2549088305 NM_ELV_Lokalaktiv 0;
BA_ "GenSigSendType" SG_ 2549088305 NM_ELV_Subsystemaktiv 0;
BA_ "GenSigSwitchedByIgnition" SG_ 2549088305 NM_ELV_Subsystemaktiv 0;
BA_ "GenSigSendType" SG_ 2549088305 NM_ELV_Wakeup 0;
BA_ "NWM-WakeupAllowed" SG_ 2549088305 NM_ELV_Wakeup 1;
BA_ "GenSigSwitchedByIgnition" SG_ 2549088305 NM_ELV_Wakeup 0;
BA_ "GenSigSendType" SG_ 2549088272 Gateway_Abschaltstufe 0;
BA_ "GenSigSwitchedByIgnition" SG_ 2549088272 Gateway_Abschaltstufe 0;
BA_ "GenSigSendType" SG_ 2549088272 Gateway_KompSchutz 0;
BA_ "GenSigSwitchedByIgnition" SG_ 2549088272 Gateway_KompSchutz 0;
BA_ "GenSigSendType" SG_ 2549088272 Gateway_Nachlauftyp 0;
BA_ "GenSigStartValue" SG_ 2549088272 Gateway_Nachlauftyp 2;
BA_ "GenSigSwitchedByIgnition" SG_ 2549088272 Gateway_Nachlauftyp 0;
BA_ "GenSigSendType" SG_ 2549088272 Gateway_Transport_Mode 0;
BA_ "GenSigSwitchedByIgnition" SG_ 2549088272 Gateway_Transport_Mode 0;
BA_ "GenSigSendType" SG_ 2549088272 GW_KD_Fehler 0;
BA_ "GenSigSendType" SG_ 2549088272 KN_GW_DiagPfad 0;
BA_ "GenSigSwitchedByIgnition" SG_ 2549088272 KN_GW_DiagPfad 0;
BA_ "GenSigSendType" SG_ 2549088272 NM_Gateway_Wakeup 0;
BA_ "NWM-WakeupAllowed" SG_ 2549088272 NM_Gateway_Wakeup 1;
BA_ "GenSigSwitchedByIgnition" SG_ 2549088272 NM_Gateway_Wakeup 0;
BA_ "GenSigSendType" SG_ 2549088283 HUD_Abschaltstufe 0;
BA_ "GenSigSendType" SG_ 2549088283 HUD_KD_Fehler 0;
BA_ "GenSigSwitchedByIgnition" SG_ 2549088283 HUD_KD_Fehler 0;
BA_ "GenSigSendType" SG_ 2549088283 HUD_KompSchutz 0;
BA_ "GenSigSwitchedByIgnition" SG_ 2549088283 HUD_KompSchutz 0;
BA_ "GenSigSendType" SG_ 2549088283 HUD_Nachlauftyp 0;
BA_ "GenSigStartValue" SG_ 2549088283 HUD_Nachlauftyp 2;
BA_ "GenSigSwitchedByIgnition" SG_ 2549088283 HUD_Nachlauftyp 0;
BA_ "GenSigSendType" SG_ 2549088283 HUD_Transport_Mode 0;
BA_ "GenSigSwitchedByIgnition" SG_ 2549088283 HUD_Transport_Mode 0;
BA_ "GenSigSendType" SG_ 2549088283 KN_HUD_BusKnockOut 0;
BA_ "GenSigSwitchedByIgnition" SG_ 2549088283 KN_HUD_BusKnockOut 0;
BA_ "GenSigSendType" SG_ 2549088283 KN_HUD_BusKnockOutTimer 0;
BA_ "GenSigSwitchedByIgnition" SG_ 2549088283 KN_HUD_BusKnockOutTimer 0;
BA_ "GenSigSendType" SG_ 2549088283 KN_HUD_DiagPfad 0;
BA_ "GenSigSwitchedByIgnition" SG_ 2549088283 KN_HUD_DiagPfad 0;
BA_ "GenSigSendType" SG_ 2549088283 KN_HUD_ECUKnockOut 0;
BA_ "GenSigSwitchedByIgnition" SG_ 2549088283 KN_HUD_ECUKnockOut 0;
BA_ "GenSigSendType" SG_ 2549088283 KN_HUD_ECUKnockOutTimer 0;
BA_ "GenSigSwitchedByIgnition" SG_ 2549088283 KN_HUD_ECUKnockOutTimer 0;
BA_ "GenSigSendType" SG_ 2549088283 NM_HUD_Lokalaktiv 0;
BA_ "GenSigSwitchedByIgnition" SG_ 2549088283 NM_HUD_Lokalaktiv 0;
BA_ "GenSigSendType" SG_ 2549088283 NM_HUD_Subsystemaktiv 0;
BA_ "GenSigSwitchedByIgnition" SG_ 2549088283 NM_HUD_Subsystemaktiv 0;
BA_ "GenSigSendType" SG_ 2549088283 NM_HUD_Wakeup 0;
BA_ "NWM-WakeupAllowed" SG_ 2549088283 NM_HUD_Wakeup 1;
BA_ "GenSigSwitchedByIgnition" SG_ 2549088283 NM_HUD_Wakeup 0;
BA_ "GenSigSendType" SG_ 2549088276 KBI_KD_Fehler 0;
BA_ "GenSigSwitchedByIgnition" SG_ 2549088276 KBI_KD_Fehler 0;
BA_ "GenSigSendType" SG_ 2549088276 KN_KBI_DiagPfad 0;
BA_ "GenSigSwitchedByIgnition" SG_ 2549088276 KN_KBI_DiagPfad 0;
BA_ "GenSigSendType" SG_ 2549088276 KN_Kombi_BusKnockOut 0;
BA_ "GenSigSwitchedByIgnition" SG_ 2549088276 KN_Kombi_BusKnockOut 0;
BA_ "GenSigSendType" SG_ 2549088276 KN_Kombi_BusKnockOutTimer 0;
BA_ "GenSigSwitchedByIgnition" SG_ 2549088276 KN_Kombi_BusKnockOutTimer 0;
BA_ "GenSigSendType" SG_ 2549088276 KN_Kombi_ECUKnockOut 0;
BA_ "GenSigSwitchedByIgnition" SG_ 2549088276 KN_Kombi_ECUKnockOut 0;
BA_ "GenSigSendType" SG_ 2549088276 KN_Kombi_ECUKnockOutTimer 0;
BA_ "GenSigSwitchedByIgnition" SG_ 2549088276 KN_Kombi_ECUKnockOutTimer 0;
BA_ "GenSigSendType" SG_ 2549088276 Kombi_Abschaltstufe 0;
BA_ "GenSigSwitchedByIgnition" SG_ 2549088276 Kombi_Abschaltstufe 0;
BA_ "GenSigSendType" SG_ 2549088276 Kombi_KompSchutz 0;
BA_ "GenSigSwitchedByIgnition" SG_ 2549088276 Kombi_KompSchutz 0;
BA_ "GenSigSendType" SG_ 2549088276 Kombi_Nachlauftyp 0;
BA_ "GenSigStartValue" SG_ 2549088276 Kombi_Nachlauftyp 2;
BA_ "GenSigSwitchedByIgnition" SG_ 2549088276 Kombi_Nachlauftyp 0;
BA_ "GenSigSendType" SG_ 2549088276 Kombi_Transport_Mode 0;
BA_ "GenSigSwitchedByIgnition" SG_ 2549088276 Kombi_Transport_Mode 0;
BA_ "GenSigSendType" SG_ 2549088276 NM_Kombi_Lokalaktiv 0;
BA_ "GenSigSwitchedByIgnition" SG_ 2549088276 NM_Kombi_Lokalaktiv 0;
BA_ "GenSigSendType" SG_ 2549088276 NM_Kombi_Subsystemaktiv 0;
BA_ "GenSigSwitchedByIgnition" SG_ 2549088276 NM_Kombi_Subsystemaktiv 0;
BA_ "GenSigSendType" SG_ 2549088276 NM_Kombi_Wakeup 0;
BA_ "NWM-WakeupAllowed" SG_ 2549088276 NM_Kombi_Wakeup 1;
BA_ "GenSigSwitchedByIgnition" SG_ 2549088276 NM_Kombi_Wakeup 0;
BA_ "GenSigSendType" SG_ 779 KBI_ABS_Lampe 0;
BA_ "GenSigSwitchedByIgnition" SG_ 779 KBI_ABS_Lampe 0;
BA_ "GenSigSendType" SG_ 779 KBI_Airbag_Lampe 0;
BA_ "GenSigSwitchedByIgnition" SG_ 779 KBI_Airbag_Lampe 0;
BA_ "GenSigSendType" SG_ 779 KBI_angez_Geschw 0;
BA_ "GenSigSwitchedByIgnition" SG_ 779 KBI_angez_Geschw 0;
BA_ "GenSigSendType" SG_ 779 KBI_Anzeigefehler_LDW 0;
BA_ "GenSigSwitchedByIgnition" SG_ 779 KBI_Anzeigefehler_LDW 0;
BA_ "GenSigSendType" SG_ 779 KBI_Anzeigefehler_NV 0;
BA_ "GenSigSwitchedByIgnition" SG_ 779 KBI_Anzeigefehler_NV 0;
BA_ "GenSigSendType" SG_ 779 KBI_Anzeigefehler_SWA 0;
BA_ "GenSigSwitchedByIgnition" SG_ 779 KBI_Anzeigefehler_SWA 0;
BA_ "GenSigSendType" SG_ 779 KBI_Anzeigestatus_ACC 0;
BA_ "GenSigSwitchedByIgnition" SG_ 779 KBI_Anzeigestatus_ACC 0;
BA_ "GenSigSendType" SG_ 779 KBI_Anzeigestatus_GRA 0;
BA_ "GenSigSwitchedByIgnition" SG_ 779 KBI_Anzeigestatus_GRA 0;
BA_ "Fehlerwert" SG_ 779 KBI_Anzeigestatus_GRA 3;
BA_ "GenSigSendType" SG_ 779 KBI_Anzeigestatus_LIM 0;
BA_ "GenSigSwitchedByIgnition" SG_ 779 KBI_Anzeigestatus_LIM 0;
BA_ "Fehlerwert" SG_ 779 KBI_Anzeigestatus_LIM 3;
BA_ "GenSigSendType" SG_ 779 KBI_Anzeigestatus_RHP 0;
BA_ "GenSigSwitchedByIgnition" SG_ 779 KBI_Anzeigestatus_RHP 0;
BA_ "GenSigSendType" SG_ 779 KBI_ARA_in_Anzeige 0;
BA_ "GenSigSwitchedByIgnition" SG_ 779 KBI_ARA_in_Anzeige 0;
BA_ "GenSigSendType" SG_ 779 KBI_Audioabsenkung_MIB 0;
BA_ "GenSigSwitchedByIgnition" SG_ 779 KBI_Audioabsenkung_MIB 0;
BA_ "GenSigSendType" SG_ 779 KBI_Bestaetigung_ESP_Off 0;
BA_ "GenSigSwitchedByIgnition" SG_ 779 KBI_Bestaetigung_ESP_Off 0;
BA_ "GenSigSendType" SG_ 779 KBI_BKL_Lampe 0;
BA_ "GenSigSwitchedByIgnition" SG_ 779 KBI_BKL_Lampe 0;
BA_ "GenSigSendType" SG_ 779 KBI_ESP_Lampe 0;
BA_ "GenSigSwitchedByIgnition" SG_ 779 KBI_ESP_Lampe 0;
BA_ "GenSigSendType" SG_ 779 KBI_Fehler_Anzeige_ACC 0;
BA_ "GenSigSwitchedByIgnition" SG_ 779 KBI_Fehler_Anzeige_ACC 0;
BA_ "GenSigSendType" SG_ 779 KBI_Handbremse 0;
BA_ "GenSigSwitchedByIgnition" SG_ 779 KBI_Handbremse 0;
BA_ "GenSigSendType" SG_ 779 KBI_im_Stellgliedtest 0;
BA_ "GenSigSwitchedByIgnition" SG_ 779 KBI_im_Stellgliedtest 0;
BA_ "GenSigSendType" SG_ 779 KBI_Konsistenz_ACC 0;
BA_ "GenSigSwitchedByIgnition" SG_ 779 KBI_Konsistenz_ACC 0;
BA_ "GenSigSendType" SG_ 779 KBI_Lenkung_Lampe 0;
BA_ "GenSigSwitchedByIgnition" SG_ 779 KBI_Lenkung_Lampe 0;
BA_ "GenSigSendType" SG_ 779 KBI_MFA_v_Einheit_01 0;
BA_ "GenSigSwitchedByIgnition" SG_ 779 KBI_MFA_v_Einheit_01 0;
BA_ "GenSigSendType" SG_ 779 KBI_NV_in_Anzeige 0;
BA_ "GenSigSwitchedByIgnition" SG_ 779 KBI_NV_in_Anzeige 0;
BA_ "GenSigSendType" SG_ 779 KBI_Oeldruck_Schalter 0;
BA_ "GenSigSwitchedByIgnition" SG_ 779 KBI_Oeldruck_Schalter 0;
BA_ "GenSigSendType" SG_ 779 KBI_Oeldruckwarnung 0;
BA_ "GenSigSwitchedByIgnition" SG_ 779 KBI_Oeldruckwarnung 0;
BA_ "GenSigSendType" SG_ 779 KBI_PLA_in_Anzeige 0;
BA_ "GenSigSwitchedByIgnition" SG_ 779 KBI_PLA_in_Anzeige 0;
BA_ "GenSigSendType" SG_ 779 KBI_SILA_gueltig 0;
BA_ "GenSigSwitchedByIgnition" SG_ 779 KBI_SILA_gueltig 0;
BA_ "GenSigSendType" SG_ 779 KBI_Systemstatus 0;
BA_ "GenSigSwitchedByIgnition" SG_ 779 KBI_Systemstatus 0;
BA_ "GenSigSendType" SG_ 779 KBI_Tankwarnung 0;
BA_ "GenSigSwitchedByIgnition" SG_ 779 KBI_Tankwarnung 0;
BA_ "GenSigSendType" SG_ 779 KBI_Tankwarnung_ungueltig 0;
BA_ "GenSigStartValue" SG_ 779 KBI_Tankwarnung_ungueltig 1;
BA_ "GenSigSwitchedByIgnition" SG_ 779 KBI_Tankwarnung_ungueltig 0;
BA_ "GenSigSendType" SG_ 779 KBI_Taster_Fahrwerk 0;
BA_ "GenSigSwitchedByIgnition" SG_ 779 KBI_Taster_Fahrwerk 0;
BA_ "GenSigSendType" SG_ 779 KBI_Taster_Lift 0;
BA_ "GenSigSwitchedByIgnition" SG_ 779 KBI_Taster_Lift 0;
BA_ "GenSigSendType" SG_ 779 KBI_V_Digital 0;
BA_ "GenSigSwitchedByIgnition" SG_ 779 KBI_V_Digital 0;
BA_ "GenSigSendType" SG_ 779 KBI_Vorglueh_System_Lampe 0;
BA_ "GenSigSwitchedByIgnition" SG_ 779 KBI_Vorglueh_System_Lampe 0;
BA_ "GenSigSendType" SG_ 779 Kombi_01_BZ 0;
BA_ "GenSigFuncType" SG_ 779 Kombi_01_BZ 1;
BA_ "GenSigSwitchedByIgnition" SG_ 779 Kombi_01_BZ 0;
BA_ "GenSigSendType" SG_ 1719 KBI_aktive_Laengsfunktion_02 3;
BA_ "GenSigSendType" SG_ 1719 KBI_Aussen_Temp_gef 0;
BA_ "GenSigStartValue" SG_ 1719 KBI_Aussen_Temp_gef 254;
BA_ "GenSigSwitchedByIgnition" SG_ 1719 KBI_Aussen_Temp_gef 0;
BA_ "Fehlerwert" SG_ 1719 KBI_Aussen_Temp_gef 255;
BA_ "GenSigSendType" SG_ 1719 KBI_FoD_PopUP_Quittiert 3;
BA_ "GenSigSendType" SG_ 1719 KBI_FStatus_Tank 0;
BA_ "GenSigSwitchedByIgnition" SG_ 1719 KBI_FStatus_Tank 0;
BA_ "GenSigSendType" SG_ 1719 KBI_GRA_im_ACC 3;
BA_ "GenSigSwitchedByIgnition" SG_ 1719 KBI_GRA_im_ACC 0;
BA_ "GenSigSendType" SG_ 1719 KBI_Inhalt_Tank 0;
BA_ "GenSigStartValue" SG_ 1719 KBI_Inhalt_Tank 126;
BA_ "GenSigSwitchedByIgnition" SG_ 1719 KBI_Inhalt_Tank 0;
BA_ "Fehlerwert" SG_ 1719 KBI_Inhalt_Tank 127;
BA_ "GenSigSendType" SG_ 1719 KBI_Kilometerstand 0;
BA_ "GenSigStartValue" SG_ 1719 KBI_Kilometerstand 1048574;
BA_ "GenSigSwitchedByIgnition" SG_ 1719 KBI_Kilometerstand 0;
BA_ "Fehlerwert" SG_ 1719 KBI_Kilometerstand 1048575;
BA_ "GenSigSendType" SG_ 1719 KBI_Oelwechsel_durchgefuehrt 0;
BA_ "GenSigSwitchedByIgnition" SG_ 1719 KBI_Oelwechsel_durchgefuehrt 0;
BA_ "GenSigSendType" SG_ 1719 KBI_QBit_Aussen_Temp_gef 0;
BA_ "GenSigStartValue" SG_ 1719 KBI_QBit_Aussen_Temp_gef 1;
BA_ "GenSigSwitchedByIgnition" SG_ 1719 KBI_QBit_Aussen_Temp_gef 0;
BA_ "GenSigSendType" SG_ 1719 KBI_RDK_Kalibrier_Anf 3;
BA_ "GenSigSwitchedByIgnition" SG_ 1719 KBI_RDK_Kalibrier_Anf 0;
BA_ "GenSigSendType" SG_ 1719 KBI_Reserve_Warnung_Sek 3;
BA_ "GenSigSwitchedByIgnition" SG_ 1719 KBI_Reserve_Warnung_Sek 0;
BA_ "GenSigSendType" SG_ 1719 KBI_Standzeit_02 0;
BA_ "GenSigStartValue" SG_ 1719 KBI_Standzeit_02 131070;
BA_ "GenSigSwitchedByIgnition" SG_ 1719 KBI_Standzeit_02 0;
BA_ "Fehlerwert" SG_ 1719 KBI_Standzeit_02 131071;
BA_ "GenSigSendType" SG_ 1720 KBI_BCmE_aktiv 0;
BA_ "GenSigSwitchedByIgnition" SG_ 1720 KBI_BCmE_aktiv 0;
BA_ "GenSigSendType" SG_ 1720 KBI_GAP_Warn_Zeit_abgelaufen 0;
BA_ "GenSigSwitchedByIgnition" SG_ 1720 KBI_GAP_Warn_Zeit_abgelaufen 0;
BA_ "GenSigSendType" SG_ 1720 KBI_Max_Tankinhalt 0;
BA_ "GenSigStartValue" SG_ 1720 KBI_Max_Tankinhalt 254;
BA_ "GenSigSwitchedByIgnition" SG_ 1720 KBI_Max_Tankinhalt 0;
BA_ "Fehlerwert" SG_ 1720 KBI_Max_Tankinhalt 255;
BA_ "GenSigSendType" SG_ 1720 KBI_Nachtanken_erkannt 0;
BA_ "GenSigSwitchedByIgnition" SG_ 1720 KBI_Nachtanken_erkannt 0;
BA_ "GenSigSendType" SG_ 1720 KBI_Quittierung_cAQP 0;
BA_ "GenSigSwitchedByIgnition" SG_ 1720 KBI_Quittierung_cAQP 0;
BA_ "GenSigSendType" SG_ 1720 KBI_Quittierung_Naesse 0;
BA_ "GenSigSwitchedByIgnition" SG_ 1720 KBI_Quittierung_Naesse 0;
BA_ "GenSigSendType" SG_ 1720 KBI_Reifenumfang 0;
BA_ "GenSigFuncType" SG_ 1720 KBI_Reifenumfang 8;
BA_ "GenSigSwitchedByIgnition" SG_ 1720 KBI_Reifenumfang 0;
BA_ "GenSigSendType" SG_ 1720 KBI_Reifenumfang_Sekundaer 0;
BA_ "GenSigSwitchedByIgnition" SG_ 1720 KBI_Reifenumfang_Sekundaer 0;
BA_ "GenSigSendType" SG_ 1720 KBI_Sparhinweis_quittiert 0;
BA_ "GenSigSwitchedByIgnition" SG_ 1720 KBI_Sparhinweis_quittiert 0;
BA_ "GenSigSendType" SG_ 1720 KBI_Tankfuellstand_Prozent 0;
BA_ "GenSigStartValue" SG_ 1720 KBI_Tankfuellstand_Prozent 126;
BA_ "GenSigSwitchedByIgnition" SG_ 1720 KBI_Tankfuellstand_Prozent 0;
BA_ "Fehlerwert" SG_ 1720 KBI_Tankfuellstand_Prozent 127;
BA_ "GenSigSendType" SG_ 1720 KBI_Tankinhalt_hochaufl 0;
BA_ "GenSigStartValue" SG_ 1720 KBI_Tankinhalt_hochaufl 16382;
BA_ "GenSigSwitchedByIgnition" SG_ 1720 KBI_Tankinhalt_hochaufl 0;
BA_ "Fehlerwert" SG_ 1720 KBI_Tankinhalt_hochaufl 16383;
BA_ "GenSigSendType" SG_ 1720 KBI_Variante 0;
BA_ "GenSigSwitchedByIgnition" SG_ 1720 KBI_Variante 0;
BA_ "GenSigSendType" SG_ 1720 KBI_Variante_USA 0;
BA_ "GenSigSwitchedByIgnition" SG_ 1720 KBI_Variante_USA 0;
BA_ "GenSigSendType" SG_ 1722 SOK_Kombi_03_Signatur 0;
BA_ "GenSigFuncType" SG_ 1722 SOK_Kombi_03_Signatur 15;
BA_ "GenSigSwitchedByIgnition" SG_ 1722 SOK_Kombi_03_Signatur 0;
BA_ "GenSigSendType" SG_ 2527679639 AuthTime_Trigger_Distribution 4;
BA_ "GenSigSwitchedByIgnition" SG_ 2527679639 AuthTime_Trigger_Distribution 0;
BA_ "GenSigSendType" SG_ 2527679639 KBI_Anzeige_ID_quittiert 5;
BA_ "GenSigSwitchedByIgnition" SG_ 2527679639 KBI_Anzeige_ID_quittiert 0;
BA_ "GenSigSendType" SG_ 2527679639 KBI_FoD_VirtualCockpitPlus_State 3;
BA_ "GenSigSwitchedByIgnition" SG_ 2527679639 KBI_FoD_VirtualCockpitPlus_State 0;
BA_ "GenSigSendType" SG_ 2527679639 KBI_Jokerkey 3;
BA_ "GenSigSwitchedByIgnition" SG_ 2527679639 KBI_Jokerkey 0;
BA_ "GenSigSendType" SG_ 2527679639 KBI_Min_Tankinhalt 0;
BA_ "GenSigStartValue" SG_ 2527679639 KBI_Min_Tankinhalt 126;
BA_ "GenSigSwitchedByIgnition" SG_ 2527679639 KBI_Min_Tankinhalt 0;
BA_ "Fehlerwert" SG_ 2527679639 KBI_Min_Tankinhalt 127;
BA_ "GenSigSendType" SG_ 2527679639 KBI_RS_Druck_uebernehmen 3;
BA_ "GenSigSwitchedByIgnition" SG_ 2527679639 KBI_RS_Druck_uebernehmen 0;
BA_ "GenSigSendType" SG_ 2527679639 KBI_RS_Druckauswahl_Aktiv 3;
BA_ "GenSigSwitchedByIgnition" SG_ 2527679639 KBI_RS_Druckauswahl_Aktiv 0;
BA_ "GenSigSendType" SG_ 2527679639 KBI_RS_Mode_fortsetzen 3;
BA_ "GenSigSwitchedByIgnition" SG_ 2527679639 KBI_RS_Mode_fortsetzen 0;
BA_ "GenSigSendType" SG_ 2527679639 KBI_Rundstreckenmodus 3;
BA_ "GenSigSwitchedByIgnition" SG_ 2527679639 KBI_Rundstreckenmodus 0;
BA_ "GenSigSendType" SG_ 2527679639 KBI_Weg_Zaehler 3;
BA_ "GenSigSwitchedByIgnition" SG_ 2527679639 KBI_Weg_Zaehler 0;
BA_ "GenSigSendType" SG_ 2527679639 KBI_Weg_Zaehler_F 3;
BA_ "GenSigSwitchedByIgnition" SG_ 2527679639 KBI_Weg_Zaehler_F 0;
BA_ "Fehlerwert" SG_ 2527679639 KBI_Weg_Zaehler_F 1;
BA_ "GenSigSendType" SG_ 2589283631 KBI_BC_Reset_E1 0;
BA_ "GenSigStartValue" SG_ 2589283631 KBI_BC_Reset_E1 7;
BA_ "GenSigSwitchedByIgnition" SG_ 2589283631 KBI_BC_Reset_E1 0;
BA_ "GenSigSendType" SG_ 2589283631 KBI_BC_Reset_E2 0;
BA_ "GenSigStartValue" SG_ 2589283631 KBI_BC_Reset_E2 7;
BA_ "GenSigSwitchedByIgnition" SG_ 2589283631 KBI_BC_Reset_E2 0;
BA_ "GenSigSendType" SG_ 2589283631 KBI_BC_Reset_E3 0;
BA_ "GenSigStartValue" SG_ 2589283631 KBI_BC_Reset_E3 7;
BA_ "GenSigSwitchedByIgnition" SG_ 2589283631 KBI_BC_Reset_E3 0;
BA_ "GenSigSendType" SG_ 2589283631 KBI_Kilometerstand_HiRes 0;
BA_ "GenSigSwitchedByIgnition" SG_ 2589283631 KBI_Kilometerstand_HiRes 0;
BA_ "GenSigSendType" SG_ 2589283631 KBI_Tankinhalt_roh 0;
BA_ "GenSigStartValue" SG_ 2589283631 KBI_Tankinhalt_roh 2046;
BA_ "GenSigSwitchedByIgnition" SG_ 2589283631 KBI_Tankinhalt_roh 0;
BA_ "Fehlerwert" SG_ 2589283631 KBI_Tankinhalt_roh 2047;
BA_ "GenSigSendType" SG_ 2527679656 KBI_StartupAnimation 3;
BA_ "GenSigSwitchedByIgnition" SG_ 2527679656 KBI_StartupAnimation 0;
BA_ "GenSigSendType" SG_ 2589283935 KBI_Curr_View 4;
BA_ "GenSigSwitchedByIgnition" SG_ 2589283935 KBI_Curr_View 0;
BA_ "GenSigSendType" SG_ 2589283935 KBI_Sec_View_Status 4;
BA_ "GenSigSwitchedByIgnition" SG_ 2589283935 KBI_Sec_View_Status 0;
BA_ "GenSigSendType" SG_ 2589283935 KBI_View1 0;
BA_ "GenSigSwitchedByIgnition" SG_ 2589283935 KBI_View1 0;
BA_ "GenSigSendType" SG_ 2589283935 KBI_View10 0;
BA_ "GenSigSwitchedByIgnition" SG_ 2589283935 KBI_View10 0;
BA_ "GenSigSendType" SG_ 2589283935 KBI_View11 0;
BA_ "GenSigSwitchedByIgnition" SG_ 2589283935 KBI_View11 0;
BA_ "GenSigSendType" SG_ 2589283935 KBI_View12 0;
BA_ "GenSigSwitchedByIgnition" SG_ 2589283935 KBI_View12 0;
BA_ "GenSigSendType" SG_ 2589283935 KBI_View13 0;
BA_ "GenSigSwitchedByIgnition" SG_ 2589283935 KBI_View13 0;
BA_ "GenSigSendType" SG_ 2589283935 KBI_View14 0;
BA_ "GenSigSwitchedByIgnition" SG_ 2589283935 KBI_View14 0;
BA_ "GenSigSendType" SG_ 2589283935 KBI_View15 0;
BA_ "GenSigSwitchedByIgnition" SG_ 2589283935 KBI_View15 0;
BA_ "GenSigSendType" SG_ 2589283935 KBI_View16 0;
BA_ "GenSigSwitchedByIgnition" SG_ 2589283935 KBI_View16 0;
BA_ "GenSigSendType" SG_ 2589283935 KBI_View17 0;
BA_ "GenSigSwitchedByIgnition" SG_ 2589283935 KBI_View17 0;
BA_ "GenSigSendType" SG_ 2589283935 KBI_View18 0;
BA_ "GenSigSwitchedByIgnition" SG_ 2589283935 KBI_View18 0;
BA_ "GenSigSendType" SG_ 2589283935 KBI_View19 0;
BA_ "GenSigSwitchedByIgnition" SG_ 2589283935 KBI_View19 0;
BA_ "GenSigSendType" SG_ 2589283935 KBI_View2 0;
BA_ "GenSigSwitchedByIgnition" SG_ 2589283935 KBI_View2 0;
BA_ "GenSigSendType" SG_ 2589283935 KBI_View20 0;
BA_ "GenSigSwitchedByIgnition" SG_ 2589283935 KBI_View20 0;
BA_ "GenSigSendType" SG_ 2589283935 KBI_View21 0;
BA_ "GenSigSwitchedByIgnition" SG_ 2589283935 KBI_View21 0;
BA_ "GenSigSendType" SG_ 2589283935 KBI_View22 0;
BA_ "GenSigSwitchedByIgnition" SG_ 2589283935 KBI_View22 0;
BA_ "GenSigSendType" SG_ 2589283935 KBI_View23 0;
BA_ "GenSigSwitchedByIgnition" SG_ 2589283935 KBI_View23 0;
BA_ "GenSigSendType" SG_ 2589283935 KBI_View24 0;
BA_ "GenSigSwitchedByIgnition" SG_ 2589283935 KBI_View24 0;
BA_ "GenSigSendType" SG_ 2589283935 KBI_View3 0;
BA_ "GenSigSwitchedByIgnition" SG_ 2589283935 KBI_View3 0;
BA_ "GenSigSendType" SG_ 2589283935 KBI_View4 0;
BA_ "GenSigSwitchedByIgnition" SG_ 2589283935 KBI_View4 0;
BA_ "GenSigSendType" SG_ 2589283935 KBI_View5 0;
BA_ "GenSigSwitchedByIgnition" SG_ 2589283935 KBI_View5 0;
BA_ "GenSigSendType" SG_ 2589283935 KBI_View6 0;
BA_ "GenSigSwitchedByIgnition" SG_ 2589283935 KBI_View6 0;
BA_ "GenSigSendType" SG_ 2589283935 KBI_View7 0;
BA_ "GenSigSwitchedByIgnition" SG_ 2589283935 KBI_View7 0;
BA_ "GenSigSendType" SG_ 2589283935 KBI_View8 0;
BA_ "GenSigSwitchedByIgnition" SG_ 2589283935 KBI_View8 0;
BA_ "GenSigSendType" SG_ 2589283935 KBI_View9 0;
BA_ "GenSigSwitchedByIgnition" SG_ 2589283935 KBI_View9 0;
BA_ "GenSigSendType" SG_ 1614 KBI_HUD_Data_01 3;
BA_ "GenSigSwitchedByIgnition" SG_ 1614 KBI_HUD_Data_01 0;
BA_ "GenSigSendType" SG_ 1614 KBI_HUD_Data_02 3;
BA_ "GenSigSwitchedByIgnition" SG_ 1614 KBI_HUD_Data_02 0;
BA_ "GenSigSendType" SG_ 1614 KBI_HUD_Data_03 3;
BA_ "GenSigSwitchedByIgnition" SG_ 1614 KBI_HUD_Data_03 0;
BA_ "GenSigSendType" SG_ 1614 KBI_HUD_Data_04 3;
BA_ "GenSigSwitchedByIgnition" SG_ 1614 KBI_HUD_Data_04 0;
BA_ "GenSigSendType" SG_ 1614 KBI_HUD_Data_05 3;
BA_ "GenSigSwitchedByIgnition" SG_ 1614 KBI_HUD_Data_05 0;
BA_ "GenSigSendType" SG_ 1614 KBI_HUD_Data_06 3;
BA_ "GenSigSwitchedByIgnition" SG_ 1614 KBI_HUD_Data_06 0;
BA_ "GenSigSendType" SG_ 1614 KBI_HUD_Data_07 3;
BA_ "GenSigSwitchedByIgnition" SG_ 1614 KBI_HUD_Data_07 0;
BA_ "GenSigSendType" SG_ 1614 KBI_HUD_Data_08 3;
BA_ "GenSigSwitchedByIgnition" SG_ 1614 KBI_HUD_Data_08 0;
BA_ "GenSigSendType" SG_ 2621440276 KS_Kombi_Req_FD_Data 3;
BA_ "GenSigFuncType" SG_ 2621440276 KS_Kombi_Req_FD_Data 9;
BA_ "GenSigSwitchedByIgnition" SG_ 2621440276 KS_Kombi_Req_FD_Data 0;
BA_ "GenSigSendType" SG_ 2621571348 KS_Kombi_Resp_FD_Data 3;
BA_ "GenSigFuncType" SG_ 2621571348 KS_Kombi_Resp_FD_Data 9;
BA_ "GenSigSwitchedByIgnition" SG_ 2621571348 KS_Kombi_Resp_FD_Data 0;
BA_ "GenSigSendType" SG_ 919 aLDW_FoD_Status 0;
BA_ "GenSigSendType" SG_ 919 HC_Uss_Anforderung 3;
BA_ "GenSigSendType" SG_ 919 LDW_DLC 0;
BA_ "GenSigStartValue" SG_ 919 LDW_DLC 250;
BA_ "GenSigSendType" SG_ 919 LDW_Frueh_Spaet 0;
BA_ "GenSigStartValue" SG_ 919 LDW_Frueh_Spaet 2;
BA_ "Fehlerwert" SG_ 919 LDW_Frueh_Spaet 3;
BA_ "GenSigSendType" SG_ 919 LDW_Gong 0;
BA_ "GenSigSendType" SG_ 919 LDW_Lernmodus_seitenabhaengig 3;
BA_ "GenSigSendType" SG_ 919 LDW_Seite_DLCTLC 0;
BA_ "GenSigSendType" SG_ 919 LDW_Status_Anzeige 0;
BA_ "GenSigSendType" SG_ 919 LDW_Status_LED_gelb 0;
BA_ "GenSigSendType" SG_ 919 LDW_Status_LED_gruen 0;
BA_ "GenSigSendType" SG_ 919 LDW_Texte 0;
BA_ "GenSigSendType" SG_ 919 LDW_TLC 0;
BA_ "GenSigStartValue" SG_ 919 LDW_TLC 31;
BA_ "GenSigSendType" SG_ 810 EPS_01_BZ 0;
BA_ "GenSigFuncType" SG_ 810 EPS_01_BZ 1;
BA_ "GenSigSwitchedByIgnition" SG_ 810 EPS_01_BZ 0;
BA_ "GenSigSendType" SG_ 810 EPS_01_CRC 0;
BA_ "GenSigFuncType" SG_ 810 EPS_01_CRC 2;
BA_ "GenSigSwitchedByIgnition" SG_ 810 EPS_01_CRC 0;
BA_ "GenSigSendType" SG_ 810 EPS_Akustiksignal 0;
BA_ "GenSigSwitchedByIgnition" SG_ 810 EPS_Akustiksignal 0;
BA_ "GenSigSendType" SG_ 810 EPS_Anf_KL 0;
BA_ "GenSigSwitchedByIgnition" SG_ 810 EPS_Anf_KL 0;
BA_ "GenSigSendType" SG_ 810 EPS_ARA_Status 0;
BA_ "GenSigSwitchedByIgnition" SG_ 810 EPS_ARA_Status 0;
BA_ "GenSigSendType" SG_ 810 EPS_Charisma_FahrPr 0;
BA_ "GenSigSwitchedByIgnition" SG_ 810 EPS_Charisma_FahrPr 0;
BA_ "GenSigSendType" SG_ 810 EPS_Charisma_Status 0;
BA_ "GenSigSwitchedByIgnition" SG_ 810 EPS_Charisma_Status 0;
BA_ "GenSigSendType" SG_ 810 EPS_Endanschlag 0;
BA_ "Fehlerwert" SG_ 810 EPS_Endanschlag 3;
BA_ "GenSigSendType" SG_ 810 EPS_Fehlerlampe 0;
BA_ "GenSigSwitchedByIgnition" SG_ 810 EPS_Fehlerlampe 0;
BA_ "GenSigSendType" SG_ 810 EPS_Lenkerposition 0;
BA_ "GenSigFuncType" SG_ 810 EPS_Lenkerposition 8;
BA_ "GenSigSwitchedByIgnition" SG_ 810 EPS_Lenkerposition 0;
BA_ "GenSigSendType" SG_ 810 EPS_PLA_Abbruch 0;
BA_ "GenSigSwitchedByIgnition" SG_ 810 EPS_PLA_Abbruch 0;
BA_ "GenSigSendType" SG_ 810 EPS_PLA_Fehler 0;
BA_ "GenSigSwitchedByIgnition" SG_ 810 EPS_PLA_Fehler 0;
BA_ "GenSigSendType" SG_ 810 EPS_PLA_Status 0;
BA_ "GenSigSwitchedByIgnition" SG_ 810 EPS_PLA_Status 0;
BA_ "GenSigSendType" SG_ 810 EPS_SpannungsAnf 0;
BA_ "GenSigSwitchedByIgnition" SG_ 810 EPS_SpannungsAnf 0;
BA_ "GenSigSendType" SG_ 810 EPS_VZ_Zst_Offset_Geradeaus 0;
BA_ "GenSigSwitchedByIgnition" SG_ 810 EPS_VZ_Zst_Offset_Geradeaus 0;
BA_ "GenSigSendType" SG_ 810 EPS_Warnungen 0;
BA_ "GenSigSwitchedByIgnition" SG_ 810 EPS_Warnungen 0;
BA_ "GenSigSendType" SG_ 810 EPS_Zst_Offset_Geradeaus 0;
BA_ "GenSigStartValue" SG_ 810 EPS_Zst_Offset_Geradeaus 510;
BA_ "GenSigSwitchedByIgnition" SG_ 810 EPS_Zst_Offset_Geradeaus 0;
BA_ "Fehlerwert" SG_ 810 EPS_Zst_Offset_Geradeaus 511;
BA_ "GenSigSendType" SG_ 981 BCM1_Abblendlicht_Anf 0;
BA_ "GenSigSwitchedByIgnition" SG_ 981 BCM1_Abblendlicht_Anf 0;
BA_ "GenSigSendType" SG_ 981 BCM1_Adaptive_Lichtvert_Anf 0;
BA_ "GenSigSwitchedByIgnition" SG_ 981 BCM1_Adaptive_Lichtvert_Anf 0;
BA_ "GenSigSendType" SG_ 981 BCM1_Allwetterlicht_Anf 0;
BA_ "GenSigSwitchedByIgnition" SG_ 981 BCM1_Allwetterlicht_Anf 0;
BA_ "GenSigSendType" SG_ 981 BCM1_Animationssperrung 3;
BA_ "GenSigStartValue" SG_ 981 BCM1_Animationssperrung 1;
BA_ "GenSigSwitchedByIgnition" SG_ 981 BCM1_Animationssperrung 0;
BA_ "GenSigSendType" SG_ 981 BCM1_Autobahnlicht_Anf 0;
BA_ "GenSigSwitchedByIgnition" SG_ 981 BCM1_Autobahnlicht_Anf 0;
BA_ "GenSigSendType" SG_ 981 BCM1_CH_aktiv 0;
BA_ "NWM-WakeupAllowed" SG_ 981 BCM1_CH_aktiv 1;
BA_ "GenSigSwitchedByIgnition" SG_ 981 BCM1_CH_aktiv 0;
BA_ "GenSigSendType" SG_ 981 BCM1_CH_LH_aktiv 0;
BA_ "GenSigSwitchedByIgnition" SG_ 981 BCM1_CH_LH_aktiv 0;
BA_ "GenSigSendType" SG_ 981 BCM1_Fernlicht_Anf 0;
BA_ "GenSigSwitchedByIgnition" SG_ 981 BCM1_Fernlicht_Anf 0;
BA_ "GenSigSendType" SG_ 981 BCM1_Gleitende_Leuchtw_Anf 0;
BA_ "GenSigSwitchedByIgnition" SG_ 981 BCM1_Gleitende_Leuchtw_Anf 0;
BA_ "GenSigSendType" SG_ 981 BCM1_GLW_Fernlicht_Anf 3;
BA_ "GenSigSwitchedByIgnition" SG_ 981 BCM1_GLW_Fernlicht_Anf 0;
BA_ "GenSigSendType" SG_ 981 BCM1_Kurvenlicht_links_Anf 0;
BA_ "GenSigSwitchedByIgnition" SG_ 981 BCM1_Kurvenlicht_links_Anf 0;
BA_ "GenSigSendType" SG_ 981 BCM1_Kurvenlicht_rechts_Anf 0;
BA_ "GenSigSwitchedByIgnition" SG_ 981 BCM1_Kurvenlicht_rechts_Anf 0;
BA_ "GenSigSendType" SG_ 981 BCM1_LH_aktiv 0;
BA_ "NWM-WakeupAllowed" SG_ 981 BCM1_LH_aktiv 1;
BA_ "GenSigSwitchedByIgnition" SG_ 981 BCM1_LH_aktiv 0;
BA_ "GenSigSendType" SG_ 981 BCM1_Nebellicht_Anf 0;
BA_ "GenSigSwitchedByIgnition" SG_ 981 BCM1_Nebellicht_Anf 0;
BA_ "GenSigSendType" SG_ 981 BCM1_Nebelschluss_Ahg_Anf 0;
BA_ "GenSigSwitchedByIgnition" SG_ 981 BCM1_Nebelschluss_Ahg_Anf 0;
BA_ "GenSigSendType" SG_ 981 BCM1_Nebelschluss_Fzg_Anf 0;
BA_ "GenSigSwitchedByIgnition" SG_ 981 BCM1_Nebelschluss_Fzg_Anf 0;
BA_ "GenSigSendType" SG_ 981 BCM1_Parklicht_li_Anf 0;
BA_ "GenSigSwitchedByIgnition" SG_ 981 BCM1_Parklicht_li_Anf 0;
BA_ "GenSigSendType" SG_ 981 BCM1_Parklicht_re_Anf 0;
BA_ "GenSigSwitchedByIgnition" SG_ 981 BCM1_Parklicht_re_Anf 0;
BA_ "GenSigSendType" SG_ 981 BCM1_Regenlicht_Anf 0;
BA_ "GenSigSwitchedByIgnition" SG_ 981 BCM1_Regenlicht_Anf 0;
BA_ "GenSigSendType" SG_ 981 BCM1_Schlusslicht_Anf 0;
BA_ "GenSigSwitchedByIgnition" SG_ 981 BCM1_Schlusslicht_Anf 0;
BA_ "GenSigSendType" SG_ 981 BCM1_Signaturlicht_Anf 0;
BA_ "GenSigSwitchedByIgnition" SG_ 981 BCM1_Signaturlicht_Anf 0;
BA_ "GenSigSendType" SG_ 981 BCM1_Standlicht_Anf 0;
BA_ "GenSigSwitchedByIgnition" SG_ 981 BCM1_Standlicht_Anf 0;
BA_ "GenSigSendType" SG_ 981 BCM1_Tagfahrlicht_Anf 0;
BA_ "GenSigSwitchedByIgnition" SG_ 981 BCM1_Tagfahrlicht_Anf 0;
BA_ "GenSigSendType" SG_ 981 BCM1_Touristen_Licht_Anf 0;
BA_ "GenSigSwitchedByIgnition" SG_ 981 BCM1_Touristen_Licht_Anf 0;
BA_ "GenSigSendType" SG_ 981 BCM1_Umfeldleuchten_Anf 0;
BA_ "GenSigSwitchedByIgnition" SG_ 981 BCM1_Umfeldleuchten_Anf 0;
BA_ "GenSigSendType" SG_ 981 BCM_Rueckfahrlicht_Anf 0;
BA_ "GenSigSwitchedByIgnition" SG_ 981 BCM_Rueckfahrlicht_Anf 0;
BA_ "GenSigSendType" SG_ 981 Licht_Anf_01_BZ 0;
BA_ "GenSigFuncType" SG_ 981 Licht_Anf_01_BZ 1;
BA_ "GenSigSwitchedByIgnition" SG_ 981 Licht_Anf_01_BZ 0;
BA_ "GenSigSendType" SG_ 981 Licht_Anf_01_CRC 0;
BA_ "GenSigFuncType" SG_ 981 Licht_Anf_01_CRC 2;
BA_ "GenSigSwitchedByIgnition" SG_ 981 Licht_Anf_01_CRC 0;
BA_ "GenSigSendType" SG_ 981 TFL_Matrix_Variante01_Anf 3;
BA_ "GenSigSendType" SG_ 981 TFL_Matrix_Variante02_Anf 3;
BA_ "GenSigSendType" SG_ 981 TFL_Matrix_Variante03_Anf 3;
BA_ "GenSigSendType" SG_ 981 TFL_Matrix_Variante04_Anf 3;
BA_ "GenSigSendType" SG_ 982 BCM2_Bremsl_durch_ECD 0;
BA_ "GenSigSwitchedByIgnition" SG_ 982 BCM2_Bremsl_durch_ECD 0;
BA_ "GenSigSendType" SG_ 982 BCM2_Bremsl_durch_ECD_invers 0;
BA_ "GenSigStartValue" SG_ 982 BCM2_Bremsl_durch_ECD_invers 1;
BA_ "GenSigSwitchedByIgnition" SG_ 982 BCM2_Bremsl_durch_ECD_invers 0;
BA_ "GenSigSendType" SG_ 982 LH_3_Bremsl_def 0;
BA_ "GenSigSwitchedByIgnition" SG_ 982 LH_3_Bremsl_def 0;
BA_ "GenSigSendType" SG_ 982 LH_Aussenlicht_def 0;
BA_ "GenSigSwitchedByIgnition" SG_ 982 LH_Aussenlicht_def 0;
BA_ "GenSigSendType" SG_ 982 LH_Blinker_HL_akt 0;
BA_ "GenSigSwitchedByIgnition" SG_ 982 LH_Blinker_HL_akt 0;
BA_ "GenSigSendType" SG_ 982 LH_Blinker_HR_akt 0;
BA_ "GenSigSwitchedByIgnition" SG_ 982 LH_Blinker_HR_akt 0;
BA_ "GenSigSendType" SG_ 982 LH_Blinker_li_def 0;
BA_ "GenSigSwitchedByIgnition" SG_ 982 LH_Blinker_li_def 0;
BA_ "GenSigSendType" SG_ 982 LH_Blinker_re_def 0;
BA_ "GenSigSwitchedByIgnition" SG_ 982 LH_Blinker_re_def 0;
BA_ "GenSigSendType" SG_ 982 LH_Brems_Blk_li_def 0;
BA_ "GenSigSwitchedByIgnition" SG_ 982 LH_Brems_Blk_li_def 0;
BA_ "GenSigSendType" SG_ 982 LH_Brems_Blk_re_def 0;
BA_ "GenSigSwitchedByIgnition" SG_ 982 LH_Brems_Blk_re_def 0;
BA_ "GenSigSendType" SG_ 982 LH_Bremsl_li_def 0;
BA_ "GenSigSwitchedByIgnition" SG_ 982 LH_Bremsl_li_def 0;
BA_ "GenSigSendType" SG_ 982 LH_Bremsl_li_ges_def 0;
BA_ "GenSigSwitchedByIgnition" SG_ 982 LH_Bremsl_li_ges_def 0;
BA_ "GenSigSendType" SG_ 982 LH_Bremsl_re_def 0;
BA_ "GenSigSwitchedByIgnition" SG_ 982 LH_Bremsl_re_def 0;
BA_ "GenSigSendType" SG_ 982 LH_Bremsl_re_ges_def 0;
BA_ "GenSigSwitchedByIgnition" SG_ 982 LH_Bremsl_re_ges_def 0;
BA_ "GenSigSendType" SG_ 982 LH_Bremslicht_H_aktiv 0;
BA_ "GenSigSwitchedByIgnition" SG_ 982 LH_Bremslicht_H_aktiv 0;
BA_ "GenSigSendType" SG_ 982 LH_Diag_LED_li_def 0;
BA_ "GenSigSwitchedByIgnition" SG_ 982 LH_Diag_LED_li_def 0;
BA_ "GenSigSendType" SG_ 982 LH_Diag_LED_re_def 0;
BA_ "GenSigSwitchedByIgnition" SG_ 982 LH_Diag_LED_re_def 0;
BA_ "GenSigSendType" SG_ 982 LH_Diag_Status_li_def 0;
BA_ "GenSigSwitchedByIgnition" SG_ 982 LH_Diag_Status_li_def 0;
BA_ "GenSigSendType" SG_ 982 LH_Diag_Status_re_def 0;
BA_ "GenSigSwitchedByIgnition" SG_ 982 LH_Diag_Status_re_def 0;
BA_ "GenSigSendType" SG_ 982 LH_Kennzl_def 0;
BA_ "GenSigSwitchedByIgnition" SG_ 982 LH_Kennzl_def 0;
BA_ "GenSigSendType" SG_ 982 LH_Nebel_li_def 0;
BA_ "GenSigSwitchedByIgnition" SG_ 982 LH_Nebel_li_def 0;
BA_ "GenSigSendType" SG_ 982 LH_Nebel_mi_def 0;
BA_ "GenSigSwitchedByIgnition" SG_ 982 LH_Nebel_mi_def 0;
BA_ "GenSigSendType" SG_ 982 LH_Nebel_re_def 0;
BA_ "GenSigSwitchedByIgnition" SG_ 982 LH_Nebel_re_def 0;
BA_ "GenSigSendType" SG_ 982 LH_Nebelschluss_aktiv 0;
BA_ "GenSigSwitchedByIgnition" SG_ 982 LH_Nebelschluss_aktiv 0;
BA_ "GenSigSendType" SG_ 982 LH_Parklicht_HL_aktiv 0;
BA_ "GenSigSwitchedByIgnition" SG_ 982 LH_Parklicht_HL_aktiv 0;
BA_ "GenSigSendType" SG_ 982 LH_Parklicht_HR_aktiv 0;
BA_ "GenSigSwitchedByIgnition" SG_ 982 LH_Parklicht_HR_aktiv 0;
BA_ "GenSigSendType" SG_ 982 LH_Rueckf_li_def 0;
BA_ "GenSigSwitchedByIgnition" SG_ 982 LH_Rueckf_li_def 0;
BA_ "GenSigSendType" SG_ 982 LH_Rueckf_mi_def 0;
BA_ "GenSigSwitchedByIgnition" SG_ 982 LH_Rueckf_mi_def 0;
BA_ "GenSigSendType" SG_ 982 LH_Rueckf_re_def 0;
BA_ "GenSigSwitchedByIgnition" SG_ 982 LH_Rueckf_re_def 0;
BA_ "GenSigSendType" SG_ 982 LH_Rueckfahrlicht_aktiv 0;
BA_ "GenSigSwitchedByIgnition" SG_ 982 LH_Rueckfahrlicht_aktiv 0;
BA_ "GenSigSendType" SG_ 982 LH_Schluss_Brems_li_def 0;
BA_ "GenSigSwitchedByIgnition" SG_ 982 LH_Schluss_Brems_li_def 0;
BA_ "GenSigSendType" SG_ 982 LH_Schluss_Brems_Nebel_li_def 0;
BA_ "GenSigSwitchedByIgnition" SG_ 982 LH_Schluss_Brems_Nebel_li_def 0;
BA_ "GenSigSendType" SG_ 982 LH_Schluss_Brems_Nebel_re_def 0;
BA_ "GenSigSwitchedByIgnition" SG_ 982 LH_Schluss_Brems_Nebel_re_def 0;
BA_ "GenSigSendType" SG_ 982 LH_Schluss_Brems_re_def 0;
BA_ "GenSigSwitchedByIgnition" SG_ 982 LH_Schluss_Brems_re_def 0;
BA_ "GenSigSendType" SG_ 982 LH_Schluss_Nebel_li_def 0;
BA_ "GenSigSwitchedByIgnition" SG_ 982 LH_Schluss_Nebel_li_def 0;
BA_ "GenSigSendType" SG_ 982 LH_Schluss_Nebel_re_def 0;
BA_ "GenSigSwitchedByIgnition" SG_ 982 LH_Schluss_Nebel_re_def 0;
BA_ "GenSigSendType" SG_ 982 LH_Schlusslicht_li_def 0;
BA_ "GenSigSwitchedByIgnition" SG_ 982 LH_Schlusslicht_li_def 0;
BA_ "GenSigSendType" SG_ 982 LH_Schlusslicht_re_def 0;
BA_ "GenSigSwitchedByIgnition" SG_ 982 LH_Schlusslicht_re_def 0;
BA_ "GenSigSendType" SG_ 982 LH_SL_BRL_BLK_li_def 0;
BA_ "GenSigSwitchedByIgnition" SG_ 982 LH_SL_BRL_BLK_li_def 0;
BA_ "GenSigSendType" SG_ 982 LH_SL_BRL_BLK_re_def 0;
BA_ "GenSigSwitchedByIgnition" SG_ 982 LH_SL_BRL_BLK_re_def 0;
BA_ "GenSigSendType" SG_ 982 LH_Standlicht_H_aktiv 0;
BA_ "GenSigSwitchedByIgnition" SG_ 982 LH_Standlicht_H_aktiv 0;
BA_ "GenSigSendType" SG_ 982 LH_Zusatzschlussl_def 0;
BA_ "GenSigSwitchedByIgnition" SG_ 982 LH_Zusatzschlussl_def 0;
BA_ "GenSigSendType" SG_ 982 Licht_hinten_01_BZ 0;
BA_ "GenSigFuncType" SG_ 982 Licht_hinten_01_BZ 1;
BA_ "GenSigSwitchedByIgnition" SG_ 982 Licht_hinten_01_BZ 0;
BA_REL_ "GenSigTimeoutTime" BU_SG_REL_ ELV SG_ 1426 KY_Fzg_Verlassen_erkannt 2000;
BA_REL_ "GenSigTimeoutTime" BU_SG_REL_ ELV SG_ 1426 KY_Fzg_Zugang_erkannt 2000;
BA_REL_ "GenSigTimeoutTime" BU_SG_REL_ ELV SG_ 2463978753 KST_Sonderzustand_Status 5000;
BA_REL_ "GenSigTimeoutTime" BU_SG_REL_ ELV SG_ 2463978753 KST_Sonderzustand_Anforderung 5000;
BA_REL_ "GenSigTimeoutTime" BU_SG_REL_ ELV SG_ 960 Klemmen_Status_01_CRC 1000;
BA_REL_ "GenSigTimeoutTime" BU_SG_REL_ ELV SG_ 960 Klemmen_Status_01_BZ 1000;
BA_REL_ "GenSigTimeoutTime" BU_SG_REL_ ELV SG_ 960 ZAS_Kl_S 1000;
BA_REL_ "GenSigTimeoutTime" BU_SG_REL_ ELV SG_ 960 ZAS_Kl_15 1000;
BA_REL_ "GenSigTimeoutTime" BU_SG_REL_ ELV SG_ 960 BCM_Remotestart_KL15_Anf 1000;
BA_REL_ "GenSigTimeoutTime" BU_SG_REL_ ELV SG_ 1420 Klemmen_Steuerung_01_CRC 5000;
BA_REL_ "GenSigTimeoutTime" BU_SG_REL_ ELV SG_ 1420 Klemmen_Steuerung_01_BZ 5000;
BA_REL_ "GenSigTimeoutTime" BU_SG_REL_ ELV SG_ 1420 KST_Anf_Klemmenfreigabe_ELV 5000;
BA_REL_ "GenSigTimeoutTime" BU_SG_REL_ Gateway_Max SG_ 2549088305 ELV_Nachlauftyp 5000;
BA_REL_ "GenSigTimeoutTime" BU_SG_REL_ Gateway_Max SG_ 2549088305 KN_ELV_DiagPfad 5000;
BA_REL_ "GenSigTimeoutTime" BU_SG_REL_ Gateway_Max SG_ 2549088305 ELV_KD_Fehler 2500;
BA_REL_ "GenSigTimeoutTime" BU_SG_REL_ Gateway_Max SG_ 2549088283 HUD_Nachlauftyp 5000;
BA_REL_ "GenSigTimeoutTime" BU_SG_REL_ Gateway_Max SG_ 2549088283 KN_HUD_DiagPfad 5000;
BA_REL_ "GenSigTimeoutTime" BU_SG_REL_ Gateway_Max SG_ 2549088283 HUD_KD_Fehler 2500;
BA_REL_ "GenSigTimeoutTime" BU_SG_REL_ Gateway_Max SG_ 2549088276 Kombi_Nachlauftyp 5000;
BA_REL_ "GenSigTimeoutTime" BU_SG_REL_ Gateway_Max SG_ 2549088276 KN_KBI_DiagPfad 5000;
BA_REL_ "GenSigTimeoutTime" BU_SG_REL_ Gateway_Max SG_ 2549088276 KBI_KD_Fehler 2500;
BA_REL_ "GenSigTimeoutTime" BU_SG_REL_ Gateway_Max SG_ 779 KBI_angez_Geschw 500;
BA_REL_ "GenSigTimeoutTime" BU_SG_REL_ Gateway_Max SG_ 1719 KBI_Kilometerstand 5000;
BA_REL_ "GenSigTimeoutTime" BU_SG_REL_ Gateway_Max SG_ 1719 KBI_Standzeit_02 5000;
BA_REL_ "GenSigTimeoutTime" BU_SG_REL_ Gateway_Max SG_ 1719 KBI_Aussen_Temp_gef 5000;
BA_REL_ "GenSigTimeoutTime" BU_SG_REL_ Gateway_Max SG_ 1720 KBI_Reifenumfang 5000;
BA_REL_ "GenSigTimeoutTime" BU_SG_REL_ Gateway_Max SG_ 1720 KBI_Nachtanken_erkannt 5000;
BA_REL_ "GenSigTimeoutTime" BU_SG_REL_ Gateway_Max SG_ 1720 KBI_Tankinhalt_hochaufl 5000;
BA_REL_ "GenSigTimeoutTime" BU_SG_REL_ Gateway_Max SG_ 1720 KBI_Max_Tankinhalt 5000;
BA_REL_ "GenSigTimeoutTime" BU_SG_REL_ Gateway_Max SG_ 2527679639 KBI_Min_Tankinhalt 5000;
BA_REL_ "GenSigTimeoutTime" BU_SG_REL_ Gateway_Max SG_ 2527679639 AuthTime_Trigger_Distribution 5000;
BA_REL_ "GenSigTimeoutTime" BU_SG_REL_ Gateway_Max SG_ 2527679639 KBI_FoD_VirtualCockpitPlus_State 5000;
BA_REL_ "GenSigTimeoutTime" BU_SG_REL_ Gateway_Max SG_ 2589283631 KBI_BC_Reset_E1 5000;
BA_REL_ "GenSigTimeoutTime" BU_SG_REL_ Gateway_Max SG_ 2589283631 KBI_BC_Reset_E2 5000;
BA_REL_ "GenSigTimeoutTime" BU_SG_REL_ Gateway_Max SG_ 2589283631 KBI_BC_Reset_E3 5000;
BA_REL_ "GenSigTimeoutTime" BU_SG_REL_ Gateway_Max SG_ 2589283631 KBI_Kilometerstand_HiRes 5000;
BA_REL_ "GenSigTimeoutTime" BU_SG_REL_ HUD SG_ 960 ZAS_Kl_15 1000;
BA_REL_ "GenSigTimeoutTime" BU_SG_REL_ HUD SG_ 779 KBI_MFA_v_Einheit_01 500;
BA_REL_ "GenSigTimeoutTime" BU_SG_REL_ HUD SG_ 779 KBI_V_Digital 500;
BA_REL_ "GenSigTimeoutTime" BU_SG_REL_ HUD SG_ 1614 KBI_HUD_Data_01 5000;
BA_REL_ "GenSigTimeoutTime" BU_SG_REL_ HUD SG_ 1614 KBI_HUD_Data_02 5000;
BA_REL_ "GenSigTimeoutTime" BU_SG_REL_ HUD SG_ 1614 KBI_HUD_Data_03 5000;
BA_REL_ "GenSigTimeoutTime" BU_SG_REL_ HUD SG_ 1614 KBI_HUD_Data_04 5000;
BA_REL_ "GenSigTimeoutTime" BU_SG_REL_ HUD SG_ 1614 KBI_HUD_Data_05 5000;
BA_REL_ "GenSigTimeoutTime" BU_SG_REL_ HUD SG_ 1614 KBI_HUD_Data_06 5000;
BA_REL_ "GenSigTimeoutTime" BU_SG_REL_ HUD SG_ 1614 KBI_HUD_Data_07 5000;
BA_REL_ "GenSigTimeoutTime" BU_SG_REL_ HUD SG_ 1614 KBI_HUD_Data_08 5000;
BA_REL_ "GenSigTimeoutTime" BU_SG_REL_ HUD SG_ 919 LDW_Texte 1000;
BA_REL_ "GenSigTimeoutTime" BU_SG_REL_ HUD SG_ 919 LDW_Status_Anzeige 1000;
BA_REL_ "GenSigTimeoutTime" BU_SG_REL_ HUD SG_ 919 LDW_Lernmodus_seitenabhaengig 1000;
BA_REL_ "GenSigTimeoutTime" BU_SG_REL_ HUD SG_ 919 aLDW_FoD_Status 1000;
BA_REL_ "GenSigTimeoutTime" BU_SG_REL_ Kombi SG_ 960 Klemmen_Status_01_CRC 1000;
BA_REL_ "GenSigTimeoutTime" BU_SG_REL_ Kombi SG_ 960 Klemmen_Status_01_BZ 1000;
BA_REL_ "GenSigTimeoutTime" BU_SG_REL_ Kombi SG_ 960 RSt_Fahrerhinweise 1000;
BA_REL_ "GenSigTimeoutTime" BU_SG_REL_ Kombi SG_ 960 ZAS_Kl_S 1000;
BA_REL_ "GenSigTimeoutTime" BU_SG_REL_ Kombi SG_ 960 ZAS_Kl_15 1000;
BA_REL_ "GenSigTimeoutTime" BU_SG_REL_ Kombi SG_ 960 BCM_Remotestart_KL15_Anf 1000;
BA_REL_ "GenSigTimeoutTime" BU_SG_REL_ Kombi SG_ 960 KST_Warn_P2_ZST_def 1000;
BA_REL_ "GenSigTimeoutTime" BU_SG_REL_ Kombi SG_ 960 KST_Fahrerhinweis_2 1000;
BA_REL_ "GenSigTimeoutTime" BU_SG_REL_ Kombi SG_ 960 KST_Fahrerhinweis_6 1000;
BA_REL_ "GenSigTimeoutTime" BU_SG_REL_ Kombi SG_ 1420 KST_Txt_Werkstatt 5000;
BA_REL_ "GenSigTimeoutTime" BU_SG_REL_ Kombi SG_ 1420 KST_Txt_P_Gang 5000;
BA_REL_ "GenSigTimeoutTime" BU_SG_REL_ Kombi SG_ 1420 KST_Txt_Panikabschaltung 5000;
BA_REL_ "GenSigTimeoutTime" BU_SG_REL_ Kombi SG_ 1420 KST_Txt_Komfortabschaltung 5000;
BA_REL_ "GenSigTimeoutTime" BU_SG_REL_ Kombi SG_ 1420 KST_Zuendungswarnung 5000;
BA_REL_ "GenSigTimeoutTime" BU_SG_REL_ Kombi SG_ 1420 KST_Anzeige_Klemmenzustand 5000;
BA_REL_ "GenSigTimeoutTime" BU_SG_REL_ Kombi SG_ 1646 KL_Geblaese_Status 5000;
BA_REL_ "GenSigTimeoutTime" BU_SG_REL_ Kombi SG_ 1640 KL_LRH_Stufe 2000;
BA_REL_ "GenSigTimeoutTime" BU_SG_REL_ Kombi SG_ 1505 BCM1_Aussen_Temp_ungef 2000;
BA_REL_ "GenSigTimeoutTime" BU_SG_REL_ Kombi SG_ 1505 BCM1_FStatus_Aussentemp_ungef 2000;
BA_REL_ "GenSigTimeoutTime" BU_SG_REL_ Kombi SG_ 919 LDW_Gong 1000;
BA_REL_ "GenSigTimeoutTime" BU_SG_REL_ Kombi SG_ 919 LDW_Texte 1000;
BA_REL_ "GenSigTimeoutTime" BU_SG_REL_ Kombi SG_ 919 LDW_Status_Anzeige 1000;
BA_REL_ "GenSigTimeoutTime" BU_SG_REL_ Kombi SG_ 919 LDW_Lernmodus_seitenabhaengig 1000;
BA_REL_ "GenSigTimeoutTime" BU_SG_REL_ Kombi SG_ 919 aLDW_FoD_Status 1000;
BA_REL_ "GenSigTimeoutTime" BU_SG_REL_ Kombi SG_ 919 LDW_Status_LED_gelb 1000;
BA_REL_ "GenSigTimeoutTime" BU_SG_REL_ Kombi SG_ 919 LDW_Status_LED_gruen 1000;
BA_REL_ "GenSigTimeoutTime" BU_SG_REL_ Kombi SG_ 810 EPS_01_CRC 500;
BA_REL_ "GenSigTimeoutTime" BU_SG_REL_ Kombi SG_ 810 EPS_01_BZ 500;
BA_REL_ "GenSigTimeoutTime" BU_SG_REL_ Kombi SG_ 810 EPS_Warnungen 500;
BA_REL_ "GenSigTimeoutTime" BU_SG_REL_ Kombi SG_ 981 BCM1_Standlicht_Anf 1000;
BA_REL_ "GenSigTimeoutTime" BU_SG_REL_ Kombi SG_ 981 BCM1_Abblendlicht_Anf 1000;
BA_REL_ "GenSigTimeoutTime" BU_SG_REL_ Kombi SG_ 981 BCM1_Nebelschluss_Fzg_Anf 1000;
BA_REL_ "GenSigTimeoutTime" BU_SG_REL_ Kombi SG_ 981 BCM1_Schlusslicht_Anf 1000;
BA_REL_ "GenSigTimeoutTime" BU_SG_REL_ Kombi SG_ 981 BCM_Rueckfahrlicht_Anf 1000;
BA_REL_ "GenSigTimeoutTime" BU_SG_REL_ Kombi SG_ 981 BCM1_Tagfahrlicht_Anf 1000;
BA_REL_ "GenSigTimeoutTime" BU_SG_REL_ Kombi SG_ 981 BCM1_Allwetterlicht_Anf 1000;
BA_REL_ "GenSigTimeoutTime" BU_SG_REL_ Kombi SG_ 982 LH_Aussenlicht_def 1000;
BA_REL_ "GenSigTimeoutTime" BU_SG_REL_ Kombi SG_ 982 LH_Bremslicht_H_aktiv 1000;
BA_REL_ "GenSigTimeoutTime" BU_SG_REL_ Kombi SG_ 982 LH_Blinker_li_def 1000;
BA_REL_ "GenSigTimeoutTime" BU_SG_REL_ Kombi SG_ 982 LH_Bremsl_li_def 1000;
BA_REL_ "GenSigTimeoutTime" BU_SG_REL_ Kombi SG_ 982 LH_Schlusslicht_li_def 1000;
BA_REL_ "GenSigTimeoutTime" BU_SG_REL_ Kombi SG_ 982 LH_Rueckf_li_def 1000;
BA_REL_ "GenSigTimeoutTime" BU_SG_REL_ Kombi SG_ 982 LH_Nebel_li_def 1000;
BA_REL_ "GenSigTimeoutTime" BU_SG_REL_ Kombi SG_ 982 LH_Schluss_Brems_Nebel_li_def 1000;
BA_REL_ "GenSigTimeoutTime" BU_SG_REL_ Kombi SG_ 982 LH_Schluss_Brems_Nebel_re_def 1000;
BA_REL_ "GenSigTimeoutTime" BU_SG_REL_ Kombi SG_ 982 LH_Zusatzschlussl_def 1000;
BA_REL_ "GenSigTimeoutTime" BU_SG_REL_ Kombi SG_ 982 LH_Schluss_Brems_li_def 1000;
BA_REL_ "GenSigTimeoutTime" BU_SG_REL_ Kombi SG_ 982 LH_Schluss_Nebel_li_def 1000;
BA_REL_ "GenSigTimeoutTime" BU_SG_REL_ Kombi SG_ 982 LH_SL_BRL_BLK_li_def 1000;
BA_REL_ "GenSigTimeoutTime" BU_SG_REL_ Kombi SG_ 982 LH_Brems_Blk_li_def 1000;
BA_REL_ "GenSigTimeoutTime" BU_SG_REL_ Kombi SG_ 982 LH_Diag_Status_re_def 1000;
BA_REL_ "GenSigTimeoutTime" BU_SG_REL_ Kombi SG_ 982 LH_Diag_Status_li_def 1000;
BA_REL_ "GenSigTimeoutTime" BU_SG_REL_ Kombi SG_ 982 LH_Diag_LED_li_def 1000;
BA_REL_ "GenSigTimeoutTime" BU_SG_REL_ Kombi SG_ 982 LH_Diag_LED_re_def 1000;
BA_REL_ "GenSigTimeoutTime" BU_SG_REL_ Kombi SG_ 982 LH_Blinker_re_def 1000;
BA_REL_ "GenSigTimeoutTime" BU_SG_REL_ Kombi SG_ 982 LH_Bremsl_re_def 1000;
BA_REL_ "GenSigTimeoutTime" BU_SG_REL_ Kombi SG_ 982 LH_Schlusslicht_re_def 1000;
BA_REL_ "GenSigTimeoutTime" BU_SG_REL_ Kombi SG_ 982 LH_Rueckf_re_def 1000;
BA_REL_ "GenSigTimeoutTime" BU_SG_REL_ Kombi SG_ 982 LH_Nebel_re_def 1000;
BA_REL_ "GenSigTimeoutTime" BU_SG_REL_ Kombi SG_ 982 LH_Schluss_Brems_re_def 1000;
BA_REL_ "GenSigTimeoutTime" BU_SG_REL_ Kombi SG_ 982 LH_Schluss_Nebel_re_def 1000;
BA_REL_ "GenSigTimeoutTime" BU_SG_REL_ Kombi SG_ 982 LH_SL_BRL_BLK_re_def 1000;
BA_REL_ "GenSigTimeoutTime" BU_SG_REL_ Kombi SG_ 982 LH_Brems_Blk_re_def 1000;
BA_REL_ "GenSigTimeoutTime" BU_SG_REL_ Kombi SG_ 982 LH_Kennzl_def 1000;
BA_REL_ "GenSigTimeoutTime" BU_SG_REL_ Kombi SG_ 982 LH_3_Bremsl_def 1000;
BA_REL_ "GenSigTimeoutTime" BU_SG_REL_ Kombi SG_ 982 LH_Nebel_mi_def 1000;
BA_REL_ "GenSigTimeoutTime" BU_SG_REL_ Kombi SG_ 982 LH_Rueckf_mi_def 1000;
BA_REL_ "GenSigTimeoutTime" BU_SG_REL_ Kombi SG_ 982 LH_Bremsl_li_ges_def 1000;
BA_REL_ "GenSigTimeoutTime" BU_SG_REL_ Kombi SG_ 982 LH_Bremsl_re_ges_def 1000;
VAL_ 1426 KY_ID_Geber1_im_Fzg 0 "inaktiv" 1 "aktiv" ;
VAL_ 1426 KY_ID_Geber2_im_Fzg 0 "inaktiv" 1 "aktiv" ;
VAL_ 1426 KY_ID_Geber3_im_Fzg 0 "inaktiv" 1 "aktiv" ;
VAL_ 1426 KY_ID_Geber4_im_Fzg 0 "inaktiv" 1 "aktiv" ;
VAL_ 1426 KY_Startknopf_Bel 0 "inaktiv" 1 "aktiv" ;
VAL_ 1426 KY_ID_Geber_Suche 0 "inaktiv" 1 "aktiv" ;
VAL_ 1426 KY_Meldungen 0 "keine_Meldung" 1 "Schluessel_nicht_gefunden" 2 "Schluessel_im_Kofferraum" 3 "Schluessel_im_Fahrzeug" 4 "Kessy_defekt" ;
VAL_ 1426 KY_Gong_600 0 "inaktiv" 1 "aktiv" ;
VAL_ 1426 KY_Passiv_Autolock_Menue 0 "inaktiv" 1 "aktiv" ;
VAL_ 1426 KY_Passiv_Autolock_Akt 0 "inaktiv" 1 "aktiv" ;
VAL_ 1426 KY_Passiv_Autolock 0 "inaktiv" 1 "aktiv" ;
VAL_ 1426 KY_Passiv_Autounlock 0 "inaktiv" 1 "aktiv" ;
VAL_ 1426 KY_Gestik_HD 0 "inaktiv" 1 "aktiv" ;
VAL_ 1426 KY_StartStopp_Info 0 "Motorlauf_nicht_notwendig_(Stoppfreigabe)" 1 "Motoranlauf_nicht_zwingend_notwendig_(Stoppverbot,keine_Startanforderung)" 2 "Motoranlauf_zwingend_notwendig_(Startanforderung)" 3 "Systemfehler" ;
VAL_ 1426 KY_Fzg_Verlassen_erkannt 0 "nicht_erkannt" 1 "erkannt" ;
VAL_ 1426 KY_Fzg_Zugang_erkannt 0 "nicht_erkannt" 1 "erkannt" ;
VAL_ 1426 KY_EasyClose_Abbruch 0 "EasyClose_kein_Abbruch" 1 "EasyClose_Abbruch" ;
VAL_ 1426 KY_EasyClose_Status 0 "Lampe_AUS" 1 "Lampe_EIN" 2 "Lampe_NORMAL" 3 "Lampe_HEKTIK" 4 "Akustik_Verweigerung" ;
VAL_ 1426 KY_HD_Auffahrt 0 "keine_Anforderung" 1 "HD_Auffahrt_angefordert" ;
VAL_ 1426 KY_HD_Zufahrt 0 "keine_Anforderung" 1 "HD_Zufahrt_angefordert" ;
VAL_ 1426 KY_Aktive_LFScans 0 "Init" 1 "Entry_Exit_Scan_1" 2 "Entry_Exit_Scan_2" 3 "GO_Scan_1" 4 "GO_Scan_2" 5 "Keyminder_Scan" 6 "ServiceKey1_Scan" 7 "ServiceKey2_Scan" 8 "Komfortlauf_RW_Begrenzer" 9 "Komfortlauf_RW_Begrenzer_EHeck" 10 "RSSI_Scan_EasyClose" 11 "PU_Scan" 12 "Diagnose_Scan" ;
VAL_ 1426 KY_LF_Aktiv 0 "Funktempfang_nicht_aktiv" 1 "LF_Funkempfang_aktiv" ;
VAL_ 1426 KY_AnzKoord_Info 0 "Init" 1 "Keyminder_Suche_erfolgreich" 2 "Keyminder_Suche_negativ" ;
VAL_ 1426 KY_Schluesselposition_9 0 "nicht_gefunden" 1 "im_Innenraum_gefunden" 2 "im_Aussenraum_gefunden_nah" 3 "im_Aussenraum_gefunden_fern" ;
VAL_ 1426 KY_Schluesselposition_1 0 "nicht_gefunden" 1 "im_Innenraum_gefunden" 2 "im_Aussenraum_gefunden_nah" 3 "im_Aussenraum_gefunden_fern" ;
VAL_ 1426 KY_Schluesselposition_2 0 "nicht_gefunden" 1 "im_Innenraum_gefunden" 2 "im_Aussenraum_gefunden_nah" 3 "im_Aussenraum_gefunden_fern" ;
VAL_ 1426 KY_Schluesselposition_3 0 "nicht_gefunden" 1 "im_Innenraum_gefunden" 2 "im_Aussenraum_gefunden_nah" 3 "im_Aussenraum_gefunden_fern" ;
VAL_ 1426 KY_Schluesselposition_4 0 "nicht_gefunden" 1 "im_Innenraum_gefunden" 2 "im_Aussenraum_gefunden_nah" 3 "im_Aussenraum_gefunden_fern" ;
VAL_ 1426 KY_Schluesselposition_5 0 "nicht_gefunden" 1 "im_Innenraum_gefunden" 2 "im_Aussenraum_gefunden_nah" 3 "im_Aussenraum_gefunden_fern" ;
VAL_ 1426 KY_Schluesselposition_6 0 "nicht_gefunden" 1 "im_Innenraum_gefunden" 2 "im_Aussenraum_gefunden_nah" 3 "im_Aussenraum_gefunden_fern" ;
VAL_ 1426 KY_Schluesselposition_7 0 "nicht_gefunden" 1 "im_Innenraum_gefunden" 2 "im_Aussenraum_gefunden_nah" 3 "im_Aussenraum_gefunden_fern" ;
VAL_ 1426 KY_Schluesselposition_8 0 "nicht_gefunden" 1 "im_Innenraum_gefunden" 2 "im_Aussenraum_gefunden_nah" 3 "im_Aussenraum_gefunden_fern" ;
VAL_ 960 RSt_Fahrerhinweise 0 "Init" 1 "Fahreruebernahme_Hinweis_ZAT_Automat_ohne_Gong" 2 "Fahreruebernahme_Hinweis_ZAT_Automat_mit_Gong" 3 "Fahreruebernahme_Hinweis_ZAT_Handschalter_ohne_Gong" 4 "Fahreruebernahme_Hinweis_ZAT_Handschalter_mit_Gong" 5 "Fahreruebernahme_Hinweis_ZAS_Automat_ohne_Gong" 6 "Fahreruebernahme_Hinweis_ZAS_Automat_mit_Gong" 7 "Fahreruebernahme_Hinweis_ZAS_Handschalter_ohne_Gong" 8 "Fahreruebernahme_Hinweis_ZAS_Handschalter_mit_Gong" 9 "RemoteStart_aktiv_ohne_Gong" 10 "RemoteStart_aktiv_mit_Gong" 11 "void" 12 "void" 13 "void" 14 "void" 15 "void" ;
VAL_ 960 ZAS_Kl_S 0 "aus" 1 "S_Kontakt_ein" ;
VAL_ 960 ZAS_Kl_15 0 "aus" 1 "ein" ;
VAL_ 960 ZAS_Kl_X 0 "aus" 1 "ein" ;
VAL_ 960 ZAS_Kl_50_Startanforderung 0 "aus" 1 "KL50_ein_Startwunsch_Fahrer" ;
VAL_ 960 BCM_Remotestart_Betrieb 0 "kein_RS_Betrieb" 1 "RS_Betrieb" ;
VAL_ 960 ZAS_Kl_Infotainment 0 "inaktiv" 1 "aktiv" ;
VAL_ 960 BCM_Remotestart_KL15_Anf 0 "inaktiv" 1 "aktiv" ;
VAL_ 960 BCM_Remotestart_MO_Start 0 "nicht_angefordert" 1 "angefordert" ;
VAL_ 960 KST_Warn_P1_ZST_def 0 "nicht_defekt" 1 "defekt" ;
VAL_ 960 KST_Warn_P2_ZST_def 0 "nicht_defekt" 1 "defekt" ;
VAL_ 960 KST_Fahrerhinweis_1 0 "inaktiv" 1 "aktiv" ;
VAL_ 960 KST_Fahrerhinweis_2 0 "inaktiv" 1 "aktiv" ;
VAL_ 960 BCM_Ausparken_Betrieb 0 "kein_Betrieb" 1 "Ausparkvorgang_aktiv" ;
VAL_ 960 KST_Fahrerhinweis_4 0 "inaktiv" 1 "aktiv" ;
VAL_ 960 KST_Fahrerhinweis_5 0 "inaktiv" 1 "aktiv" ;
VAL_ 960 KST_Fahrerhinweis_6 0 "inaktiv" 1 "aktiv" ;
VAL_ 2463978753 KST_WFS_Fahrfreigabe_Anforderung 0 "Keine" 1 "Uneingeschraenkt" 2 "Eingeschraenkt" ;
VAL_ 2463978753 KST_Sonderzustand_Status 0 "Init" 1 "Uebergang_neue_Anforderung" 2 "Aktiv" 3 "Fehler" ;
VAL_ 2463978753 KST_Sonderzustand_Anforderung 0 "Init" 1 "RemoteStart" 2 "RemoteParkAssist" 3 "IntelligentParkAssist" 4 "TrainiertesParken" 5 "OnlineRemoteUpdate" 6 "Einfrierschutz" 7 "Klemme15ViaDiagnose" 8 "RueckwandklappenSicherungPDC" 9 "ParkHausPilot" 10 "AnhaengerAnkuppelAssistent" 11 "MotorWeiterlaufSchaltung" 31 "Fehler" ;
VAL_ 2463978753 KST_ComfortReadyStatus 0 "aus" 1 "ComfortReadyStatus_ein" ;
VAL_ 2463978753 KST_Freigabe_Zustand 0 "Init" 1 "Kl50_freigegeben" 2 "Kl50_gesperrt" ;
VAL_ 1420 KST_Anf_Klemme_15 0 "nicht_angefordert" 1 "angefordert" ;
VAL_ 1420 KST_Anf_Klemme_50 0 "nicht_angefordert" 1 "angefordert" ;
VAL_ 1420 KST_Anf_Klemme_S 0 "nicht_angefordert" 1 "angefordert" ;
VAL_ 1420 KST_Txt_Werkstatt 0 "Aus" 1 "Ein" ;
VAL_ 1420 KST_Txt_P_Gang 0 "Aus" 1 "Ein" ;
VAL_ 1420 KST_Txt_Panikabschaltung 0 "Aus" 1 "Ein" ;
VAL_ 1420 KST_Anf_Klemmenfreigabe_ELV 0 "nicht_angefordert" 1 "angefordert" ;
VAL_ 1420 KST_Txt_Komfortabschaltung 0 "inaktiv" 1 "aktiv" ;
VAL_ 1420 KST_ZAT_betaetigt 0 "Aus" 1 "Ein" ;
VAL_ 1420 KST_Unterdr_Zuendungsmeldung 0 "keine_Unterdr_der_Zuendungsmeldung" 1 "Unterdr_der_Zuendungsmeldung_aktiv" ;
VAL_ 1420 KST_aut_Abschaltung_Zuendung 0 "Zuendung_wird_bei_Verl_nicht_deaktiviert" 1 "Zuendung_wird_bei_Verl_deaktiviert" ;
VAL_ 1420 KST_Anf_Klemmenfreigabe_WFS 0 "nicht_angefordert" 1 "angefordert" ;
VAL_ 1420 KST_Anf_ZV_Verriegelung 0 "inaktiv" 1 "aktiv" ;
VAL_ 1420 Relais_VoKo_angesteuert 0 "nicht_angesteuert" 1 "angesteuert" ;
VAL_ 1420 RSt_Anforderung_HMS 0 "keine_Anforderung" 1 "halten" 2 "parken" 3 "halten_Standby" 4 "anfahren" 5 "Loesen_ueber_Rampe" 6 "Parken_mit_P" ;
VAL_ 1420 KST_Zuendungswarnung 0 "keine_Ausgabe_Zuendungswarnung" 1 "Ausg_Zuendungswarnung_Stillstand" 2 "Ausg_Zuendungswarnung_Fahrt" 3 "reserved" ;
VAL_ 1420 KST_Anzeige_Klemmenzustand 0 "keine_Anzeige" 1 "Fehler_Infotainment" 2 "Update_in_progress" 3 "Fehler_Infotainment_Fzg_Gesperrt" ;
VAL_ 1646 KL_STL_aktiv 0 "Standlueftung_nicht_aktiv" 1 "Standlueftung_aktiv" ;
VAL_ 1646 KL_STH_aktiv 0 "Standheizung_nicht_aktiv" 1 "Standheizung_aktiv" ;
VAL_ 1646 KL_Solarluefter_aktiv 0 "Solarluefter_nicht_aktiv" 1 "Solarluefter_aktiv__auto" ;
VAL_ 1646 KL_Umluft_Taste 0 "Taste_nicht_gedrueckt" 1 "Taste_gedrueckt" ;
VAL_ 1646 KL_Geblaese_Fond_Status 0 "Geblaese_aus" 1 "Geblaesestufe_10" 2 "Geblaesestufe_20" 3 "Geblaesestufe_30" 4 "Geblaesestufe_40" 5 "Geblaesestufe_50" 6 "Geblaesestufe_60" 7 "Geblaesestufe_70" 8 "Geblaesestufe_80" 9 "Geblaesestufe_90" 10 "Geblaesestufe_100" 14 "Init" 15 "Fehler" ;
VAL_ 1646 KL_STH_Ansteuerung 0 "Aus" 1 "Ein" 2 "Ein_mit_Motorvorwaermung" 3 "Heizleistung_reduziert" ;
VAL_ 1646 KL_Magnetventil 0 "Aus" 1 "Ein" ;
VAL_ 1646 KL_WaPu 0 "Wasserpumpe_aus" 1 "Wasserpumpe_aktiv" ;
VAL_ 1646 KL_Geblaese_Status 0 "Geblaese_aus" 1 "Geblaesestufe_10" 2 "Geblaesestufe_20" 3 "Geblaesestufe_30" 4 "Geblaesestufe_40" 5 "Geblaesestufe_50" 6 "Geblaesestufe_60" 7 "Geblaesestufe_70" 8 "Geblaesestufe_80" 9 "Geblaesestufe_90" 10 "Geblaesestufe_100" 14 "Init" 15 "Fehler" ;
VAL_ 1646 KL_Restwaerme_aktiv 0 "inaktiv" 1 "aktiv" ;
VAL_ 1646 KL_Kompressorkupplung 0 "oeffnen" 1 "schliessen" ;
VAL_ 1646 KL_BCmE_Livetip_Freigabe 0 "Anzeige_Livetip_nicht_zulaessig" 1 "Anzeige_Livetip_zulaessig" ;
VAL_ 1646 KL_ErwVK_Anf 0 "nicht_angefordert" 1 "angefordert" ;
VAL_ 1646 KL_Innen_Temp 253 "nicht_verbaut" 254 "nicht_verfuegbar" 255 "Fehler" ;
VAL_ 1646 KL_I_Geblaese_Fond 255 "Fehler" ;
VAL_ 1646 KL_Anf_AussenspiegelHzg 0 "nicht_angefordert" 1 "angefordert" ;
VAL_ 1646 KL_Heizkreisventilstellung 0 "Init" 1 "Ventilstellung_gem_Anforderung" 2 "Ventilstellung_abweichend_Anf" 3 "Fehler" ;
VAL_ 1646 KL_FSH_Automatikbetrieb 0 "aus" 1 "angefordert_durch_Regelung" ;
VAL_ 1646 KL_SIH_LEH_Verteilung_VL 0 "gleichmaessige_Verteilung" 1 "Sitz_Prio_Hoch" 2 "Sitz_Prio_Mittel" 3 "Sitz_Prio_Niedrig" 4 "Lehne_Prio_Niedrig" 5 "Lehne_Prio_Mittel" 6 "Lehne_Prio_Hoch" ;
VAL_ 1646 KL_SIH_LEL_Verteilung_VL 0 "gleichmaessige_Verteilung" 1 "Sitz_Prio_Hoch" 2 "Sitz_Prio_Mittel" 3 "Sitz_Prio_Niedrig" 4 "Lehne_Prio_Niedrig" 5 "Lehne_Prio_Mittel" 6 "Lehne_Prio_Hoch" ;
VAL_ 1646 KL_SIH_LEH_Verteilung_VR 0 "gleichmaessige_Verteilung" 1 "Sitz_Prio_Hoch" 2 "Sitz_Prio_Mittel" 3 "Sitz_Prio_Niedrig" 4 "Lehne_Prio_Niedrig" 5 "Lehne_Prio_Mittel" 6 "Lehne_Prio_Hoch" ;
VAL_ 1646 KL_SIH_LEL_Verteilung_VR 0 "gleichmaessige_Verteilung" 1 "Sitz_Prio_Hoch" 2 "Sitz_Prio_Mittel" 3 "Sitz_Prio_Niedrig" 4 "Lehne_Prio_Niedrig" 5 "Lehne_Prio_Mittel" 6 "Lehne_Prio_Hoch" ;
VAL_ 949 KL_Drehz_Anh 0 "keine_Anhebung" 1 "Drehzahlanhebung_vom_Motor_angefordert" ;
VAL_ 949 KL_Vorwarn_Komp_ein 0 "Init" 1 "Vorwarnung_Kompressor_ein" ;
VAL_ 949 KL_AC_Schalter 0 "aus" 1 "ein" ;
VAL_ 949 KL_Komp_Moment_alt 1 "veraltet_bzw_Ermittlung_des_Moments_nicht_moeglich__zB_keine_Drehzahl_kein_Kaeltemitteldruck" ;
VAL_ 949 KL_Vorwarn_Zuheizer_ein 0 "keine_Vorwarnung" 1 "Vorwarnung_Zuheizer_ein" ;
VAL_ 949 KL_Zustand 0 "Aus" 1 "Ein" ;
VAL_ 949 KL_Kompressorkupplung_linear 253 "volle_Ansteuerung" 254 "Init__nicht_bedient" ;
VAL_ 949 KL_Charisma_FahrPr 0 "keine_Funktion" 1 "Programm_1" 2 "Programm_2" 3 "Programm_3" 4 "Programm_4" 5 "Programm_5" 6 "Programm_6" 7 "Programm_7" 8 "Programm_8" 9 "Programm_9" 10 "Programm_10" 11 "Programm_11" 12 "Programm_12" 13 "Programm_13" 14 "Programm_14" 15 "Programm_15" ;
VAL_ 949 KL_Charisma_Status 0 "Init" 1 "verfuegbar" 2 "nicht_verfuegbar" 3 "asynchron_durch_Fahrerwunsch" ;
VAL_ 949 KL_nachtr_Stopp_Anf 0 "nicht_angefordert" 1 "angefordert" ;
VAL_ 949 KL_T_Charge 0 "Taster_nicht_betaetigt" 1 "Taster_betaetigt" ;
VAL_ 949 KL_Last_Kompr 255 "Fehler" ;
VAL_ 949 KL_Spannungs_Anf 0 "keine_Anforderung" 1 "Anforderung_Stufe_1" 2 "Anforderung_Stufe_2" 3 "Anforderung_Stufe_3" ;
VAL_ 949 KL_Thermomanagement 0 "keine_Freigabe_TMM__max_Heizbedarf" 1 "kleine_Freigabe_TMM" 2 "mittlere_Freigabe_TMM" 3 "volle_Freigabe_TMM__kein_Heizbedarf" ;
VAL_ 949 KL_StartStopp_Info 0 "Motorlauf_nicht_notwendig_(Stoppfreigabe)" 1 "Motoranlauf_nicht_zwingend_notwendig_(Stoppverbot,keine_Startanforderung)" 2 "Motoranlauf_zwingend_notwendig_(Startanforderung)" 3 "Systemfehler" ;
VAL_ 949 KL_Freilauf_Info 0 "Freilauf_freigegeben" 1 "Uebergang_in_Freilauf_unzulaessig" 2 "Freilauf_nicht_freigegeben_Abbruch" 3 "Freilauf_Anforderung" ;
VAL_ 949 KL_Anf_KL 255 "Fehler" ;
VAL_ 949 KL_el_Zuheizer_Stufe 0 "Aus" 1 "Stufe_1" 2 "Stufe_2" 3 "Stufe_3" ;
VAL_ 949 KL_Ausstattung_Klima 0 "Heizung_elektrisch" 1 "Klimamanuell_elektrisch" 2 "Climatic__1_Zone" 3 "Climatronic__1_Zone" 4 "Climatronic__2_Zonen" 5 "Climatronic__3_Zonen" 6 "Climatronic__4_Zonen" 7 "reserviert" ;
VAL_ 949 KL_Variante_Standheizung 0 "Wasserstandheizung_60_min_Laufzeit" 1 "Luftstandheizung_120_min_Laufzeit" 2 "Wasserstandheizung_120_min_Laufzeit" 3 "Wasser_und_Luftstandheizung_120_min_Laufzeit" ;
VAL_ 949 KL_AirCleaner_aktiv 0 "AirCleaner_nicht_aktiv" 1 "AirCleaner_aktiv" ;
VAL_ 949 KL_Anf_KV 126 "Init" ;
VAL_ 1640 KL_LRH_Taster 0 "nicht_betaetigt" 1 "betaetigt" ;
VAL_ 1640 KL_LRH_Stufe 0 "Stufe_niedrig" 1 "Stufe_mittel" 2 "Stufe_hoch" 3 "AUS" ;
VAL_ 1640 HSH_Taster 0 "nicht_betaetigt" 1 "short_push" 2 "long_push" 3 "tbd" ;
VAL_ 1640 FSH_Taster 0 "nicht_betaetigt" 1 "betaetigt" ;
VAL_ 1640 KL_Zuheizer_Freigabe 0 "keine_Freigabe_Zuheizer" 1 "Zuheizerfreigabe" ;
VAL_ 1640 KL_Beschlagsgefahr 0 "keine_Beschlagsgefahr" 1 "Beschlagsgefahr" ;
VAL_ 1640 KRH_Soll_li 0 "aus" 1 "Stufe_1" 2 "Stufe_2" 3 "Stufe_3" ;
VAL_ 1640 KRH_Soll_re 0 "aus" 1 "Stufe_1" 2 "Stufe_2" 3 "Stufe_3" ;
VAL_ 1640 KL_Geblspng_Soll 0 "0V_Motorspannung" 252 "0V_sofort_Abschalten" 253 "0V_senken_mit_Rampe" 254 "reserviert" 255 "Fehler" ;
VAL_ 1640 KL_Geblspng_Fond_Soll 0 "0V_Motorspannung" 252 "0V_sofort_Abschalten" 253 "0V_senken_mit_Rampe" 254 "reserviert" 255 "Fehler" ;
VAL_ 1640 KL_I_Geblaese 255 "Fehler" ;
VAL_ 1640 KL_Kompressorstrom_soll 1022 "Init" 1023 "Fehler" ;
VAL_ 1640 KL_Umluftklappe_Status 0 "Frischluft" 1 "Teilumluft_10" 2 "Teilumluft_20" 3 "Teilumluft_30" 4 "Teilumluft_40" 5 "Teilumluft_50" 6 "Teilumluft_60" 7 "Teilumluft_70" 8 "Teilumluft_80" 9 "Teilumluft_90" 10 "Umluft" 14 "Init" 15 "Fehler" ;
VAL_ 1640 KL_PTC_Verbauinfo 0 "kein_PTC" 1 "600W_geschaltet" 2 "1000W_geschaltet" 3 "1400W_LIN" ;
VAL_ 2527679635 KL_Voko_Status 0 "aus" 1 "ein" 14 "Init" 15 "Fehler" ;
VAL_ 2527679635 KL_LRH_Soll 0 "nicht_angefordert" 1 "angefordert" ;
VAL_ 2527679635 KL_AL_VR_Anf 0 "Init" 1 "waermer" 2 "kaelter" ;
VAL_ 2527679635 KL_AL_VL_Anf 0 "Init" 1 "waermer" 2 "kaelter" ;
VAL_ 2527679635 KL_AL_HR_Anf 0 "Init" 1 "waermer" 2 "kaelter" ;
VAL_ 2527679635 KL_AL_HL_Anf 0 "Init" 1 "waermer" 2 "kaelter" ;
VAL_ 2527679635 KL_HSH_Soll 0 "nicht_angefordert" 1 "angefordert" ;
VAL_ 2527679635 KL_FSH_Soll 0 "nicht_angefordert" 1 "angefordert" ;
VAL_ 2527679635 KL_ZR_Anforderung 0 "init" 1 "inaktiv" 2 "aktiv" 3 "reserviert" ;
VAL_ 2527679635 KL_VoKo_LED 0 "Aus" 1 "Ein" ;
VAL_ 2527679635 KL_Defrost_LED 0 "Aus" 1 "Ein" ;
VAL_ 2527679635 KL_HSH_LED 0 "Aus" 1 "Ein" ;
VAL_ 2527679635 HSH_Relais_Anf 0 "nicht_angefordert" 1 "angefordert" ;
VAL_ 2527679635 FSH_Status 0 "aus" 1 "ein" 2 "tbd" 3 "Fehler" ;
VAL_ 2527679635 SIH_Stufe_LED_li 0 "Aus" 2 "Stufe_2" 4 "Stufe_4" 6 "Stufe_6" ;
VAL_ 2527679635 SIH_Stufe_LED_re 0 "Aus" 2 "Stufe_2" 4 "Stufe_4" 6 "Stufe_6" ;
VAL_ 2527679635 KL_FSH_LED 0 "Aus" 1 "Ein" ;
VAL_ 2527679635 KL_HUP_aktiv 0 "Aus" 1 "Ein" ;
VAL_ 2527679635 KL_LSH_DBetr_Ein 0 "Dauerbetrieb_nicht_gefordert" 1 "Dauerbetrieb_gefordert" ;
VAL_ 2527679635 KL_LSH_DBetr_Bestaet 0 "kein_Dauerbetrieb" 1 "Dauerbetrieb_bestaetigt" ;
VAL_ 2527679635 KL_Klappe_Status 0 "Init" 1 "Front" 2 "Heck" 3 "Front_u_Heck" 4 "misch_Front_u_Heck" ;
VAL_ 2527679635 KL_LSH_Ansteuerung 0 "Aus" 1 "Ein" 2 "Kombi_Betrieb" 3 "Heizleistung_reduziert" ;
VAL_ 2527679635 KL_Heizstufe_LSH 0 "Init" 1 "Stufe_1" 2 "Stufe_2" 3 "Stufe_3" 4 "Stufe_4" 5 "Stufe_5" 6 "Stufe_6" 7 "Stufe_7" 8 "Stufe_8" 9 "Stufe_9" 10 "Stufe_10" 15 "Fehler" ;
VAL_ 2527679635 KL_LSH_Betriebsdauer 127 "Dauerbetrieb" ;
VAL_ 2527679635 KL_Temp_ZH_Soll 0 "Funk_nicht_verbaut_nicht_aktiv" 255 "Fehler" ;
VAL_ 1505 BCM1_Aussen_Temp_ungef 253 "nicht_verbaut" 254 "Initwert" 255 "Fehler" ;
VAL_ 1505 BCM_Heizungsabsperrventil_Status 0 "HAV_offen" 1 "HAV_geschlossen" 2 "Init_oder_nicht_verbaut" 3 "Fehler" ;
VAL_ 1505 BCM_Heizungspumpe_Status 0 "Pumpe_aus" 1 "Pumpe_aktiv_und_Stauts_iO" 2 "Init_oder_nicht_verbaut" 3 "Fehler" ;
VAL_ 1505 BCM_Kompressorkupplung_Status 0 "Kupplung_offen" 1 "Kupplung_geschlossen" 2 "Init_oder_nicht_verbaut" 3 "Fehler" ;
VAL_ 1505 BCM1_PTC_stufig_Status 0 "Aus" 1 "Stufe_1_aktiv" 2 "Stufe_2_aktiv" 3 "Stufe_3_aktiv" 6 "Init_oder_nicht_verbaut" 7 "Fehler" ;
VAL_ 1505 BCM1_FStatus_Aussentemp_ungef 0 "iO" 1 "niO" ;
VAL_ 1505 BCM1_Kompressorstrom_ist 254 "Init, bzw. nicht verfuegbar" 255 "Fehler" ;
VAL_ 1505 BCM1_OBD_FStatus_ATemp 0 "kein Fehler / Init / nicht verbaut" 1 "KS- (Kurzschluss nach minus)" 2 "KS+ (Kurzschluss nach plus)" 3 "OC (Leitungsunterbrechung)" 4 "OOR+ (Signal zu gross)" 5 "OOR- (Signal zu klein)" 6 "RC+ (Signal unplausibel zu gross)" 7 "RC- (Signal unplausibel zu klein)" 8 "KS+/OC (Kurzschluss nach plus/Unterbrechung)" 9 "KS-/OC  (Kurzschluss nach minus/Unterbrechung)" 10 "KS-/KS+  (Kurzschluss nach minus/plus)" 11 "KS-/KS+/OC (Kurzschluss nach minus/plus/Unterbrechung)" 12 "frei" 13 "frei" 14 "frei" 15 "frei" ;
VAL_ 2549088305 ELV_KompSchutz 0 "inaktiv" 1 "aktiv" ;
VAL_ 2549088305 ELV_Abschaltstufe 0 "keine_Einschraenkung" 1 "Funktionseinschraenkung" ;
VAL_ 2549088305 ELV_Transport_Mode 0 "keine_Einschraenkung" 1 "Funktionseinschraenkung" ;
VAL_ 2549088305 ELV_Nachlauftyp 0 "Komm_bei_KL15_EIN" 1 "Komm_nach_KL15_AUS" 2 "Komm_bei_KL15_AUS" ;
VAL_ 2549088305 KN_ELV_ECUKnockOutTimer 63 "ECUKnockOut_deaktiviert" ;
VAL_ 2549088305 KN_ELV_BusKnockOut 0 "Funktion_nicht_ausgeloest" 1 "Veto_aktiv" 2 "Funktion_ausgeloest" 3 "Funktion_deaktiviert" ;
VAL_ 2549088305 KN_ELV_BusKnockOutTimer 255 "BusKnockOut_deaktiviert" ;
VAL_ 2549088305 NM_ELV_Wakeup 0 "Peripherie_Wakeup_Ursache_nicht_bekannt" 1 "Bus_Wakeup" 2 "KL15_HW" ;
VAL_ 2549088305 KN_ELV_ECUKnockOut 0 "Funktion_nicht_ausgeloest" 1 "Veto_war_aktiv" 2 "Funktion_ausgeloest" 3 "Funktion_deaktiviert" ;
VAL_ 2549088305 KN_ELV_DiagPfad 0 "aktiv" 1 "inaktiv" ;
VAL_ 2549088305 NM_ELV_Lokalaktiv 0 "war_nicht_lokal_aktiv" 1 "war_lokal_aktiv" ;
VAL_ 2549088305 NM_ELV_Subsystemaktiv 0 "Subsystem_war_nicht_lokalaktiv" 1 "war_lokalaktiv" ;
VAL_ 2549088305 ELV_KD_Fehler 0 "Kein KD_Fehler" 1 "KD_Fehler" ;
VAL_ 2549088272 Gateway_KompSchutz 0 "inaktiv" 1 "aktiv" ;
VAL_ 2549088272 Gateway_Abschaltstufe 0 "keine_Einschraenkung" 1 "Funktionseinschraenkung" ;
VAL_ 2549088272 Gateway_Transport_Mode 0 "keine_Einschraenkung" 1 "Funktionseinschraenkung" ;
VAL_ 2549088272 Gateway_Nachlauftyp 0 "Komm_bei_KL15_EIN" 1 "Komm_nach_KL15_AUS" 2 "Komm_bei_KL15_AUS" ;
VAL_ 2549088272 NM_Gateway_Wakeup 0 "Peripherie_Wakeup__Ursache_nicht_bekannt" 1 "Bus_Wakeup" 2 "KL15_HW" 3 "ACAN_Wakeup" 4 "FCAN_Wakeup" 5 "KCAN_Wakeup" 6 "ICAN_Wakeup" 7 "DiagCAN_Wakeup" 8 "ECAN_Wakeup" 9 "Energie_LIN_Wakeup" 10 "Bedien_LIN_Wakeup" 11 "HybridCAN_Wakeup" 12 "Flexray_Wakeup" 13 "MFL_WakeUp" 14 "Ethernet" 15 "DCAN_Wakeup" 16 "K2CAN_Wakeup" 17 "CCAN" 18 "AFSCAN_Wakeup" 19 "LIN1" 20 "LIN2" 21 "LIN3" 22 "LIN4" 23 "LIN5" 24 "LIN6" 25 "FASCAN" 26 "FAS2CAN" 27 "MDKCAN" 32 "FlexRay_Branch1_WakeUp" 33 "FlexRay_Branch2_WakeUp" 34 "FlexRay_Branch3_WakeUp" 35 "FlexRay_Branch4_WakeUp" 36 "FlexRay_Branch5_WakeUp" 37 "FlexRay_Branch6_WakeUp" 38 "FlexRay_Branch7_WakeUp" 39 "FlexRay_Branch8_WakeUp" 40 "FlexRay_Branch9_WakeUp" 41 "FlexRay_Branch10_WakeUp" 42 "FlexRay_Branch11_WakeUp" 43 "FlexRay_Branch12_WakeUp" 44 "FlexRay_Branch13_WakeUp" 45 "FlexRay_Branch14_WakeUp" 46 "FlexRay_Branch15_WakeUp" 47 "FlexRay_Branch16_WakeUp" 128 "Energiemanagement" 129 "Funktionswakeup_OBDC" 130 "Hochvoltenergiemanagement" 131 "CWU_empfangen" 132 "Fuer_Bus_relevanten_FC_empfangen" 133 "OnlineDienst_empfangen" 134 "HV_Aktivieren" 135 "HV_Deaktivieren" 136 "VTS_Suche_DriverCard" 137 "VTS_Hupen_Blinken" 138 "Remote_Vehicle_Status" 139 "Plug_and_Charge" 140 "VTS_Wakeup_Infotainment" 141 "EMHLR" 142 "NFcGW_fordert_OTA_FC_an" 143 "Komponentenschutz" 144 "UserStateServer" 145 "Dimmung" 146 "Kessy" 147 "StandardAussenlicht" 148 "ParkKoordinator" 149 "HVLMDynamicChargingPOI" 150 "HVLMChargingManagementServer" 151 "HVLMExtendedChargingMonitoring" 152 "Zentralverriegelung" 153 "FunctionOnDemand" 154 "IAA" 155 "StandKlimatisierung" 156 "RealTimeMonitor" 157 "Klemmensteuerung" 158 "Fremdladung_erkannt" ;
VAL_ 2549088272 KN_GW_DiagPfad 0 "aktiv" 1 "inaktiv" ;
VAL_ 2549088272 GW_KD_Fehler 0 "kein_KD_Fehler" 1 "KD_Fehler" ;
VAL_ 2549088283 HUD_KompSchutz 0 "inaktiv" 1 "aktiv" ;
VAL_ 2549088283 HUD_Abschaltstufe 0 "keine_Einschraenkung" 1 "Funktionseinschraenkung" ;
VAL_ 2549088283 HUD_Transport_Mode 0 "keine_Einschraenkung" 1 "Funktionseinschraenkung" ;
VAL_ 2549088283 HUD_Nachlauftyp 0 "Komm_bei_KL15_EIN" 1 "Komm_nach_KL15_AUS" 2 "Komm_bei_KL15_AUS" ;
VAL_ 2549088283 KN_HUD_ECUKnockOutTimer 63 "ECUKnockOut_deaktiviert" ;
VAL_ 2549088283 KN_HUD_ECUKnockOut 0 "Funktion_nicht_ausgeloest" 1 "Veto_war_aktiv" 2 "Funktion_ausgeloest" 3 "Funktion_deaktiviert" ;
VAL_ 2549088283 KN_HUD_BusKnockOutTimer 255 "BusKnockOut_deaktiviert" ;
VAL_ 2549088283 NM_HUD_Wakeup 0 "Peripherie_Wakeup_Ursache_nicht_bekannt" 1 "Bus_Wakeup" 2 "KL15_HW" ;
VAL_ 2549088283 KN_HUD_BusKnockOut 0 "Funktion_nicht_ausgeloest" 1 "Veto_aktiv" 2 "Funktion_ausgeloest" 3 "Funktion_deaktiviert" ;
VAL_ 2549088283 KN_HUD_DiagPfad 0 "aktiv" 1 "inaktiv" ;
VAL_ 2549088283 NM_HUD_Lokalaktiv 0 "war_nicht_lokal_aktiv" 1 "war_lokal_aktiv" ;
VAL_ 2549088283 NM_HUD_Subsystemaktiv 0 "war_nicht_lokal_aktiv" 1 "war_lokal_aktiv" ;
VAL_ 2549088283 HUD_KD_Fehler 0 "Kein_KD_Fehler" 1 "KD_Fehler" ;
VAL_ 2549088276 Kombi_KompSchutz 0 "inaktiv" 1 "aktiv" ;
VAL_ 2549088276 Kombi_Abschaltstufe 0 "keine_Einschraenkung" 1 "Funktionseinschraenkung" ;
VAL_ 2549088276 Kombi_Transport_Mode 0 "keine_Einschraenkung" 1 "Funktionseinschraenkung" ;
VAL_ 2549088276 Kombi_Nachlauftyp 0 "Komm_bei_KL15_EIN" 1 "Komm_nach_KL15_AUS" 2 "Komm_bei_KL15_AUS" ;
VAL_ 2549088276 KN_Kombi_ECUKnockOutTimer 63 "ECUKnockOut_deaktiviert" ;
VAL_ 2549088276 KN_Kombi_BusKnockOut 0 "Funktion_nicht_ausgeloest" 1 "Veto_aktiv" 2 "Funktion_ausgeloest" 3 "Funktion_deaktiviert" ;
VAL_ 2549088276 KN_Kombi_BusKnockOutTimer 255 "BusKnockOut_deaktiviert" ;
VAL_ 2549088276 NM_Kombi_Wakeup 0 "Peripherie_Wakeup__Ursache_nicht_bekannt" 1 "Bus_Wakeup" 2 "KL15_HW" 3 "KL30_Reset" 128 "Timer_abgelaufen" ;
VAL_ 2549088276 KN_Kombi_ECUKnockOut 0 "Funktion_nicht_ausgeloest" 1 "Veto_war_aktiv" 2 "Funktion_ausgeloest" 3 "Funktion_deaktiviert" ;
VAL_ 2549088276 KN_KBI_DiagPfad 0 "aktiv" 1 "inaktiv" ;
VAL_ 2549088276 NM_Kombi_Lokalaktiv 0 "war_nicht_lokal_aktiv" 1 "war_lokal_aktiv" ;
VAL_ 2549088276 NM_Kombi_Subsystemaktiv 0 "Subsystem_war_nicht_lokalaktiv" 1 "war_lokalaktiv" ;
VAL_ 2549088276 KBI_KD_Fehler 0 "kein_KD_Fehler" 1 "KD_Fehler" ;
VAL_ 779 KBI_ABS_Lampe 0 "ABS Lampe aus" 1 "ABS Lampe ein" ;
VAL_ 779 KBI_ESP_Lampe 0 "ESP Lampe aus" 1 "ESP Lampe ein" ;
VAL_ 779 KBI_BKL_Lampe 0 "BKL aus" 1 "BKL ein" ;
VAL_ 779 KBI_Airbag_Lampe 0 "Airbag Lampe aus" 1 "Airbag Lampe ein" ;
VAL_ 779 KBI_SILA_gueltig 0 "ungueltig" 1 "gueltig" ;
VAL_ 779 KBI_Vorglueh_System_Lampe 0 "Lampe aus" 1 "Lampe ein" ;
VAL_ 779 KBI_NV_in_Anzeige 0 "NV_nicht_in_Anzeige" 1 "NV_in_Anzeige" ;
VAL_ 779 KBI_Anzeigestatus_ACC 0 "keine_ACC_Anzeige" 1 "ACC_Anzeige_aktiv" ;
VAL_ 779 KBI_Anzeigestatus_GRA 0 "nicht_vorhanden" 1 "Anzeigemoeglichkeit_vorhanden" 2 "reserviert" 3 "Fehler" ;
VAL_ 779 KBI_Oeldruck_Schalter 0 "offen____p_kleiner_pnenn" 1 "geschlossen____p_groessergleich_pnenn" ;
VAL_ 779 KBI_Tankwarnung 0 "Lampe aus" 1 "Lampe ein" ;
VAL_ 779 KBI_MFA_v_Einheit_01 0 "kmh" 1 "mph" ;
VAL_ 779 KBI_im_Stellgliedtest 0 "kein Stellgliedtest" 1 "Kombi im Stellgliedtest" ;
VAL_ 779 KBI_Anzeigefehler_LDW 0 "nicht vorhanden bzw. unterstützt" 1 "Anzeige iO" 2 "Anzeigefehler" 3 "nicht definiert" ;
VAL_ 779 KBI_Tankwarnung_ungueltig 0 "KBI_Tankwarnung_gueltig" 1 "KBI_Tankwarnung_ungueltig" ;
VAL_ 779 KBI_Oeldruckwarnung 0 "inaktiv" 1 "aktiv" ;
VAL_ 779 KBI_Handbremse 0 "nicht_angezogen" 1 "angezogen" ;
VAL_ 779 KBI_PLA_in_Anzeige 0 "PLA_nicht_in_Anzeige" 1 "PLA_in_Anzeige" ;
VAL_ 779 KBI_Anzeigefehler_NV 0 "kein_Anzeigefehler" 1 "Anzeigefehler" ;
VAL_ 779 KBI_Anzeigestatus_LIM 0 "nicht_vorhanden" 1 "Anzeigemoeglichkeit_vorhanden" 2 "reserviert" 3 "Fehler" ;
VAL_ 779 KBI_ARA_in_Anzeige 0 "ARA nicht in Anzeige" 1 "ARA in Anzeige" ;
VAL_ 779 KBI_Taster_Lift 0 "nicht_betaetigt" 1 "betaetigt" ;
VAL_ 779 KBI_Taster_Fahrwerk 0 "nicht_betaetigt" 1 "betaetigt" ;
VAL_ 779 KBI_Audioabsenkung_MIB 0 "keine_Audio_Absenkung" 1 "Audio_Absenkung_Stufe_1" 2 "Audio_Absenkung_Stufe_2" 3 "Audio_Absenkung_Stufe_3" ;
VAL_ 779 KBI_Bestaetigung_ESP_Off 0 "ESP_off_nicht_quittiert" 1 "ESP_off_quittiert" 2 "Abbruch" ;
VAL_ 779 KBI_Anzeigestatus_RHP 0 "nicht_unterstuetzt_oder_Startup" 1 "Anzeige iO" 2 "Anzeigefehler" 3 "nicht definiert" ;
VAL_ 779 KBI_Konsistenz_ACC 0 "ACC Botschaft konsistent" 1 "ACC Botschaft inkonsistent" ;
VAL_ 779 KBI_Fehler_Anzeige_ACC 0 " iO" 1 "Anzeigefehler ACC" ;
VAL_ 779 KBI_Anzeigefehler_SWA 0 "nicht vorhanden bzw. unterstützt" 1 "Anzeige iO" 2 "Anzeigefehler" 3 "nicht definiert" ;
VAL_ 779 KBI_Systemstatus 0 "KBI_IO" 1 "KBI_System_Failure" ;
VAL_ 1719 KBI_Kilometerstand 1048574 "Init" 1048575 "Fehler" ;
VAL_ 1719 KBI_Standzeit_02 131069 "nicht_verfuegbar" 131070 "Init" 131071 "Fehler" ;
VAL_ 1719 KBI_Reserve_Warnung_Sek 0 "Keine_Warnung" 1 "Sekundaere_Reservewarnung" ;
VAL_ 1719 KBI_RDK_Kalibrier_Anf 0 "keine_Kalibrieranforderung" 1 "Kalibrieranforderung" ;
VAL_ 1719 KBI_Inhalt_Tank 126 "Init" 127 "Fehler" ;
VAL_ 1719 KBI_FStatus_Tank 0 "Tankfüllstand i.O." 1 "Tankfüllstand n.i.O" ;
VAL_ 1719 KBI_aktive_Laengsfunktion_02 0 "Init" 1 "Speedlimiter" 2 "GRA_oder_ACC" 3 "PACCh" 4 "HDC" 5 "p_GRA" 6 "p_Lim" 7 "ACC_im_GRA_Modus" 8 "Travel_Assist" 9 "RHP" ;
VAL_ 1719 KBI_FoD_PopUP_Quittiert 0 "nicht_quittiert" 1 "Meldung_quittiert" ;
VAL_ 1719 KBI_GRA_im_ACC 0 "GRA_im_ACC_nicht_ausgewaehlt" 1 "GRA_im_ACC_ausgewaehlt" ;
VAL_ 1719 KBI_Oelwechsel_durchgefuehrt 0 "Oelwechsel_nicht_durchgefuehrt" 1 "Oelwechsel_durchgefuehrt" ;
VAL_ 1719 KBI_QBit_Aussen_Temp_gef 0 "gueltiger_Wert" 1 "Ersatz_Init_oder_Fehlerwert" ;
VAL_ 1719 KBI_Aussen_Temp_gef 253 "nicht verbaut" 254 "Init" 255 "Fehler" ;
VAL_ 1720 KBI_Variante_USA 0 "keine USA-Variante" 1 "USA-Variante" ;
VAL_ 1720 KBI_Variante 0 "Zeiger Kombiinstrument" 1 "Volldisplay Kombiinstrument" ;
VAL_ 1720 KBI_GAP_Warn_Zeit_abgelaufen 0 "Zaehler_nicht_abgelaufen" 1 "Zaehler_abgelaufen" ;
VAL_ 1720 KBI_Quittierung_Naesse 0 "nicht_quittiert" 1 "quittiert" ;
VAL_ 1720 KBI_BCmE_aktiv 0 "Anzeige_nicht_aktiv" 1 "Anzeige_aktiv" ;
VAL_ 1720 KBI_Sparhinweis_quittiert 0 "nicht_quittiert" 1 "quittiert" ;
VAL_ 1720 KBI_Tankfuellstand_Prozent 126 "Init" 127 "Fehler" ;
VAL_ 1720 KBI_Nachtanken_erkannt 0 "Geberbetrieb" 1 "Nachtankmodus" ;
VAL_ 1720 KBI_Tankinhalt_hochaufl 16382 "Init" 16383 "Fehler" ;
VAL_ 1720 KBI_Max_Tankinhalt 254 "Init" 255 "Fehler" ;
VAL_ 1720 KBI_Quittierung_cAQP 0 "nicht_quittiert" 1 "quittiert" ;
VAL_ 2527679639 KBI_Weg_Zaehler_F 0 "kein Fehler" 1 "Fehler" ;
VAL_ 2527679639 KBI_Anzeige_ID_quittiert 0 "Init" ;
VAL_ 2527679639 KBI_Min_Tankinhalt 126 "Init" 127 "Fehler" ;
VAL_ 2527679639 KBI_Jokerkey 0 "nicht_betaetigt" 1 "betaetigt" ;
VAL_ 2527679639 KBI_RS_Druck_uebernehmen 0 " Druck für Rundstreckenmodue nicht uebernehmen" 1 " Druck für Rundstreckenmodus uebernehmen" ;
VAL_ 2527679639 KBI_RS_Druckauswahl_Aktiv 0 "inaktiv" 1 "aktiv" ;
VAL_ 2527679639 KBI_RS_Mode_fortsetzen 0 "Rundstreckenmodus_nicht_fortsetzen" 1 "Rundstreckenmodus_fortsetzen" ;
VAL_ 2527679639 KBI_Rundstreckenmodus 0 "nicht_angefordert" 1 "angefordert" ;
VAL_ 2527679639 AuthTime_Trigger_Distribution 0 "inaktiv" 1 "aktiv" ;
VAL_ 2527679639 KBI_FoD_VirtualCockpitPlus_State 0 "Init" 1 "locked" 2 "unlocked" ;
VAL_ 2589283631 KBI_Tankinhalt_roh 2046 "Init" 2047 "Fehler" ;
VAL_ 2589283631 KBI_BC_Reset_E1 0 "SG_Reset" 1 "Reset_Zaehler" 2 "Reset_Zaehler" 3 "Reset_Zaehler" 4 "Reset_Zaehler" 5 "Reset_Zaehler" 6 "Reset_Zaehler" 7 "Init" ;
VAL_ 2589283631 KBI_BC_Reset_E2 0 "SG_Reset" 1 "Reset_Zaehler" 2 "Reset_Zaehler" 3 "Reset_Zaehler" 4 "Reset_Zaehler" 5 "Reset_Zaehler" 6 "Reset_Zaehler" 7 "Init" ;
VAL_ 2589283631 KBI_BC_Reset_E3 0 "SG_Reset" 1 "Reset_Zaehler" 2 "Reset_Zaehler" 3 "Reset_Zaehler" 4 "Reset_Zaehler" 5 "Reset_Zaehler" 6 "Reset_Zaehler" 7 "Init" ;
VAL_ 2527679656 KBI_StartupAnimation 0 "Init" 1 "StartMeasureDelay" 2 "RequestStartAnimation" 3 "RequestCancelAnimation" 4 "CIAnimationStarted" 5 "CIAnimationStopped" ;
VAL_ 2589283935 KBI_View1 0 "false" 1 "true" ;
VAL_ 2589283935 KBI_View2 0 "false" 1 "true" ;
VAL_ 2589283935 KBI_View3 0 "false" 1 "true" ;
VAL_ 2589283935 KBI_View4 0 "false" 1 "true" ;
VAL_ 2589283935 KBI_View5 0 "false" 1 "true" ;
VAL_ 2589283935 KBI_View6 0 "false" 1 "true" ;
VAL_ 2589283935 KBI_View7 0 "false" 1 "true" ;
VAL_ 2589283935 KBI_View8 0 "false" 1 "true" ;
VAL_ 2589283935 KBI_View9 0 "false" 1 "true" ;
VAL_ 2589283935 KBI_View10 0 "false" 1 "true" ;
VAL_ 2589283935 KBI_View11 0 "false" 1 "true" ;
VAL_ 2589283935 KBI_View12 0 "false" 1 "true" ;
VAL_ 2589283935 KBI_View13 0 "false" 1 "true" ;
VAL_ 2589283935 KBI_View14 0 "false" 1 "true" ;
VAL_ 2589283935 KBI_View15 0 "false" 1 "true" ;
VAL_ 2589283935 KBI_View16 0 "false" 1 "true" ;
VAL_ 2589283935 KBI_View17 0 "false" 1 "true" ;
VAL_ 2589283935 KBI_View18 0 "false" 1 "true" ;
VAL_ 2589283935 KBI_View19 0 "false" 1 "true" ;
VAL_ 2589283935 KBI_View20 0 "false" 1 "true" ;
VAL_ 2589283935 KBI_View21 0 "false" 1 "true" ;
VAL_ 2589283935 KBI_View22 0 "false" 1 "true" ;
VAL_ 2589283935 KBI_View23 0 "false" 1 "true" ;
VAL_ 2589283935 KBI_View24 0 "false" 1 "true" ;
VAL_ 2589283935 KBI_Curr_View 0 "init" 1 "View1" 2 "View2" 3 "View3" 4 "View4" 5 "View5" 6 "View6" 7 "View7" 8 "View8" 9 "View9" 10 "View10" 11 "View11" 12 "View12" 13 "View13" 14 "View14" 15 "View15" 16 "View16" 17 "View17" 18 "View18" 19 "View19" 20 "View20" 21 "View21" 22 "View22" 23 "View23" 24 "View24" 25 "reserved" 26 "reserved" 27 "reserved" 28 "reserved" 29 "reserved" 30 "reserved" 31 "reserved" ;
VAL_ 2589283935 KBI_Sec_View_Status 0 "init" 1 "Deaktiviert" 2 "Aktiviert" ;
VAL_ 1614 KBI_HUD_Data_01 0 "Init" ;
VAL_ 1614 KBI_HUD_Data_02 0 "Init" ;
VAL_ 1614 KBI_HUD_Data_03 0 "Init" ;
VAL_ 1614 KBI_HUD_Data_04 0 "Init" ;
VAL_ 1614 KBI_HUD_Data_05 0 "Init" ;
VAL_ 1614 KBI_HUD_Data_06 0 "Init" ;
VAL_ 1614 KBI_HUD_Data_07 0 "Init" ;
VAL_ 1614 KBI_HUD_Data_08 0 "Init" ;
VAL_ 919 LDW_Gong 0 "kein akustisches Signal" 1 "Gong_1" 2 "Gong_2" 3 "Gong_3" ;
VAL_ 919 LDW_Frueh_Spaet 0 "frueh_frueh_aktiv" 1 "frueh_spaet_aktiv" 2 "spaet_spaet_aktiv" 3 "Fehler" ;
VAL_ 919 LDW_Texte 0 "keine_Anzeige" 1 "Laneassist_zur_Zeit_n_verfuegbar" 2 "Laneassist_Systemfehler" 3 "Laneassist_zur_Zeit_keine_SSicht" 4 "Laneassist_Fahreruebernahme" 5 "Laneassist_n_verfuegbar_FoD" 6 "Emergency_Alert_Fahreruebernahme" 7 "Laneassist_FahreruebernahmeLeise" 8 "Laneassist_FahreruebernahmeStumm" 9 "EA_Fahrstreifenwechsel" 10 "Laneassist_Deaktiviert" 11 "Laneassist_Fahreruebernahme_hoch" 12 "Laneassist_mittig_fahren" 13 "Laneassist_adaptiv_aktiv" 14 "Laneassist_adaptiv_deaktiv" 15 "Systgr_Fzgfueh_sofort_uebernehm" ;
VAL_ 919 LDW_Seite_DLCTLC 0 "links" 1 "rechts" ;
VAL_ 919 LDW_Status_Anzeige 0 "Init_keine_Anzeige" 1 "Lenkeingriff" 2 "Deaktiviert" 3 "Passiv" 4 "Aktiv" 5 "Passiv_automatisch" 6 "nicht_definiert" 7 "nicht_definiert" ;
VAL_ 919 LDW_Lernmodus_seitenabhaengig 0 "links_aus__rechts_aus" 1 "HCCA_links_an__rechts_an" 2 "HCCA_links_an__rechts_Warnung" 3 "HCCA_links_Warnung__rechts_an" 4 "links_gestrichelt_rechts_Warnung" 5 "links_outlined__rechts_outlined" 6 "links_outlined__rechts_an" 7 "links_outlined__rechts_Warnung" 8 "links_Warnung_rechts_gestrichel" 9 "links_an__rechts_outlined" 10 "links_an__rechts_an" 11 "links_an__rechts_Warnung" 12 "links_und_rechts_gestrichelt" 13 "links_Warnung__rechts_outlined" 14 "links_Warnung__rechts_an" 15 "links_Warnung__rechts_Warnung" ;
VAL_ 919 LDW_TLC 31 "Init" ;
VAL_ 919 HC_Uss_Anforderung 0 "Ultraschallsensoren Aus" 1 "Ultraschallsensoren An" ;
VAL_ 919 aLDW_FoD_Status 0 "Init" 1 "Funktion_inaktiv" 2 "Funktion_aktiv" ;
VAL_ 919 LDW_Status_LED_gelb 0 "LDW-Status gelb aus" 1 "LDW-Status gelb aktiv" ;
VAL_ 919 LDW_Status_LED_gruen 0 "LDW-Status gruen aus" 1 "LDW-Status gruen aktiv" ;
VAL_ 810 EPS_SpannungsAnf 0 "keine_Anforderung" 1 "Anforderung_Stufe1" 2 "Anforderung_Stufe2" 3 "Anforderung_Stufe3" ;
VAL_ 810 EPS_Endanschlag 0 "Init_bzw_Defaultlenkhub" 1 "Lenkhubaufweitung_1" 2 "EA_nicht_angelernt_bzw_Initialisierung_nicht_abgeschlossen" 3 "Fehler" ;
VAL_ 810 EPS_Akustiksignal 0 "Akustiksignal_nicht_aktiv" 1 "Akustiksignal_aktiv" ;
VAL_ 810 EPS_Fehlerlampe 0 "Lampe_aus" 1 "Lampe_ein" ;
VAL_ 810 EPS_Warnungen 0 "kein_Text" 1 "Text_1" 2 "Text_2" 3 "Text_3" 4 "Text_4" 5 "Text_5" ;
VAL_ 810 EPS_PLA_Status 0 "EPS_PLA_Deaktiv" 1 "EPS_PLA_Init" 2 "EPS_PLA_Fehler_mit_Eintrag" 3 "reserviert" 4 "reserviert" 5 "reserviert" 6 "EPS_PLA_Lenkwinkel_aktiv" 7 "EPS_PLA_Abgewiesen" 8 "EPS_PLA_Funktionsbereit" 9 "reserviert" 10 "EPS_PLA_Abbruch" 11 "reserviert" 12 "reserviert" 13 "reserviert" 14 "reserviert" 15 "reserviert" ;
VAL_ 810 EPS_Charisma_FahrPr 0 "keine_Funktion" 1 "Programm_1" 2 "Programm_2" 3 "Programm_3" 4 "Programm_4" 5 "Programm_5" 6 "Programm_6" 7 "Programm_7" 8 "Programm_8" 9 "Programm_9" 10 "Programm_10" 11 "Programm_11" 12 "Programm_12" 13 "Programm_13" 14 "Programm_14" 15 "Programm_15" ;
VAL_ 810 EPS_Charisma_Status 0 "Init" 1 "verfuegbar" 2 "nicht_verfuegbar" 3 "asynchron_durch_Fahrerwunsch" ;
VAL_ 810 EPS_VZ_Zst_Offset_Geradeaus 0 "pos_VZ" 1 "neg_VZ" ;
VAL_ 810 EPS_Lenkerposition 0 "unbekannt" 1 "Linkslenker" 2 "Rechtslenker" ;
VAL_ 810 EPS_Anf_KL 0 "keine_Anforderung" 1 "Anforderung_Kuehlung" ;
VAL_ 810 EPS_ARA_Status 0 "EPS_ARA_Deaktiv" 1 "EPS_ARA_Init" 2 "EPS_ARA_Fehler_mit_Eintrag" 3 "reserviert" 4 "reserviert" 5 "reserviert" 6 "EPS_ARA_Lenkwinkel_aktiv" 7 "EPS_ARA_Abgewiesen" 8 "EPS_ARA_Funktionsbereit" 9 "reserviert" 10 "EPS_ARA_Abbruch" 11 "reserviert" 12 "reserviert" 13 "reserviert" 14 "reserviert" 15 "reserviert" ;
VAL_ 810 EPS_Zst_Offset_Geradeaus 510 "Init" 511 "Fehler" ;
VAL_ 981 BCM1_Kurvenlicht_links_Anf 0 "linkes_Kurvenlicht/Abbiegelicht_durch_BCM1_nicht_angesteuert" 1 "linkes_Kurven/Abbiegelicht_durch_BCM1_angesteuert" ;
VAL_ 981 BCM1_Kurvenlicht_rechts_Anf 0 "rechtes_Kurvenlicht/Abbiegelicht_durch_BCM1_nicht_angesteuert" 1 "rechtes_Kurvenlicht/Abbiegelicht_durch_BCM1_angesteuert" ;
VAL_ 981 BCM1_Standlicht_Anf 0 "Licht_nicht_angefordert" 1 "Licht ist einzuschalten" ;
VAL_ 981 BCM1_Abblendlicht_Anf 0 "Licht_nicht_angefordert" 1 "Licht ist einzuschalten" ;
VAL_ 981 BCM1_Fernlicht_Anf 0 "Licht_nicht_angefordert" 1 "Licht ist einzuschalten" ;
VAL_ 981 BCM1_Nebellicht_Anf 0 "Licht_nicht_angefordert" 1 "Licht ist einzuschalten" ;
VAL_ 981 BCM1_Parklicht_li_Anf 0 "Licht_nicht_angefordert" 1 "Licht ist einzuschalten" ;
VAL_ 981 BCM1_Parklicht_re_Anf 0 "Licht_nicht_angefordert" 1 "Licht ist einzuschalten" ;
VAL_ 981 BCM1_Nebelschluss_Ahg_Anf 0 "Licht_nicht_angefordert" 1 "Licht ist einzuschalten" ;
VAL_ 981 BCM1_Nebelschluss_Fzg_Anf 0 "Licht_nicht_angefordert" 1 "Licht_ist_einzuschalten" ;
VAL_ 981 BCM1_Schlusslicht_Anf 0 "Licht_nicht_angefordert" 1 "Licht ist einzuschalten" ;
VAL_ 981 BCM_Rueckfahrlicht_Anf 0 "Licht_nicht_angefordert" 1 "Licht_angefordert" ;
VAL_ 981 BCM1_Signaturlicht_Anf 0 "Licht_nicht_angefordert" 1 "Licht_ist_einzuschalten" ;
VAL_ 981 BCM1_Umfeldleuchten_Anf 0 "Licht_nicht_angefordert" 1 "Licht_ist_einzuschalten" ;
VAL_ 981 BCM1_Tagfahrlicht_Anf 0 "Licht_nicht_angefordert" 1 "Licht ist einzuschalten" ;
VAL_ 981 BCM1_Regenlicht_Anf 0 "Licht_nicht_angefordert" 1 "Licht ist einzuschalten" ;
VAL_ 981 BCM1_Autobahnlicht_Anf 0 "Licht_nicht_angefordert" 1 "Licht ist einzuschalten" ;
VAL_ 981 BCM1_Touristen_Licht_Anf 0 "Licht_nicht_angefordert" 1 "Anforderung von Touristenlicht" ;
VAL_ 981 BCM1_CH_aktiv 0 "Inaktiv" 1 "Aktiv" ;
VAL_ 981 BCM1_LH_aktiv 0 "Inaktiv" 1 "Aktiv" ;
VAL_ 981 BCM1_Gleitende_Leuchtw_Anf 0 "Aus" 1 "Ein" ;
VAL_ 981 BCM1_GLW_Fernlicht_Anf 0 "Aus" 1 "Ein" ;
VAL_ 981 BCM1_Adaptive_Lichtvert_Anf 0 "Aus" 1 "Ein" ;
VAL_ 981 BCM1_Animationssperrung 0 "keine_Sperrung" 1 "Sperrung" ;
VAL_ 981 BCM1_CH_LH_aktiv 0 "Comming_Home_Bzw._Leaving_Home_nicht_aktiv" 1 "Comming Home bzw. Leaving Home aktiv" ;
VAL_ 981 BCM1_Allwetterlicht_Anf 0 "Licht_nicht_angefordert" 1 "Licht_ist_einzuschalten" ;
VAL_ 981 TFL_Matrix_Variante01_Anf 0 "nicht_angefordert" 1 "angefordert" ;
VAL_ 981 TFL_Matrix_Variante02_Anf 0 "nicht_angefordert" 1 "angefordert" ;
VAL_ 981 TFL_Matrix_Variante03_Anf 0 "nicht_angefordert" 1 "angefordert" ;
VAL_ 981 TFL_Matrix_Variante04_Anf 0 "nicht_angefordert" 1 "angefordert" ;
VAL_ 982 BCM2_Bremsl_durch_ECD_invers 0 "Bremslicht_durch_ECD_aktiv" 1 "Bremslicht_ist_aus" ;
VAL_ 982 BCM2_Bremsl_durch_ECD 0 "Bremslicht_ist_aus" 1 "Bremslicht_durch_ECD_aktiv" ;
VAL_ 982 LH_Aussenlicht_def 0 "OK" 1 "defekt" ;
VAL_ 982 LH_Standlicht_H_aktiv 1 "Standlicht hinten aktiv" ;
VAL_ 982 LH_Parklicht_HL_aktiv 0 "nicht aktiv" 1 "Parklicht hinten links aktiv" ;
VAL_ 982 LH_Parklicht_HR_aktiv 0 "nicht aktiv" 1 "Parklicht hinten rechts aktiv" ;
VAL_ 982 LH_Bremslicht_H_aktiv 1 "Bremslicht hinten aktiv" ;
VAL_ 982 LH_Nebelschluss_aktiv 0 "nicht aktiv" 1 "aktiv" ;
VAL_ 982 LH_Rueckfahrlicht_aktiv 0 "nicht_aktiv" 1 "aktiv" ;
VAL_ 982 LH_Blinker_HL_akt 1 "Blinker hinten links aktiv" ;
VAL_ 982 LH_Blinker_HR_akt 1 "Blinker hinten rechts aktiv" ;
VAL_ 982 LH_Blinker_li_def 0 "OK" 1 "Blinker hinten links defekt" ;
VAL_ 982 LH_Bremsl_li_def 0 "OK" 1 "mindestens ein Bremslicht hinten links defekt" ;
VAL_ 982 LH_Schlusslicht_li_def 0 "OK" 1 "mindestens ein Schlusslicht hinten links defekt" ;
VAL_ 982 LH_Rueckf_li_def 0 "OK" 1 "Rückfahrlicht hinten links defekt" ;
VAL_ 982 LH_Nebel_li_def 0 "OK" 1 "Nebelschlusslicht_hinten_links_defekt" ;
VAL_ 982 LH_Schluss_Brems_Nebel_li_def 0 "iO" 1 "defekt" ;
VAL_ 982 LH_Schluss_Brems_Nebel_re_def 0 "iO" 1 "defekt" ;
VAL_ 982 LH_Zusatzschlussl_def 0 "OK" 1 "mindestens_ein_Zusatzschlusslicht_defekt" ;
VAL_ 982 LH_Schluss_Brems_li_def 0 "OK" 1 "defekt" ;
VAL_ 982 LH_Schluss_Nebel_li_def 0 "OK" 1 "defekt" ;
VAL_ 982 LH_SL_BRL_BLK_li_def 0 "OK" 1 "defekt" ;
VAL_ 982 LH_Brems_Blk_li_def 0 "OK" 1 "defekt" ;
VAL_ 982 LH_Diag_Status_re_def 0 "OK" 1 "Aussenlict_Diagnose_Systemstoerung_rechts" ;
VAL_ 982 LH_Diag_Status_li_def 0 "OK" 1 "Aussenlicht_Diagnose_Systemstoerung_links" ;
VAL_ 982 LH_Diag_LED_li_def 0 "OK" 1 "Heckleuchte_links_defekt" ;
VAL_ 982 LH_Diag_LED_re_def 0 "OK" 1 "Heckleuchte_rechts_defekt" ;
VAL_ 982 LH_Blinker_re_def 0 "OK" 1 "Blinker hinten rechts defekt" ;
VAL_ 982 LH_Bremsl_re_def 0 "OK" 1 "mindestens ein Bremslicht hinten rechts defekt" ;
VAL_ 982 LH_Schlusslicht_re_def 0 "OK" 1 "mindestens_ein_Schlusslicht_hinten_rechts_defekt" ;
VAL_ 982 LH_Rueckf_re_def 0 "OK" 1 "Rückfahrlicht hinten rechts defekt" ;
VAL_ 982 LH_Nebel_re_def 0 "OK" 1 "Nebelschlusslicht hinten rechts defekt" ;
VAL_ 982 LH_Schluss_Brems_re_def 0 "OK" 1 "defekt" ;
VAL_ 982 LH_Schluss_Nebel_re_def 0 "OK" 1 "defekt" ;
VAL_ 982 LH_SL_BRL_BLK_re_def 0 "OK" 1 "defekt" ;
VAL_ 982 LH_Brems_Blk_re_def 0 "OK" 1 "defekt" ;
VAL_ 982 LH_Kennzl_def 0 "OK" 1 "Kennzeichenbeleuchtung hinten defekt" ;
VAL_ 982 LH_3_Bremsl_def 0 "OK" 1 "hochgesetzte  Bremsleuchte defekt" ;
VAL_ 982 LH_Nebel_mi_def 0 "OK" 1 " Nebelschlusslicht hinten Mitte defekt" ;
VAL_ 982 LH_Rueckf_mi_def 0 "OK" 1 "Rückfahllicht Mitte defekt" ;
VAL_ 982 LH_Bremsl_li_ges_def 0 "OK" 1 "Alle Bremslichter hinten links defekt" ;
VAL_ 982 LH_Bremsl_re_ges_def 0 "OK" 1 "Alle Bremslichter hinten rechts defekt" ;
